VERSION ""

NS_ :

BS_:

BU_: Tester TirePressureController
VAL_TABLE_ FMI 0 "Above normal (most severe)" 1 "Below normal (most severe)" 2 "Data erratic" 3 "Voltage above normal" 4 "Voltage below normal" 5 "Current below normal" 6 "Current above normal" 7 "Mechanical system not responding" 8 "Abnormal frequency" 9 "Abnormal update rate" 10 "Abnormal rate of change" 11 "Root cause not known" 12 "Bad intelligent device" 13 "Out of calibration" 14 "Special intstructions" 15 "Above normal (least severe)" 16 "Above normal (moderately severe)" 17 "Below normal (least severe)" 18 "Below normal (moderately severe)" 19 "Received network data in error" 20 "Data drifted high" 21 "Data drifted low" 31 "Condition exists" ;

BO_ 2565799678 AC: 8 TirePressureController
 SG_ VehicleSystem5 m5 : 49|7@1+ (1,0) [0|127] "" Vector__XXX
 SG_ VehicleSystem4 m4 : 49|7@1+ (1,0) [0|127] "" Vector__XXX
 SG_ VehicleSystem3 m3 : 49|7@1+ (1,0) [0|127] "" Vector__XXX
 SG_ VehicleSystem2 m2 : 49|7@1+ (1,0) [0|127] "" Vector__XXX
 SG_ VehicleSystem1 m1 : 49|7@1+ (1,0) [0|127] "" Vector__XXX
 SG_ VehicleSystem m0 : 49|7@1+ (1,0) [0|127] "" Vector__XXX
 SG_ ReservedBit : 48|1@1+ (1,0) [0|0] "" Vector__XXX
 SG_ ArbitraryAddressCapable : 63|1@1+ (1,0) [0|1] "" Vector__XXX
 SG_ IndustryGroup M : 60|3@1+ (1,0) [0|7] "" Vector__XXX
 SG_ VehicleSystemInstance : 56|4@1+ (1,0) [0|15] "" Vector__XXX
 SG_ Function : 40|8@1+ (1,0) [0|255] "" Vector__XXX
 SG_ FunctionInstance : 35|5@1+ (1,0) [0|31] "" Vector__XXX
 SG_ ECUInstance : 32|3@1+ (1,0) [0|7] "" Vector__XXX
 SG_ ManufacturerCode : 21|11@1+ (1,0) [0|2047] "" Vector__XXX
 SG_ IdentityNumber : 0|21@1+ (1,0) [0|2097152] "" Vector__XXX

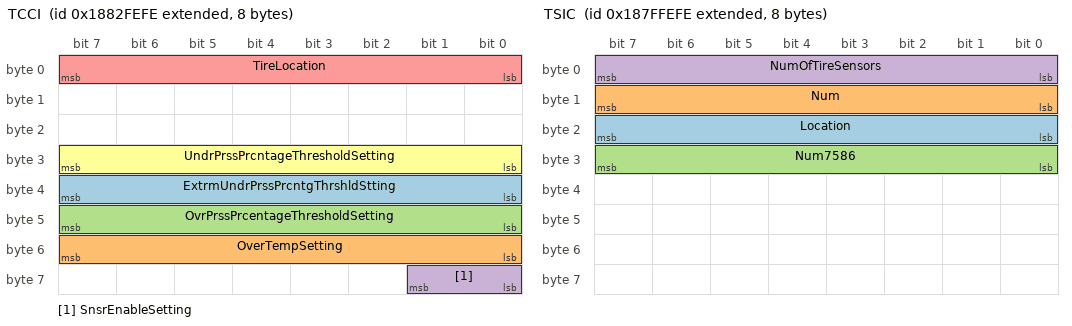
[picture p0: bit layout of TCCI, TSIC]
BO_ 2558721790 TCCI: 8 TirePressureController
 SG_ ExtrmUndrPrssPrcntgThrshldStting : 32|8@1+ (0.5,0) [0|125] "%" Vector__XXX
 SG_ OverTempSetting : 48|8@1+ (1,-40) [-40|210] "°C" Vector__XXX
 SG_ OvrPrssPrcentageThresholdSetting : 40|8@1+ (0.5,0) [0|125] "%" Vector__XXX
 SG_ SnsrEnableSetting : 56|2@1+ (1,0) [0|3] "" Vector__XXX
 SG_ TireLocation : 0|8@1+ (1,0) [0|255] "" Vector__XXX
 SG_ UndrPrssPrcntageThresholdSetting : 24|8@1+ (0.5,0) [0|125] "%" Vector__XXX

BO_ 2558525182 TSIC: 8 TirePressureController
 SG_ Location : 16|8@1+ (1,0) [0|255] "" Vector__XXX
 SG_ Num : 8|8@1+ (1,0) [0|250] "" Vector__XXX
 SG_ Num7586 : 24|8@1+ (1,0) [0|255] "" Vector__XXX
 SG_ NumOfTireSensors : 0|8@1+ (1,0) [0|250] "" Vector__XXX

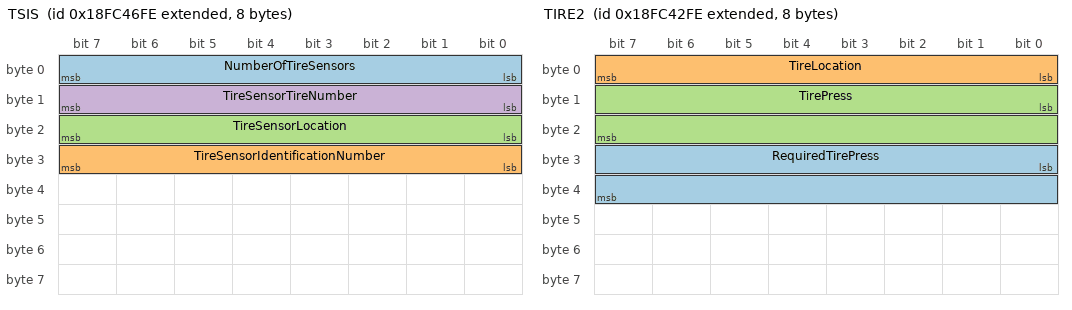
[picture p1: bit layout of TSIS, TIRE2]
BO_ 2566670078 TSIS: 8 TirePressureController
 SG_ NumberOfTireSensors : 0|8@1+ (1,0) [0|250] "" Vector__XXX
 SG_ TireSensorIdentificationNumber : 24|8@1+ (1,0) [0|255] "" Vector__XXX
 SG_ TireSensorLocation : 16|8@1+ (1,0) [0|255] "" Vector__XXX
 SG_ TireSensorTireNumber : 8|8@1+ (1,0) [0|250] "" Vector__XXX

BO_ 2566669054 TIRE2: 8 TirePressureController
 SG_ RequiredTirePress : 24|16@1+ (1,0) [0|64255] "kPa" Vector__XXX
 SG_ TireLocation : 0|8@1+ (1,0) [0|255] "" Vector__XXX
 SG_ TirePress : 8|16@1+ (1,0) [0|64255] "kPa" Vector__XXX

BO_ 2566836734 DM09: 8 TirePressureController

BO_ 2566702846 DM57: 8 TirePressureController
 SG_ EngOBDWarmUpSequence : 0|2@1+ (1,0) [0|3] "" Vector__XXX

BO_ 2566703102 DM56: 208 TirePressureController
 SG_ CertificationEngineFamilyName : 64|64@1+ (1,0) [0|255] "" Vector__XXX
 SG_ ModelYear : 0|64@1+ (1,0) [0|255] "" Vector__XXX

BO_ 2566705918 DM54: 22 TirePressureController
 SG_ AmberWarningLampStatus : 2|2@1+ (1,0) [0|3] "" Vector__XXX
 SG_ DTC1 : 16|32@1+ (1,0) [0|4294967295] "" Vector__XXX
 SG_ DTC2 : 48|32@1+ (1,0) [0|4294967295] "" Vector__XXX
 SG_ DTC3 : 80|32@1+ (1,0) [0|4294967295] "" Vector__XXX
 SG_ DTC4 : 112|32@1+ (1,0) [0|4294967295] "" Vector__XXX
 SG_ DTC5 : 144|32@1+ (1,0) [0|4294967295] "" Vector__XXX
 SG_ FlashAmberWarningLamp : 10|2@1+ (1,0) [0|3] "" Vector__XXX
 SG_ FlashMalfuncIndicatorLamp : 14|2@1+ (1,0) [0|3] "" Vector__XXX
 SG_ FlashProtectLamp : 8|2@1+ (1,0) [0|3] "" Vector__XXX
 SG_ FlashRedStopLamp : 12|2@1+ (1,0) [0|3] "" Vector__XXX
 SG_ MalfunctionIndicatorLampStatus : 6|2@1+ (1,0) [0|3] "" Vector__XXX
 SG_ ProtectLampStatus : 0|2@1+ (1,0) [0|3] "" Vector__XXX
 SG_ RedStopLampState : 4|2@1+ (1,0) [0|3] "" Vector__XXX

BO_ 2566705662 DM53: 22 TirePressureController
 SG_ AmberWarningLampStatus : 2|2@1+ (1,0) [0|3] "" Vector__XXX
 SG_ DTC1 : 16|32@1+ (1,0) [0|4294967295] "" Vector__XXX
 SG_ DTC2 : 48|32@1+ (1,0) [0|4294967295] "" Vector__XXX
 SG_ DTC3 : 80|32@1+ (1,0) [0|4294967295] "" Vector__XXX
 SG_ DTC4 : 112|32@1+ (1,0) [0|4294967295] "" Vector__XXX
 SG_ DTC5 : 144|32@1+ (1,0) [0|4294967295] "" Vector__XXX
 SG_ FlashAmberWarningLamp : 10|2@1+ (1,0) [0|3] "" Vector__XXX
 SG_ FlashMalfuncIndicatorLamp : 14|2@1+ (1,0) [0|3] "" Vector__XXX
 SG_ FlashProtectLamp : 8|2@1+ (1,0) [0|3] "" Vector__XXX
 SG_ FlashRedStopLamp : 12|2@1+ (1,0) [0|3] "" Vector__XXX
 SG_ MalfunctionIndicatorLampStatus : 6|2@1+ (1,0) [0|3] "" Vector__XXX
 SG_ ProtectLampStatus : 0|2@1+ (1,0) [0|3] "" Vector__XXX
 SG_ RedStopLampState : 4|2@1+ (1,0) [0|3] "" Vector__XXX

BO_ 2566706174 DM55: 0 TirePressureController

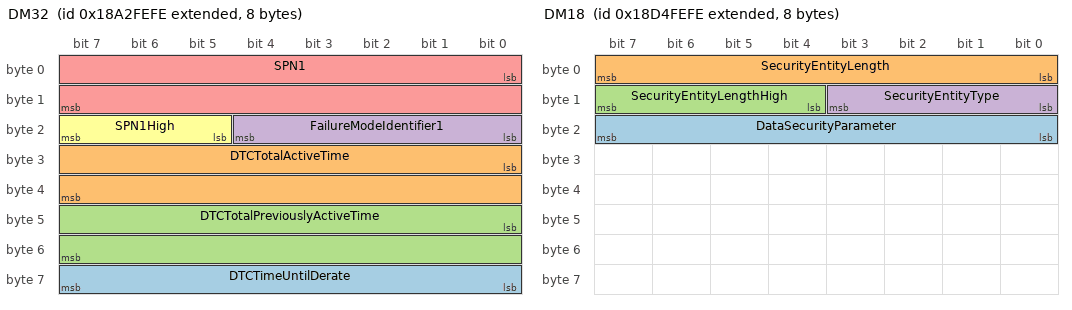
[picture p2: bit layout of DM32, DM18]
BO_ 2560818942 DM32: 8 TirePressureController
 SG_ DTCTimeUntilDerate : 56|8@1+ (0.25,0) [0|62.5] "hr" Vector__XXX
 SG_ DTCTotalActiveTime : 24|16@1+ (0.2,0) [0|12851] "hr" Vector__XXX
 SG_ DTCTotalPreviouslyActiveTime : 40|16@1+ (0.2,0) [0|12851] "hr" Vector__XXX
 SG_ FailureModeIdentifier1 : 16|5@1+ (1,0) [0|0] "" Vector__XXX
 SG_ SPN1 : 0|16@1+ (1,0) [0|65536] "" Vector__XXX
 SG_ SPN1High : 21|3@1+ (1,0) [0|7] "" Vector__XXX

BO_ 2566764798 DM26: 8 TirePressureController
 SG_ ACSystemRefrigerantMonComplete : 52|1@1+ (1,0) [0|1] "" Vector__XXX
 SG_ ACSystemRefrigerantMonEnabled : 36|1@1+ (1,0) [0|1] "" Vector__XXX
 SG_ CatalystMonComplete : 48|1@1+ (1,0) [0|1] "" Vector__XXX
 SG_ CatalystMonEnabled : 32|1@1+ (1,0) [0|1] "" Vector__XXX
 SG_ ColdStartAidSystemMonComplete : 56|1@1+ (1,0) [0|1] "" Vector__XXX
 SG_ ColdStartAidSystemMonEnabled : 40|1@1+ (1,0) [0|1] "" Vector__XXX
 SG_ ComprehensiveCompMonEnabled : 26|1@1+ (1,0) [0|1] "" Vector__XXX
 SG_ ComprehensiveComptMonComplete : 30|1@1+ (1,0) [0|1] "" Vector__XXX
 SG_ DieselParticulateFilterCompleted : 58|1@1+ (1,0) [0|1] "" Vector__XXX
 SG_ DieselParticulateFilterEnabled : 42|1@1+ (1,0) [0|1] "" Vector__XXX
 SG_ EGRSystemMonitoringComplete : 55|1@1+ (1,0) [0|1] "" Vector__XXX
 SG_ EGRSystemMonitoringEnabled : 39|1@1+ (1,0) [0|1] "" Vector__XXX
 SG_ EvaporativeSystemMonComplete : 50|1@1+ (1,0) [0|1] "" Vector__XXX
 SG_ EvaporativeSystemMonEnabled : 34|1@1+ (1,0) [0|1] "" Vector__XXX
 SG_ FuelSystemMonitoringComplete : 29|1@1+ (1,0) [0|1] "" Vector__XXX
 SG_ FuelSystemMonitoringEnabled : 25|1@1+ (1,0) [0|1] "" Vector__XXX
 SG_ HeatedCatalystMonComplete : 49|1@1+ (1,0) [0|1] "" Vector__XXX
 SG_ HeatedCatalystMonEnabled : 33|1@1+ (1,0) [0|1] "" Vector__XXX
 SG_ MisfireMonitoringComplete : 28|1@1+ (1,0) [0|1] "" Vector__XXX
 SG_ MisfireMonitoringEnabled : 24|1@1+ (1,0) [0|0] "" Vector__XXX
 SG_ NMHCConvertingCatalystCompleted : 60|1@1+ (1,0) [0|1] "" Vector__XXX
 SG_ NMHCConvertingCatalystEnabled : 44|1@1+ (1,0) [0|1] "" Vector__XXX
 SG_ NOxConvertingCatalstAdsrbrCmpltd : 59|1@1+ (1,0) [0|1] "" Vector__XXX
 SG_ NumOfWarmUpsSinceDTCsCleared : 16|8@1+ (1,0) [0|250] "" Vector__XXX
 SG_ OxygenSensorHeaterMonComplete : 54|1@1+ (1,0) [0|1] "" Vector__XXX
 SG_ OxygenSensorHeaterMonEnabled : 38|1@1+ (1,0) [0|1] "" Vector__XXX
 SG_ OxygenSensorMonComplete : 53|1@1+ (1,0) [0|1] "" Vector__XXX
 SG_ OxygenSensorMonEnabled : 37|1@1+ (1,0) [0|1] "" Vector__XXX
 SG_ SecondAirSystemMonComplete : 51|1@1+ (1,0) [0|1] "" Vector__XXX
 SG_ SecondAirSystemMonEnabled : 35|1@1+ (1,0) [0|1] "" Vector__XXX
 SG_ TimeSinceEngineStart : 0|16@1+ (1,0) [0|64255] "s" Vector__XXX

BO_ 2564095742 DM18: 8 TirePressureController
 SG_ DataSecurityParameter : 16|8@1+ (1,0) [0|0] "" Vector__XXX
 SG_ SecurityEntityLength : 0|8@1+ (1,0) [0|4095] "" Vector__XXX
 SG_ SecurityEntityLengthHigh : 12|4@1+ (1,0) [0|255] "Byte" Vector__XXX
 SG_ SecurityEntityType : 8|4@1+ (1,0) [0|15] "" Vector__XXX

BO_ 2561605374 TPRS: 8 TirePressureController
 SG_ ReferenceTirePressSetting_00 m0 : 8|8@1+ (8,0) [0|2000] "kPa" Vector__XXX
 SG_ ReferenceTirePressSetting_01 m1 : 8|8@1+ (8,0) [0|2000] "kPa" Vector__XXX
 SG_ ReferenceTirePressSetting_10 m16 : 8|8@1+ (8,0) [0|2000] "kPa" Vector__XXX
 SG_ ReferenceTirePressSetting_11 m17 : 8|8@1+ (8,0) [0|2000] "kPa" Vector__XXX
 SG_ ReferenceTirePressSetting_12 m18 : 8|8@1+ (8,0) [0|2000] "kPa" Vector__XXX
 SG_ ReferenceTirePressSetting_13 m19 : 8|8@1+ (8,0) [0|2000] "kPa" Vector__XXX
 SG_ ReferenceTirePressSetting_20 m32 : 8|8@1+ (8,0) [0|2000] "kPa" Vector__XXX
 SG_ ReferenceTirePressSetting_21 m33 : 8|8@1+ (8,0) [0|2000] "kPa" Vector__XXX
 SG_ ReferenceTirePressSetting_22 m34 : 8|8@1+ (8,0) [0|2000] "kPa" Vector__XXX
 SG_ ReferenceTirePressSetting_23 m35 : 8|8@1+ (8,0) [0|2000] "kPa" Vector__XXX
 SG_ ReferenceTirePressSetting_30 m48 : 8|8@1+ (8,0) [0|2000] "kPa" Vector__XXX
 SG_ ReferenceTirePressSetting_31 m49 : 8|8@1+ (8,0) [0|2000] "kPa" Vector__XXX
 SG_ ReferenceTirePressSetting_32 m50 : 8|8@1+ (8,0) [0|2000] "kPa" Vector__XXX
 SG_ ReferenceTirePressSetting_33 m51 : 8|8@1+ (8,0) [0|2000] "kPa" Vector__XXX
 SG_ TireLocation M : 0|8@1+ (1,0) [0|255] "" Vector__XXX

BO_ 2566765054 TPRI: 8 TirePressureController
 SG_ ReferenceTirePress_00 m0 : 8|8@1+ (8,0) [0|2000] "kPa" Vector__XXX
 SG_ ReferenceTirePress_01 m1 : 8|8@1+ (8,0) [0|2000] "kPa" Vector__XXX
 SG_ ReferenceTirePress_10 m16 : 8|8@1+ (8,0) [0|2000] "kPa" Vector__XXX
 SG_ ReferenceTirePress_11 m17 : 8|8@1+ (8,0) [0|2000] "kPa" Vector__XXX
 SG_ ReferenceTirePress_12 m18 : 8|8@1+ (8,0) [0|2000] "kPa" Vector__XXX
 SG_ ReferenceTirePress_13 m19 : 8|8@1+ (8,0) [0|2000] "kPa" Vector__XXX
 SG_ ReferenceTirePress_20 m32 : 8|8@1+ (8,0) [0|2000] "kPa" Vector__XXX
 SG_ ReferenceTirePress_21 m33 : 8|8@1+ (8,0) [0|2000] "kPa" Vector__XXX
 SG_ ReferenceTirePress_22 m34 : 8|8@1+ (8,0) [0|2000] "kPa" Vector__XXX
 SG_ ReferenceTirePress_23 m35 : 8|8@1+ (8,0) [0|2000] "kPa" Vector__XXX
 SG_ ReferenceTirePress_30 m48 : 8|8@1+ (8,0) [0|2000] "kPa" Vector__XXX
 SG_ ReferenceTirePress_31 m49 : 8|8@1+ (8,0) [0|2000] "kPa" Vector__XXX
 SG_ ReferenceTirePress_32 m50 : 8|8@1+ (8,0) [0|2000] "kPa" Vector__XXX
 SG_ ReferenceTirePress_33 m51 : 8|8@1+ (8,0) [0|2000] "kPa" Vector__XXX
 SG_ TireLocation M : 0|8@1+ (1,0) [0|255] "" Vector__XXX

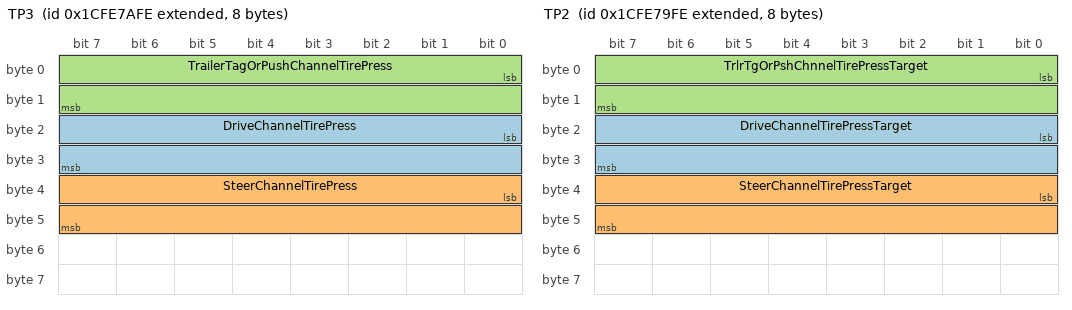
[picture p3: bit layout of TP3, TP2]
BO_ 2633923326 TP3: 8 TirePressureController
 SG_ DriveChannelTirePress : 16|16@1+ (0.5,0) [0|32127.5] "kPa" Vector__XXX
 SG_ SteerChannelTirePress : 32|16@1+ (0.5,0) [0|32127.5] "kPa" Vector__XXX
 SG_ TrailerTagOrPushChannelTirePress : 0|16@1+ (0.5,0) [0|32127.5] "kPa" Vector__XXX

BO_ 2633923070 TP2: 8 TirePressureController
 SG_ DriveChannelTirePressTarget : 16|16@1+ (0.5,0) [0|32127.5] "kPa" Vector__XXX
 SG_ SteerChannelTirePressTarget : 32|16@1+ (0.5,0) [0|32127.5] "kPa" Vector__XXX
 SG_ TrlrTgOrPshChnnelTirePressTarget : 0|16@1+ (0.5,0) [0|32127.5] "kPa" Vector__XXX

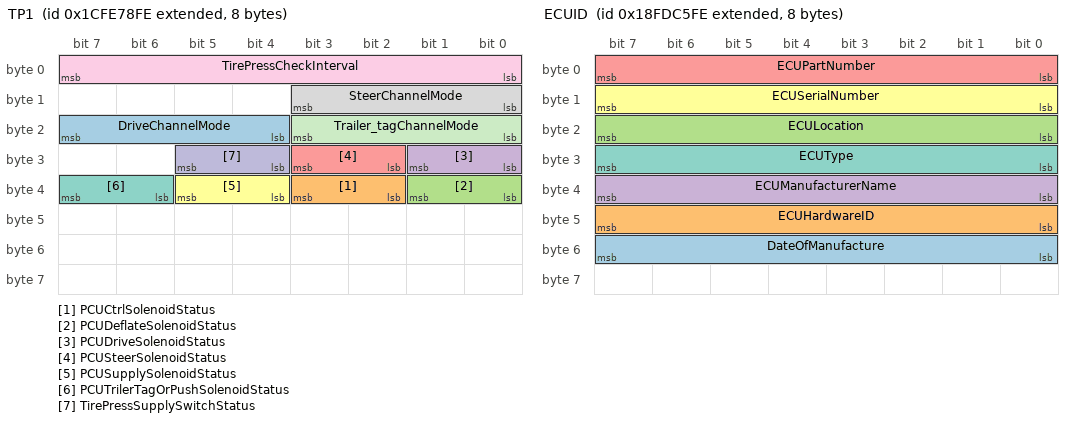
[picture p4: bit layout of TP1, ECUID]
BO_ 2633922814 TP1: 8 TirePressureController
 SG_ DriveChannelMode : 20|4@1+ (1,0) [0|15] "" Vector__XXX
 SG_ PCUCtrlSolenoidStatus : 34|2@1+ (1,0) [0|3] "" Vector__XXX
 SG_ PCUDeflateSolenoidStatus : 32|2@1+ (1,0) [0|3] "" Vector__XXX
 SG_ PCUDriveSolenoidStatus : 24|2@1+ (1,0) [0|3] "" Vector__XXX
 SG_ PCUSteerSolenoidStatus : 26|2@1+ (1,0) [0|3] "" Vector__XXX
 SG_ PCUSupplySolenoidStatus : 36|2@1+ (1,0) [0|3] "" Vector__XXX
 SG_ PCUTrilerTagOrPushSolenoidStatus : 38|2@1+ (1,0) [0|3] "" Vector__XXX
 SG_ SteerChannelMode : 8|4@1+ (1,0) [0|15] "" Vector__XXX
 SG_ TirePressCheckInterval : 0|8@1+ (1,0) [0|250] "min" Vector__XXX
 SG_ TirePressSupplySwitchStatus : 28|2@1+ (1,0) [0|3] "" Vector__XXX
 SG_ Trailer_tagChannelMode : 16|4@1+ (1,0) [0|15] "" Vector__XXX

BO_ 2566845694 TIRE1: 8 TirePressureController
 SG_ CTITireStatus_00 m0 : 34|2@1+ (1,0) [0|3] "" Vector__XXX
 SG_ CTITireStatus_01 m1 : 34|2@1+ (1,0) [0|3] "" Vector__XXX
 SG_ CTITireStatus_10 m16 : 34|2@1+ (1,0) [0|3] "" Vector__XXX
 SG_ CTITireStatus_11 m17 : 34|2@1+ (1,0) [0|3] "" Vector__XXX
 SG_ CTITireStatus_12 m18 : 34|2@1+ (1,0) [0|3] "" Vector__XXX
 SG_ CTITireStatus_13 m19 : 34|2@1+ (1,0) [0|3] "" Vector__XXX
 SG_ CTITireStatus_20 m32 : 34|2@1+ (1,0) [0|3] "" Vector__XXX
 SG_ CTITireStatus_21 m33 : 34|2@1+ (1,0) [0|3] "" Vector__XXX
 SG_ CTITireStatus_22 m34 : 34|2@1+ (1,0) [0|3] "" Vector__XXX
 SG_ CTITireStatus_23 m35 : 34|2@1+ (1,0) [0|3] "" Vector__XXX
 SG_ CTITireStatus_30 m48 : 34|2@1+ (1,0) [0|3] "" Vector__XXX
 SG_ CTITireStatus_31 m49 : 34|2@1+ (1,0) [0|3] "" Vector__XXX
 SG_ CTITireStatus_32 m50 : 34|2@1+ (1,0) [0|3] "" Vector__XXX
 SG_ CTITireStatus_33 m51 : 34|2@1+ (1,0) [0|3] "" Vector__XXX
 SG_ CTIWheelEndElectricalFault_00 m0 : 36|2@1+ (1,0) [0|3] "" Vector__XXX
 SG_ CTIWheelEndElectricalFault_01 m1 : 36|2@1+ (1,0) [0|3] "" Vector__XXX
 SG_ CTIWheelEndElectricalFault_10 m16 : 36|2@1+ (1,0) [0|3] "" Vector__XXX
 SG_ CTIWheelEndElectricalFault_11 m17 : 36|2@1+ (1,0) [0|3] "" Vector__XXX
 SG_ CTIWheelEndElectricalFault_12 m18 : 36|2@1+ (1,0) [0|3] "" Vector__XXX
 SG_ CTIWheelEndElectricalFault_13 m19 : 36|2@1+ (1,0) [0|3] "" Vector__XXX
 SG_ CTIWheelEndElectricalFault_20 m32 : 36|2@1+ (1,0) [0|3] "" Vector__XXX
 SG_ CTIWheelEndElectricalFault_21 m33 : 36|2@1+ (1,0) [0|3] "" Vector__XXX
 SG_ CTIWheelEndElectricalFault_22 m34 : 36|2@1+ (1,0) [0|3] "" Vector__XXX
 SG_ CTIWheelEndElectricalFault_23 m35 : 36|2@1+ (1,0) [0|3] "" Vector__XXX
 SG_ CTIWheelEndElectricalFault_30 m48 : 36|2@1+ (1,0) [0|3] "" Vector__XXX
 SG_ CTIWheelEndElectricalFault_31 m49 : 36|2@1+ (1,0) [0|3] "" Vector__XXX
 SG_ CTIWheelEndElectricalFault_32 m50 : 36|2@1+ (1,0) [0|3] "" Vector__XXX
 SG_ CTIWheelEndElectricalFault_33 m51 : 36|2@1+ (1,0) [0|3] "" Vector__XXX
 SG_ CTIWheelSensorStatus_00 m0 : 32|2@1+ (1,0) [0|3] "" Vector__XXX
 SG_ CTIWheelSensorStatus_01 m1 : 32|2@1+ (1,0) [0|3] "" Vector__XXX
 SG_ CTIWheelSensorStatus_10 m16 : 32|2@1+ (1,0) [0|3] "" Vector__XXX
 SG_ CTIWheelSensorStatus_11 m17 : 32|2@1+ (1,0) [0|3] "" Vector__XXX
 SG_ CTIWheelSensorStatus_12 m18 : 32|2@1+ (1,0) [0|3] "" Vector__XXX
 SG_ CTIWheelSensorStatus_13 m19 : 32|2@1+ (1,0) [0|3] "" Vector__XXX
 SG_ CTIWheelSensorStatus_20 m32 : 32|2@1+ (1,0) [0|3] "" Vector__XXX
 SG_ CTIWheelSensorStatus_21 m33 : 32|2@1+ (1,0) [0|3] "" Vector__XXX
 SG_ CTIWheelSensorStatus_22 m34 : 32|2@1+ (1,0) [0|3] "" Vector__XXX
 SG_ CTIWheelSensorStatus_23 m35 : 32|2@1+ (1,0) [0|3] "" Vector__XXX
 SG_ CTIWheelSensorStatus_30 m48 : 32|2@1+ (1,0) [0|3] "" Vector__XXX
 SG_ CTIWheelSensorStatus_31 m49 : 32|2@1+ (1,0) [0|3] "" Vector__XXX
 SG_ CTIWheelSensorStatus_32 m50 : 32|2@1+ (1,0) [0|3] "" Vector__XXX
 SG_ CTIWheelSensorStatus_33 m51 : 32|2@1+ (1,0) [0|3] "" Vector__XXX
 SG_ ExTirePressSupport : 38|2@1+ (1,0) [0|3] "" Vector__XXX
 SG_ TireAirLeakageRate_00 m0 : 40|16@1+ (0.1,0) [0|6425.5] "Pa/s" Vector__XXX
 SG_ TireAirLeakageRate_01 m1 : 40|16@1+ (0.1,0) [0|6425.5] "Pa/s" Vector__XXX
 SG_ TireAirLeakageRate_10 m16 : 40|16@1+ (0.1,0) [0|6425.5] "Pa/s" Vector__XXX
 SG_ TireAirLeakageRate_11 m17 : 40|16@1+ (0.1,0) [0|6425.5] "Pa/s" Vector__XXX
 SG_ TireAirLeakageRate_12 m18 : 40|16@1+ (0.1,0) [0|6425.5] "Pa/s" Vector__XXX
 SG_ TireAirLeakageRate_13 m19 : 40|16@1+ (0.1,0) [0|6425.5] "Pa/s" Vector__XXX
 SG_ TireAirLeakageRate_20 m32 : 40|16@1+ (0.1,0) [0|6425.5] "Pa/s" Vector__XXX
 SG_ TireAirLeakageRate_21 m33 : 40|16@1+ (0.1,0) [0|6425.5] "Pa/s" Vector__XXX
 SG_ TireAirLeakageRate_22 m34 : 40|16@1+ (0.1,0) [0|6425.5] "Pa/s" Vector__XXX
 SG_ TireAirLeakageRate_23 m35 : 40|16@1+ (0.1,0) [0|6425.5] "Pa/s" Vector__XXX
 SG_ TireAirLeakageRate_30 m48 : 40|16@1+ (0.1,0) [0|6425.5] "Pa/s" Vector__XXX
 SG_ TireAirLeakageRate_31 m49 : 40|16@1+ (0.1,0) [0|6425.5] "Pa/s" Vector__XXX
 SG_ TireAirLeakageRate_32 m50 : 40|16@1+ (0.1,0) [0|6425.5] "Pa/s" Vector__XXX
 SG_ TireAirLeakageRate_33 m51 : 40|16@1+ (0.1,0) [0|6425.5] "Pa/s" Vector__XXX
 SG_ TireLocation M : 0|8@1+ (1,0) [0|255] "" Vector__XXX
 SG_ TirePress_00 m0 : 8|8@1+ (4,0) [0|1000] "kPa" Vector__XXX
 SG_ TirePress_01 m1 : 8|8@1+ (4,0) [0|1000] "kPa" Vector__XXX
 SG_ TirePress_10 m16 : 8|8@1+ (4,0) [0|1000] "kPa" Vector__XXX
 SG_ TirePress_11 m17 : 8|8@1+ (4,0) [0|1000] "kPa" Vector__XXX
 SG_ TirePress_12 m18 : 8|8@1+ (4,0) [0|1000] "kPa" Vector__XXX
 SG_ TirePress_13 m19 : 8|8@1+ (4,0) [0|1000] "kPa" Vector__XXX
 SG_ TirePress_20 m32 : 8|8@1+ (4,0) [0|1000] "kPa" Vector__XXX
 SG_ TirePress_21 m33 : 8|8@1+ (4,0) [0|1000] "kPa" Vector__XXX
 SG_ TirePress_22 m34 : 8|8@1+ (4,0) [0|1000] "kPa" Vector__XXX
 SG_ TirePress_23 m35 : 8|8@1+ (4,0) [0|1000] "kPa" Vector__XXX
 SG_ TirePress_30 m48 : 8|8@1+ (4,0) [0|1000] "kPa" Vector__XXX
 SG_ TirePress_31 m49 : 8|8@1+ (4,0) [0|1000] "kPa" Vector__XXX
 SG_ TirePress_32 m50 : 8|8@1+ (4,0) [0|1000] "kPa" Vector__XXX
 SG_ TirePress_33 m51 : 8|8@1+ (4,0) [0|1000] "kPa" Vector__XXX
 SG_ TirePressThresholdDetection_00 m0 : 61|3@1+ (1,0) [0|7] "" Vector__XXX
 SG_ TirePressThresholdDetection_01 m1 : 61|3@1+ (1,0) [0|7] "" Vector__XXX
 SG_ TirePressThresholdDetection_10 m16 : 61|3@1+ (1,0) [0|7] "" Vector__XXX
 SG_ TirePressThresholdDetection_11 m17 : 61|3@1+ (1,0) [0|7] "" Vector__XXX
 SG_ TirePressThresholdDetection_12 m18 : 61|3@1+ (1,0) [0|7] "" Vector__XXX
 SG_ TirePressThresholdDetection_13 m19 : 61|3@1+ (1,0) [0|7] "" Vector__XXX
 SG_ TirePressThresholdDetection_20 m32 : 61|3@1+ (1,0) [0|7] "" Vector__XXX
 SG_ TirePressThresholdDetection_21 m33 : 61|3@1+ (1,0) [0|7] "" Vector__XXX
 SG_ TirePressThresholdDetection_22 m34 : 61|3@1+ (1,0) [0|7] "" Vector__XXX
 SG_ TirePressThresholdDetection_23 m35 : 61|3@1+ (1,0) [0|7] "" Vector__XXX
 SG_ TirePressThresholdDetection_30 m48 : 61|3@1+ (1,0) [0|7] "" Vector__XXX
 SG_ TirePressThresholdDetection_31 m49 : 61|3@1+ (1,0) [0|7] "" Vector__XXX
 SG_ TirePressThresholdDetection_32 m50 : 61|3@1+ (1,0) [0|7] "" Vector__XXX
 SG_ TirePressThresholdDetection_33 m51 : 61|3@1+ (1,0) [0|7] "" Vector__XXX
 SG_ TireTemp_00 m0 : 16|16@1+ (0.03125,-273) [-273|1735] "°C" Vector__XXX
 SG_ TireTemp_01 m1 : 16|16@1+ (0.03125,-273) [-273|1735] "°C" Vector__XXX
 SG_ TireTemp_10 m16 : 16|16@1+ (0.03125,-273) [-273|1735] "°C" Vector__XXX
 SG_ TireTemp_11 m17 : 16|16@1+ (0.03125,-273) [-273|1735] "°C" Vector__XXX
 SG_ TireTemp_12 m18 : 16|16@1+ (0.03125,-273) [-273|1735] "°C" Vector__XXX
 SG_ TireTemp_13 m19 : 16|16@1+ (0.03125,-273) [-273|1735] "°C" Vector__XXX
 SG_ TireTemp_20 m32 : 16|16@1+ (0.03125,-273) [-273|1735] "°C" Vector__XXX
 SG_ TireTemp_21 m33 : 16|16@1+ (0.03125,-273) [-273|1735] "°C" Vector__XXX
 SG_ TireTemp_22 m34 : 16|16@1+ (0.03125,-273) [-273|1735] "°C" Vector__XXX
 SG_ TireTemp_23 m35 : 16|16@1+ (0.03125,-273) [-273|1735] "°C" Vector__XXX
 SG_ TireTemp_30 m48 : 16|16@1+ (0.03125,-273) [-273|1735] "°C" Vector__XXX
 SG_ TireTemp_31 m49 : 16|16@1+ (0.03125,-273) [-273|1735] "°C" Vector__XXX
 SG_ TireTemp_32 m50 : 16|16@1+ (0.03125,-273) [-273|1735] "°C" Vector__XXX
 SG_ TireTemp_33 m51 : 16|16@1+ (0.03125,-273) [-273|1735] "°C" Vector__XXX

BO_ 2566839038 SOFT: 8 TirePressureController
 SG_ NmbrOfSftwreIdentificationFields : 0|8@1+ (1,0) [0|125] "step" Vector__XXX
 SG_ SoftwareIdentification : 8|8@1+ (1,0) [0|255] "" Vector__XXX

BO_ 2566768126 ECUID: 8 TirePressureController
 SG_ DateOfManufacture : 48|8@1+ (1,0) [0|255] "" Vector__XXX
 SG_ ECUHardwareID : 40|8@1+ (1,0) [0|255] "" Vector__XXX
 SG_ ECULocation : 16|8@1+ (1,0) [0|255] "" Vector__XXX
 SG_ ECUManufacturerName : 32|8@1+ (1,0) [0|255] "" Vector__XXX
 SG_ ECUPartNumber : 0|8@1+ (1,0) [0|255] "" Vector__XXX
 SG_ ECUSerialNumber : 8|8@1+ (1,0) [0|255] "" Vector__XXX
 SG_ ECUType : 24|8@1+ (1,0) [0|255] "" Vector__XXX

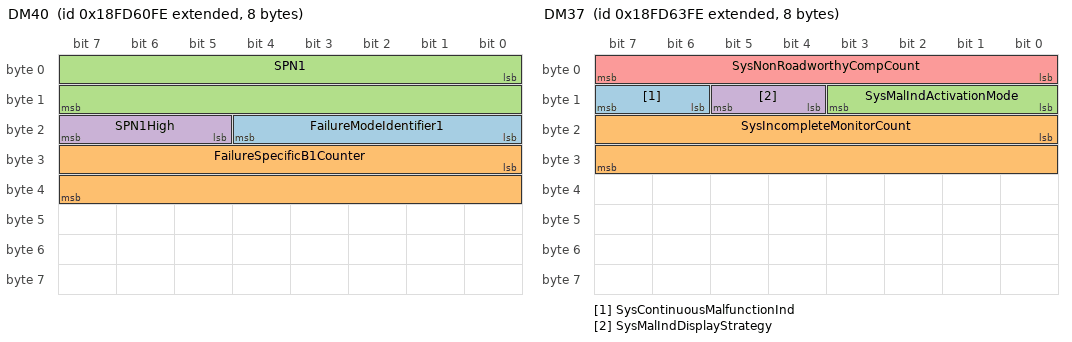
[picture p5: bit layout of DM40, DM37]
BO_ 2566742270 DM40: 8 TirePressureController
 SG_ FailureModeIdentifier1 : 16|5@1+ (1,0) [0|0] "" Vector__XXX
 SG_ FailureSpecificB1Counter : 24|16@1+ (0.1,0) [0|6425.5] "hr" Vector__XXX
 SG_ SPN1 : 0|16@1+ (1,0) [0|65536] "" Vector__XXX
 SG_ SPN1High : 21|3@1+ (1,0) [0|7] "" Vector__XXX

BO_ 2566742526 DM39: 8 TirePressureController
 SG_ SysCumulativeContinuousMITime : 0|32@1+ (0.05,0) [0|210554060.75] "hr" Vector__XXX
 SG_ SysGreatestB1Counter : 32|16@1+ (0.1,0) [0|6425.5] "hr" Vector__XXX

BO_ 2566742782 DM38: 8 TirePressureController
 SG_ RegulationDescription : 0|8@1+ (1,0) [0|255] "" Vector__XXX

BO_ 2566743038 DM37: 8 TirePressureController
 SG_ SysContinuousMalfunctionInd : 14|2@1+ (1,0) [0|3] "" Vector__XXX
 SG_ SysIncompleteMonitorCount : 16|16@1+ (1,0) [0|64512] "" Vector__XXX
 SG_ SysMalIndActivationMode : 8|4@1+ (1,0) [0|15] "" Vector__XXX
 SG_ SysMalIndDisplayStrategy : 12|2@1+ (1,0) [0|3] "" Vector__XXX
 SG_ SysNonRoadworthyCompCount : 0|8@1+ (1,0) [0|250] "" Vector__XXX

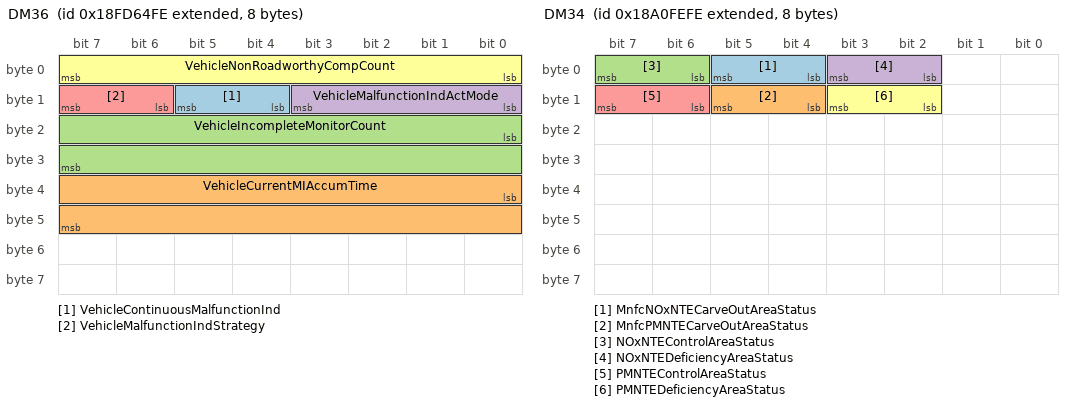
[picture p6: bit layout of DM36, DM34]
BO_ 2566743294 DM36: 8 TirePressureController
 SG_ VehicleContinuousMalfunctionInd : 12|2@1+ (1,0) [0|3] "" Vector__XXX
 SG_ VehicleCurrentMIAccumTime : 32|16@1+ (1,0) [0|64255] "min" Vector__XXX
 SG_ VehicleIncompleteMonitorCount : 16|16@1+ (1,0) [0|64255] "" Vector__XXX
 SG_ VehicleMalfunctionIndActMode : 8|4@1+ (1,0) [0|15] "" Vector__XXX
 SG_ VehicleMalfunctionIndStrategy : 14|2@1+ (1,0) [0|3] "" Vector__XXX
 SG_ VehicleNonRoadworthyCompCount : 0|8@1+ (1,0) [0|250] "" Vector__XXX

BO_ 2560687870 DM34: 8 TirePressureController
 SG_ MnfcNOxNTECarveOutAreaStatus : 4|2@1+ (1,0) [0|3] "" Vector__XXX
 SG_ MnfcPMNTECarveOutAreaStatus : 12|2@1+ (1,0) [0|3] "" Vector__XXX
 SG_ NOxNTEControlAreaStatus : 6|2@1+ (1,0) [0|3] "" Vector__XXX
 SG_ NOxNTEDeficiencyAreaStatus : 2|2@1+ (1,0) [0|3] "" Vector__XXX
 SG_ PMNTEControlAreaStatus : 14|2@1+ (1,0) [0|3] "" Vector__XXX
 SG_ PMNTEDeficiencyAreaStatus : 10|2@1+ (1,0) [0|3] "" Vector__XXX

BO_ 2292317950 DM33: 9 TirePressureController
 SG_ AECDEngineHours1Timer1 : 8|32@1+ (1,0) [0|4294967295] "min" Vector__XXX
 SG_ AECDEngineHours1Timer2 : 40|32@1+ (1,0) [0|4294967295] "min" Vector__XXX
 SG_ AECDNumber1 : 0|8@1+ (1,0) [0|250] "" Vector__XXX

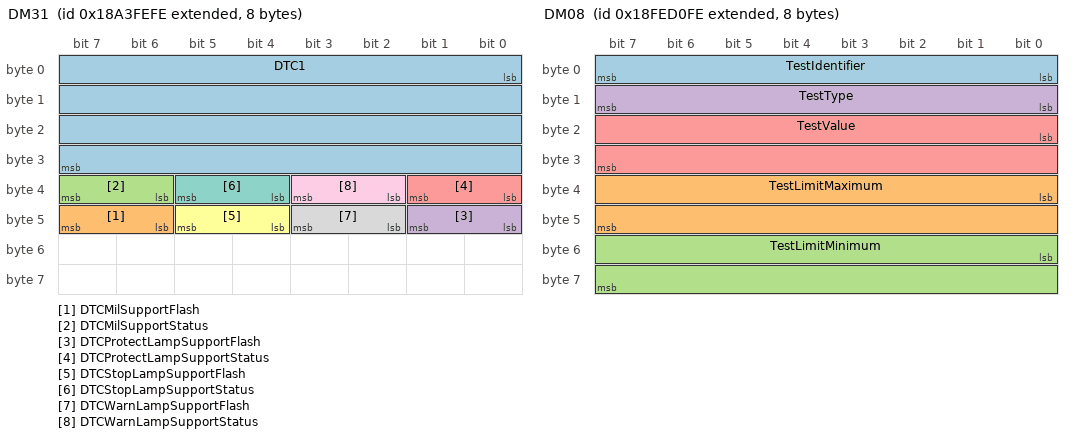
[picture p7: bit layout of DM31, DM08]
BO_ 2560884478 DM31: 8 TirePressureController
 SG_ DTC1 : 0|32@1+ (1,0) [0|4294967295] "" Vector__XXX
 SG_ DTCMilSupportFlash : 46|2@1+ (1,0) [0|3] "" Vector__XXX
 SG_ DTCMilSupportStatus : 38|2@1+ (1,0) [0|3] "" Vector__XXX
 SG_ DTCProtectLampSupportFlash : 40|2@1+ (1,0) [0|3] "" Vector__XXX
 SG_ DTCProtectLampSupportStatus : 32|2@1+ (1,0) [0|3] "" Vector__XXX
 SG_ DTCStopLampSupportFlash : 44|2@1+ (1,0) [0|3] "" Vector__XXX
 SG_ DTCStopLampSupportStatus : 36|2@1+ (1,0) [0|3] "" Vector__XXX
 SG_ DTCWarnLampSupportFlash : 42|2@1+ (1,0) [0|3] "" Vector__XXX
 SG_ DTCWarnLampSupportStatus : 34|2@1+ (1,0) [0|3] "" Vector__XXX

BO_ 2560950014 DM30: 12 TirePressureController
 SG_ FailureModeIdentifier1 : 24|5@1+ (1,0) [0|0] "" Vector__XXX
 SG_ SlotId : 32|16@1+ (1,0) [0|64255] "" Vector__XXX
 SG_ SPN1 : 8|16@1+ (1,0) [0|65536] "" Vector__XXX
 SG_ SPN1High : 29|3@1+ (1,0) [0|7] "" Vector__XXX
 SG_ TestIdentifier : 0|8@1+ (1,0) [0|255] "" Vector__XXX
 SG_ TestLimitMaximum : 64|16@1+ (1,0) [0|64255] "" Vector__XXX
 SG_ TestLimitMinimum : 80|16@1+ (1,0) [0|64255] "" Vector__XXX
 SG_ TestValue : 48|16@1+ (1,0) [0|64255] "" Vector__XXX

BO_ 2566836478 DM08: 8 TirePressureController
 SG_ TestIdentifier : 0|8@1+ (1,0) [0|255] "" Vector__XXX
 SG_ TestLimitMaximum : 32|16@1+ (1,0) [0|0] "" Vector__XXX
 SG_ TestLimitMinimum : 48|16@1+ (1,0) [0|0] "" Vector__XXX
 SG_ TestType : 8|8@1+ (1,0) [0|250] "" Vector__XXX
 SG_ TestValue : 16|16@1+ (1,0) [0|0] "" Vector__XXX

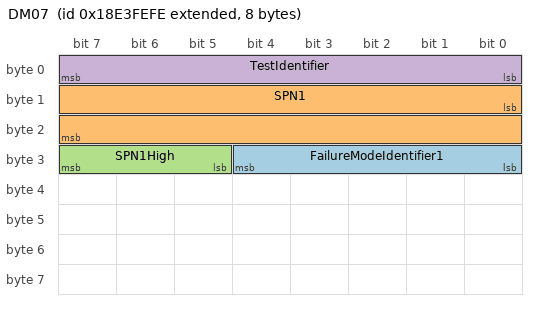
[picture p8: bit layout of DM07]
BO_ 2565078782 DM07: 8 TirePressureController
 SG_ FailureModeIdentifier1 : 24|5@1+ (1,0) [0|31] "" Vector__XXX
 SG_ SPN1 : 8|16@1+ (1,0) [0|524287] "" Vector__XXX
 SG_ SPN1High : 29|3@1+ (1,0) [0|7] "" Vector__XXX
 SG_ TestIdentifier : 0|8@1+ (1,0) [0|255] "" Vector__XXX

BO_ 2566836222 DM06: 22 TirePressureController
 SG_ AmberWarningLampStatus : 2|2@1+ (1,0) [0|3] "" Vector__XXX
 SG_ DTC1 : 16|32@1+ (1,0) [0|4294967295] "" Vector__XXX
 SG_ DTC2 : 48|32@1+ (1,0) [0|4294967295] "" Vector__XXX
 SG_ DTC3 : 80|32@1+ (1,0) [0|4294967295] "" Vector__XXX
 SG_ DTC4 : 112|32@1+ (1,0) [0|4294967295] "" Vector__XXX
 SG_ DTC5 : 144|32@1+ (1,0) [0|4294967295] "" Vector__XXX
 SG_ FlashAmberWarningLamp : 10|2@1+ (1,0) [0|3] "" Vector__XXX
 SG_ FlashMalfuncIndicatorLamp : 14|2@1+ (1,0) [0|3] "" Vector__XXX
 SG_ FlashProtectLamp : 8|2@1+ (1,0) [0|3] "" Vector__XXX
 SG_ FlashRedStopLamp : 12|2@1+ (1,0) [0|3] "" Vector__XXX
 SG_ MalfunctionIndicatorLampStatus : 6|2@1+ (1,0) [0|3] "" Vector__XXX
 SG_ ProtectLampStatus : 0|2@1+ (1,0) [0|3] "" Vector__XXX
 SG_ RedStopLampState : 4|2@1+ (1,0) [0|3] "" Vector__XXX

BO_ 2566835966 DM05: 8 TirePressureController
 SG_ ACSystemRefrigerantMonStatus : 52|1@1+ (1,0) [0|1] "" Vector__XXX
 SG_ ACSystemRefrigerantMonSupp : 36|1@1+ (1,0) [0|1] "" Vector__XXX
 SG_ ActiveTroubleCodes : 0|8@1+ (1,0) [0|250] "" Vector__XXX
 SG_ BoostPressureControlSystemStatus : 57|1@1- (1,0) [0|0] "" Vector__XXX
 SG_ CatalystMonStatus : 48|1@1+ (1,0) [0|1] "" Vector__XXX
 SG_ CatalystMonSupp : 32|1@1+ (1,0) [0|1] "" Vector__XXX
 SG_ ColdStartAidSystemMonStatus : 56|1@1+ (1,0) [0|1] "" Vector__XXX
 SG_ ColdStartAidSystemMonSupp : 40|1@1+ (1,0) [0|1] "" Vector__XXX
 SG_ ComprehensiveCompMonStatus : 30|1@1+ (1,0) [0|1] "" Vector__XXX
 SG_ ComprehensiveComponentMonSupp : 26|1@1+ (1,0) [0|0] "" Vector__XXX
 SG_ DieselParticulateFilterStatus : 58|1@1- (1,0) [0|0] "" Vector__XXX
 SG_ DieselParticulateFilterSupport : 42|1@1- (1,0) [0|0] "" Vector__XXX
 SG_ EGRSystemMonitoringStatus : 55|1@1+ (1,0) [0|1] "" Vector__XXX
 SG_ EGRSystemMonitoringSupp : 39|1@1+ (1,0) [0|1] "" Vector__XXX
 SG_ EvaporativeSystemMonStatus : 50|1@1+ (1,0) [0|1] "" Vector__XXX
 SG_ EvaporativeSystemMonSupp : 34|1@1+ (1,0) [0|1] "" Vector__XXX
 SG_ FuelSystemMonitoringStatus : 29|1@1+ (1,0) [0|1] "" Vector__XXX
 SG_ FuelSystemMonitoringSupport : 25|1@1+ (1,0) [0|1] "" Vector__XXX
 SG_ HeatedCatalystMonStatus : 49|1@1+ (1,0) [0|0] "" Vector__XXX
 SG_ HeatedCatalystMonSupp : 33|1@1+ (1,0) [0|0] "" Vector__XXX
 SG_ MisfireMonitoringStatus : 28|1@1+ (1,0) [0|0] "" Vector__XXX
 SG_ MisfireMonitoringSupport : 24|1@1+ (1,0) [0|0] "" Vector__XXX
 SG_ NMHCConvertingCatalystStatus : 60|1@1- (1,0) [0|0] "" Vector__XXX
 SG_ NMHCConvertingCatalystSupport : 44|1@1- (1,0) [0|0] "" Vector__XXX
 SG_ OBDCompliance : 16|8@1+ (1,0) [0|250] "" Vector__XXX
 SG_ OxygenSensorHeaterMonStatus : 54|1@1+ (1,0) [0|1] "" Vector__XXX
 SG_ OxygenSensorHeaterMonSupp : 38|1@1+ (1,0) [0|1] "" Vector__XXX
 SG_ OxygenSensorMonStatus : 53|1@1+ (1,0) [0|1] "" Vector__XXX
 SG_ OxygenSensorMonSupp : 37|1@1+ (1,0) [0|1] "" Vector__XXX
 SG_ PreviouslyActiveTroubleCodes : 8|8@1+ (1,0) [0|250] "" Vector__XXX
 SG_ SecondAirSystemMonStatus : 51|1@1+ (1,0) [0|1] "" Vector__XXX
 SG_ SecondAirSystemMonSupp : 35|1@1+ (1,0) [0|1] "" Vector__XXX

BO_ 2566835710 DM04: 13 TirePressureController
 SG_ DTC1 : 8|32@1+ (1,0) [0|4294967295] "" Vector__XXX
 SG_ EngCoolantTemp : 80|8@1+ (1,-40) [-40|210] "°C" Vector__XXX
 SG_ EngIntakeManifold1Press : 48|8@1+ (2,0) [0|500] "kPa" Vector__XXX
 SG_ EngPercentLoadAtCurrentSpeed : 72|8@1+ (1,0) [0|125] "%" Vector__XXX
 SG_ EngSpeed : 56|16@1+ (0.125,0) [0|8031.875] "rpm" Vector__XXX
 SG_ EngTorqueMode : 40|4@1+ (1,0) [0|15] "" Vector__XXX
 SG_ FreezeFrameLength : 0|8@1+ (1,0) [0|255] "" Vector__XXX
 SG_ WheelBasedVehicleSpeed : 88|16@1+ (0.00390625,0) [0|250.99609375] "km/h" Vector__XXX

BO_ 2566835454 DM03: 0 TirePressureController

BO_ 2566764542 DM25: 13 TirePressureController
 SG_ DTC1 : 8|32@1+ (1,0) [0|4294967295] "" Vector__XXX
 SG_ ExpandedFreezeFrameLength : 0|8@1+ (1,0) [0|250] "bytes" Vector__XXX

BO_ 2566764286 DM24: 12 TirePressureController
 SG_ SPNDataLength1 : 24|8@1+ (1,0) [0|250] "" Vector__XXX
 SG_ SPNDataLength2 : 56|8@1+ (1,0) [0|240] "" Vector__XXX
 SG_ SPNDataLength3 : 88|8@1+ (1,0) [0|240] "" Vector__XXX
 SG_ SPNSupported1 : 0|16@1+ (1,0) [0|524287] "" Vector__XXX
 SG_ SPNSupported1High : 21|3@1+ (1,0) [0|7] "" Vector__XXX
 SG_ SPNSupported2 : 32|16@1+ (1,0) [0|65535] "" Vector__XXX
 SG_ SPNSupported2High : 53|3@1+ (1,0) [0|7] "" Vector__XXX
 SG_ SPNSupported3 : 64|16@1+ (1,0) [0|65535] "" Vector__XXX
 SG_ SPNSupported3High : 85|3@1+ (1,0) [0|7] "" Vector__XXX
 SG_ SPNSupportTypeDS1 : 17|1@1+ (1,0) [0|1] "" Vector__XXX
 SG_ SPNSupportTypeDS2 : 49|1@1+ (1,0) [0|1] "" Vector__XXX
 SG_ SPNSupportTypeDS3 : 81|1@1+ (1,0) [0|1] "" Vector__XXX
 SG_ SPNSupportTypeEFF1 : 16|1@1+ (1,0) [0|1] "" Vector__XXX
 SG_ SPNSupportTypeEFF2 : 48|1@1+ (1,0) [0|1] "" Vector__XXX
 SG_ SPNSupportTypeEFF3 : 80|1@1+ (1,0) [0|1] "" Vector__XXX
 SG_ SPNSupportTypeSTR1 : 18|1@1+ (1,0) [0|1] "" Vector__XXX
 SG_ SPNSupportTypeSTR2 : 50|1@1+ (1,0) [0|1] "" Vector__XXX
 SG_ SPNSupportTypeSTR3 : 82|1@1+ (1,0) [0|1] "" Vector__XXX

BO_ 2566764030 DM23: 22 TirePressureController
 SG_ AmberWarningLampStatus : 2|2@1+ (1,0) [0|3] "" Vector__XXX
 SG_ DTC1 : 16|32@1+ (1,0) [0|4294967295] "" Vector__XXX
 SG_ DTC2 : 48|32@1+ (1,0) [0|4294967295] "" Vector__XXX
 SG_ DTC3 : 80|32@1+ (1,0) [0|4294967295] "" Vector__XXX
 SG_ DTC4 : 112|32@1+ (1,0) [0|4294967295] "" Vector__XXX
 SG_ DTC5 : 144|32@1+ (1,0) [0|4294967295] "" Vector__XXX
 SG_ FlashAmberWarningLamp : 10|2@1+ (1,0) [0|3] "" Vector__XXX
 SG_ FlashMalfuncIndicatorLamp : 14|2@1+ (1,0) [0|3] "" Vector__XXX
 SG_ FlashProtectLamp : 8|2@1+ (1,0) [0|3] "" Vector__XXX
 SG_ FlashRedStopLamp : 12|2@1+ (1,0) [0|3] "" Vector__XXX
 SG_ MalfunctionIndicatorLampStatus : 6|2@1+ (1,0) [0|3] "" Vector__XXX
 SG_ ProtectLampStatus : 0|2@1+ (1,0) [0|3] "" Vector__XXX
 SG_ RedStopLampState : 4|2@1+ (1,0) [0|3] "" Vector__XXX

CM_ BO_ 2565799678 "Address Claimed - See also J1939-81";
CM_ SG_ 2565799678 IndustryGroup "0 = Global; 
   1  = On-Highway; 
   2  = Agricultural and Forestry; 
   3  = Construction; 
   4  = Marine;
   5  = Industrial - Process
          Control - Stationary (Gen-Sets)
   6  = Reserve for SAE
   7  = Reserve for SAE";
CM_ SG_ 2565799678 ManufacturerCode "Assigned by NMEA 2000 Committee";
CM_ BO_ 2558721790 "Tire Configuration Command Information
Details the attributes for the tire monitoring settings for the tires.";
CM_ SG_ 2558721790 ExtrmUndrPrssPrcntgThrshldStting "Configurable percent deviation from the set cold inflation pressure, for the extreme under tire pressure alert.";
CM_ SG_ 2558721790 OverTempSetting "Configurable constant temperature above which an over temperature alert will trigger.";
CM_ SG_ 2558721790 OvrPrssPrcentageThresholdSetting "Configurable percentage deviation from the set cold inflation pressure, for the over tire pressure alert.";
CM_ SG_ 2558721790 SnsrEnableSetting "Command signal used to enable/disable the tire sensor. On receipt of this command, the tire sensor may either be enabled or disabled.
00b = Off / Isolate / Disable
01b = On / Enable
10b = Reserved / Not Defined
11b = Don't Care / Take No Action
 ...";
CM_ SG_ 2558721790 TireLocation "The location of monitored tire on the vehicle.
The high order 4 bits indicate the vehicle axle position of the tire, counting front to back on the vehicle, with the value 0 representing the front axle on the vehicle. If the upper 4 bits have a ...";
CM_ SG_ 2558721790 UndrPrssPrcntageThresholdSetting "Configurable percent deviation from the set cold inflation pressure, for the under tire pressure alert.";
CM_ BO_ 2558525182 "Tire Sensor Identification Command
The tire sensor identification number command for each monitored tire.
The command will be used to program sensor identification numbers for individual tire. Since there are multiple tire sensors to report, the ...";
CM_ SG_ 2558525182 Location "The location of monitored tire that corresponds with the tire sensor identification number SPN 7586. In order to specify the monitored tire by tire number, use the tire number SPN 7584.
The high order 4 bits indicate the vehicle axle position of ...";
CM_ SG_ 2558525182 Num "The number of the monitored tire that corresponds with the tire sensor identification number SPN 7586. In order to specify the monitored tire by location, use the tire location SPN 7585.

The value FFh indicates this SP is not used.";
CM_ SG_ 2558525182 Num7586 "The identification number of tire sensor for the tire specified in the tire sensor tire number (SPN 7584) or tire sensor location (SPN 7585).";
CM_ SG_ 2558525182 NumOfTireSensors "Total count of monitored tire sensor identification numbers represented in this instance of the parameter group.";
CM_ BO_ 2566670078 "Tire Sensor Identification Status
The tire sensor identification number for each monitored tire.
Since there are multiple tire sensors to report, the message format will be a,b,c,d,b,c,d,b,c,d,b,c,d,...etc. where
a = Number of Tire Sensors
b = ...";
CM_ SG_ 2566670078 NumberOfTireSensors "Total count of monitored tire sensor identification numbers represented in this instance of the parameter group.";
CM_ SG_ 2566670078 TireSensorIdentificationNumber "The identification number of the tire specified in the tire number (SPN 6964) or tire location (SPN 6965).";
CM_ SG_ 2566670078 TireSensorLocation "The location of monitored tire that corresponds with the Tire Sensor Identification Number (SPN 6966). In order to specify the monitored tire by tire number, use the Tire Number SPN 6964.
The high order 4 bits indicate the vehicle axle position of ...";
CM_ SG_ 2566670078 TireSensorTireNumber "The number of the monitored tire that corresponds with the Tire Sensor Identification Number (SPN 6966).  In order to specify the monitored tire by location, use the Tire Location SPN 6965.

The value FFh indicates this SP is not used.";
CM_ BO_ 2566669054 "Tire Condition Message 2
Tire Condition Message 2
NOTE – Multiple instances of this message will be required to transmit data for all tire locations.  When reporting data for multiple tire locations, each successive message, which provides data ...";
CM_ SG_ 2566669054 RequiredTirePress "The required tire pressure at which air is contained in cavity formed by tire and rim.

This pressure of the tire is compensated to meet the specific physical environmental conditions (temperature) of the vehicle.";
CM_ SG_ 2566669054 TireLocation "Identifies which tire is associated with the parametric data in PGN 64578. Refer to SPN 929 for further details and examples. The low order 4 bits represent a position number, counting left to right when facing in the direction of normal vehicle ...";
CM_ SG_ 2566669054 TirePress "Pressure at which air is contained in cavity formed by tire and rim. See SPN 241 for alternate tire pressure with a lower range and coarser resolution.";
CM_ BO_ 2566836734 "Oxygen Sensor Test Results
SAE J1939 will not specify an implementation for this DM.  Oxygen sensor test and results should be communicated using DM7 and DM8";
CM_ BO_ 2566702846 "OBD Information";
CM_ SG_ 2566702846 EngOBDWarmUpSequence "Engine warm-up as defined by the applicable region's regulatory agency.  In the US, \"Engine OBD Warm-up\" or “Warm-up cycle” means sufficient vehicle operation such that coolant temperature rises by at least 22.2 °C (40 °F) from engine starting and ...";
CM_ BO_ 2566703102 "Engine Emissions Certification Information";
CM_ SG_ 2566703102 CertificationEngineFamilyName "The regulated family name per the applicable region's certification agency.  For engines certified in the US, this shall be the 12-character engine family name or test group as defined by EPA.  Up to 200 characters may be used.  The characters are ...";
CM_ SG_ 2566703102 ModelYear "The compliance model year of the OBD system of the engine and or vehicle.  For example in the US, this is associated with either a vehicle model year or an engine model year, depending on how the emissions and OBD are certified.  This message shall ...";
CM_ BO_ 2566705918 "Previously Active Service Only DTCs";
CM_ SG_ 2566705918 AmberWarningLampStatus "This lamp is used to relay trouble code information that is reporting a problem with the vehicle system but the vehicle need not be immediately stopped. 

00     Lamp Off
01     Lamp On
10     Reserved
11     Not available";
CM_ SG_ 2566705918 DTC1 "Diagnostic Trouble Code";
CM_ SG_ 2566705918 DTC2 "Diagnostic Trouble Code";
CM_ SG_ 2566705918 DTC3 "Diagnostic Trouble Code";
CM_ SG_ 2566705918 DTC4 "Diagnostic Trouble Code";
CM_ SG_ 2566705918 DTC5 "Diagnostic Trouble Code";
CM_ SG_ 2566705918 FlashAmberWarningLamp "This parameter provides the capability to flash the AWL

00 - Slow Flash (1 Hz, 50 % duty cycle)
01 - Fast Flash (2 Hz or faster, 50% duty cycle)
10 - Reserved
11 - Unavailable / Do Not Flash";
CM_ SG_ 2566705918 FlashMalfuncIndicatorLamp "This parameter provides the capability to flash the MIL
00 - Slow Flash (1 Hz, 50 % duty cycle)
01 - Fast Flash (2 Hz or faster, 50% duty cycle)
10 - Class C DTC
11 - Unavailable / Do Not Flash
Note:  State 10 is for WWH OBD discriminatory ...";
CM_ SG_ 2566705918 FlashProtectLamp "This parameter provides the capability to flash the engine protect lamp


00 - Slow Flash (1 Hz, 50 % duty cycle)
01 - Fast Flash (2 Hz or faster, 50% duty cycle)
10 - Reserved
11 - Unavailable / Do Not Flash";
CM_ SG_ 2566705918 FlashRedStopLamp "This parameter provides the capability to flash the RSL


00 - Slow Flash (1 Hz, 50 % duty cycle)
01 - Fast Flash (2 Hz or faster, 50% duty cycle)
10 - Reserved
11 - Unavailable / Do Not Flash";
CM_ SG_ 2566705918 MalfunctionIndicatorLampStatus "A lamp used to relay only emissions-related trouble code information. This lamp is only illuminated when there is an emission-related trouble code active.
00     Lamp Off
01     Lamp On
10     Short MIL for WWH OBD
11     Not available
Note ...";
CM_ SG_ 2566705918 ProtectLampStatus "This lamp is used to relay trouble code information that is reporting a problem with a vehicle system that is most probably not electronic subsystem related. For instance, engine coolant temperature is exceeding its prescribed temperature range.
00 ...";
CM_ SG_ 2566705918 RedStopLampState "This lamp is used to relay trouble code information that is of a severe enough condition that it warrants stopping the vehicle.

00     Lamp Off
01     Lamp On
10     Reserved
11     Not available";
CM_ BO_ 2566705662 "Active Service Only DTCs";
CM_ SG_ 2566705662 AmberWarningLampStatus "This lamp is used to relay trouble code information that is reporting a problem with the vehicle system but the vehicle need not be immediately stopped. 

00     Lamp Off
01     Lamp On
10     Reserved
11     Not available";
CM_ SG_ 2566705662 DTC1 "Diagnostic Trouble Code";
CM_ SG_ 2566705662 DTC2 "Diagnostic Trouble Code";
CM_ SG_ 2566705662 DTC3 "Diagnostic Trouble Code";
CM_ SG_ 2566705662 DTC4 "Diagnostic Trouble Code";
CM_ SG_ 2566705662 DTC5 "Diagnostic Trouble Code";
CM_ SG_ 2566705662 FlashAmberWarningLamp "This parameter provides the capability to flash the AWL

00 - Slow Flash (1 Hz, 50 % duty cycle)
01 - Fast Flash (2 Hz or faster, 50% duty cycle)
10 - Reserved
11 - Unavailable / Do Not Flash";
CM_ SG_ 2566705662 FlashMalfuncIndicatorLamp "This parameter provides the capability to flash the MIL
00 - Slow Flash (1 Hz, 50 % duty cycle)
01 - Fast Flash (2 Hz or faster, 50% duty cycle)
10 - Class C DTC
11 - Unavailable / Do Not Flash
Note:  State 10 is for WWH OBD discriminatory ...";
CM_ SG_ 2566705662 FlashProtectLamp "This parameter provides the capability to flash the engine protect lamp


00 - Slow Flash (1 Hz, 50 % duty cycle)
01 - Fast Flash (2 Hz or faster, 50% duty cycle)
10 - Reserved
11 - Unavailable / Do Not Flash";
CM_ SG_ 2566705662 FlashRedStopLamp "This parameter provides the capability to flash the RSL


00 - Slow Flash (1 Hz, 50 % duty cycle)
01 - Fast Flash (2 Hz or faster, 50% duty cycle)
10 - Reserved
11 - Unavailable / Do Not Flash";
CM_ SG_ 2566705662 MalfunctionIndicatorLampStatus "A lamp used to relay only emissions-related trouble code information. This lamp is only illuminated when there is an emission-related trouble code active.
00     Lamp Off
01     Lamp On
10     Short MIL for WWH OBD
11     Not available
Note ...";
CM_ SG_ 2566705662 ProtectLampStatus "This lamp is used to relay trouble code information that is reporting a problem with a vehicle system that is most probably not electronic subsystem related. For instance, engine coolant temperature is exceeding its prescribed temperature range.
00 ...";
CM_ SG_ 2566705662 RedStopLampState "This lamp is used to relay trouble code information that is of a severe enough condition that it warrants stopping the vehicle.

00     Lamp Off
01     Lamp On
10     Reserved
11     Not available";
CM_ BO_ 2566706174 "Diagnostic Data Clear/Reset for All Service Only DTCs
All of the diagnostic information pertaining to the active service only diagnostic trouble codes and previously active diagnostic trouble codes should be erased as well as the DTCs.";
CM_ BO_ 2560818942 "Regulated Exhaust Emission Level Exceedance
Provides the DTCs and associated timers related to a regulated exhaust emission level exceedance due to an emission control system malfunction.";
CM_ SG_ 2560818942 DTCTimeUntilDerate "This timer provides the number of hours the malfunction has until the OBD required derate will occur";
CM_ SG_ 2560818942 DTCTotalActiveTime "This timer provides the total number of hours the DTC has been confirmed and active";
CM_ SG_ 2560818942 DTCTotalPreviouslyActiveTime "This timer provides the number of hours the NOx malfunction has been confirmed and previously active";
CM_ SG_ 2560818942 FailureModeIdentifier1 "The FMI defines the type of failure detected in the subsystem identified by an SPN.";
CM_ SG_ 2560818942 SPN1 "This 19-bit number is used to identify the item for which diagnostics are being reported.";
CM_ SG_ 2560818942 SPN1High "SPN #1 (Conversion Version 4)";
CM_ BO_ 2566764798 "Diagnostic Readiness 3
This message conveys information useful in determining whether the OBD System has a defect or not.";
CM_ SG_ 2566764798 NumOfWarmUpsSinceDTCsCleared "Number of warm-up cycles since all DTCs were cleared (via an external test equipment or possibly, a battery disconnect).  A warm-up is defined in the OBD regulations to be sufficient vehicle operation such that coolant temperature rises by at least ...";
CM_ SG_ 2566764798 TimeSinceEngineStart "RUNTM shall increment while the engine is running.  It shall freeze if the engine stalls.  RUNTM shall be reset to zero during every control module power-up and when entering the key-on, engine off position.  RUNTM is limited to 65,535 seconds and ...";
CM_ BO_ 2564095742 "Data Security
The data security parameter group is used to send security entities of a given type and length. These entities are data produced by or used for applications of cryptography and supporting procedures to ensure data security.";
CM_ SG_ 2564095742 DataSecurityParameter "This Parameter is used to send the data for the Data Security message. There are presently four different items defined. The Data Security Parameter shall be sent least significant byte first.";
CM_ SG_ 2564095742 SecurityEntityLength "This 12-bit parameter contains the length, in bytes, of the Data Security Parameter.";
CM_ SG_ 2564095742 SecurityEntityType "This 4-bit parameter that indicates whether the data in the following Security Entity parameter is to be used as a Long Seed, Long Key, Session Key, or Certificate.";
CM_ BO_ 2561605374 "Tire Pressure Reference Setting
For setting the tire pressure reference values.

This message is the setpoint for the PGN 64953 Tire Pressure reference information message.";
CM_ SG_ 2561605374 TireLocation "Identifies which tire is associated with the parametric data in this PGN.
The low order 4 bits represent a position number, counting left to right when facing in the direction of normal vehicle travel (forward).
The high order 4 bits represent a ...";
CM_ BO_ 2566765054 "Tire Pressure Reference Information
Information on actual tire pressure reference value for monitoring.
NOTE–Message has to repeated as necessary to transmit all available information.  This method of location identification requires individual ...";
CM_ SG_ 2566765054 TireLocation "Identifies which tire is associated with the parametric data in this PGN.
The low order 4 bits represent a position number, counting left to right when facing in the direction of normal vehicle travel (forward).
The high order 4 bits represent a ...";
CM_ BO_ 2633923326 "Tire Pressure Control Unit Current Pressures";
CM_ SG_ 2633923326 DriveChannelTirePress "The latest gage pressure reading of the drive group of tires, as opposed to the pressure in each tire.";
CM_ SG_ 2633923326 SteerChannelTirePress "The latest gage pressure reading of the steer group of tires, as opposed to the pressure in each tire.";
CM_ SG_ 2633923326 TrailerTagOrPushChannelTirePress "The latest gage pressure reading of the trailer, tag, or push group of tires, as opposed to the pressure in each tire.";
CM_ BO_ 2633923070 "Tire Pressure Control Unit Target Pressures";
CM_ SG_ 2633923070 DriveChannelTirePressTarget "The tire pressure control system’s target gage pressure for the drive group of tires.";
CM_ SG_ 2633923070 SteerChannelTirePressTarget "The tire pressure control system’s target gage pressure for the steer group of tires.";
CM_ SG_ 2633923070 TrlrTgOrPshChnnelTirePressTarget "The tire pressure control system’s target gage pressure for the trailer, tag, or push group of tires.";
CM_ BO_ 2633922814 "Tire Pressure Control Unit Mode and Status";
CM_ SG_ 2633922814 DriveChannelMode "Indicates the functional mode of trailer/tag channel of the tire pressure control system.
0000b = Maintain
0001b = Inflate
0010b = Deflate
0011b = Confirm
0100b = Inflate Wait - System will inflate when conditions allow
0101b = Deflate Wait - ...";
CM_ SG_ 2633922814 PCUCtrlSolenoidStatus "Current state of the control solenoid used to implement a tire pressure control system in its pneumatic control unit (PCU).

00b = Off
01b = On
10b = Error
11b = Not available";
CM_ SG_ 2633922814 PCUDeflateSolenoidStatus "Current state of the deflate solenoid used to implement a tire pressure control system in its pneumatic control unit (PCU).

00b = Off
01b = On
10b = Error
11b = Not available";
CM_ SG_ 2633922814 PCUDriveSolenoidStatus "Current state of the drive solenoid used to implement a tire pressure control system in its pneumatic control unit (PCU).

00b = Off
01b = On
10b = Error
11b = Not available";
CM_ SG_ 2633922814 PCUSteerSolenoidStatus "Current state of the steer solenoid used to implement a tire pressure control system in its pneumatic control unit (PCU).

00b = Off
01b = On
10b = Error
11b = Not available";
CM_ SG_ 2633922814 PCUSupplySolenoidStatus "Current state of the supply solenoid used to implement a tire pressure control system in its pneumatic control unit (PCU).

00b = Off
01b = On
10b = Error
11b = Not available";
CM_ SG_ 2633922814 PCUTrilerTagOrPushSolenoidStatus "Current state of the trailer, tag, or push solenoid used to implement a tire pressure control system in its pneumatic control unit (PCU).

00b = Off
01b = On
10b = Error
11b = Not available";
CM_ SG_ 2633922814 SteerChannelMode "Indicates the functional mode of steer channel of the tire pressure control system.
0000b = Maintain
0001b = Inflate
0010b = Deflate
0011b = Confirm
0100b = Inflate Wait - System will inflate when conditions allow
0101b = Deflate Wait - System ...";
CM_ SG_ 2633922814 TirePressCheckInterval "The interval at which the system will check the tire pressures (e.g., 5, 10, 15 min.).

NOTE - A value of 0 indicates continuous (real time) pressure readings.";
CM_ SG_ 2633922814 TirePressSupplySwitchStatus "Current state of an open/closed type switch used to determine if adequate pressure exists for system implementation.

00b = Off
01b = On
10b = Error
11b = Not available";
CM_ SG_ 2633922814 Trailer_tagChannelMode "Indicates the functional mode of trailer/tag channel of the tire pressure control system.
0000b = Maintain
0001b = Inflate
0010b = Deflate
0011b = Confirm
0100b = Inflate Wait - System will inflate when conditions allow
0101b = Deflate Wait - ...";
CM_ BO_ 2566845694 "Tire Condition Message 1
Tire Condition Message
NOTE – Multiple instances of this message will be required to transmit data for all tire locations.  When reporting data for multiple tire locations, each successive message, which provides data for ...";
CM_ SG_ 2566845694 CTITireStatus_00 "Indicates the status of the tire.";
CM_ SG_ 2566845694 CTITireStatus_01 "Indicates the status of the tire.";
CM_ SG_ 2566845694 CTITireStatus_10 "Indicates the status of the tire.";
CM_ SG_ 2566845694 CTITireStatus_11 "Indicates the status of the tire.";
CM_ SG_ 2566845694 CTITireStatus_12 "Indicates the status of the tire.";
CM_ SG_ 2566845694 CTITireStatus_13 "Indicates the status of the tire.";
CM_ SG_ 2566845694 CTITireStatus_20 "Indicates the status of the tire.";
CM_ SG_ 2566845694 CTITireStatus_21 "Indicates the status of the tire.";
CM_ SG_ 2566845694 CTITireStatus_22 "Indicates the status of the tire.";
CM_ SG_ 2566845694 CTITireStatus_23 "Indicates the status of the tire.";
CM_ SG_ 2566845694 CTITireStatus_30 "Indicates the status of the tire.";
CM_ SG_ 2566845694 CTITireStatus_31 "Indicates the status of the tire.";
CM_ SG_ 2566845694 CTITireStatus_32 "Indicates the status of the tire.";
CM_ SG_ 2566845694 CTITireStatus_33 "Indicates the status of the tire.";
CM_ SG_ 2566845694 CTIWheelEndElectricalFault_00 "Indicates the status of electrical fault on CTI wheel interface.";
CM_ SG_ 2566845694 CTIWheelEndElectricalFault_01 "Indicates the status of electrical fault on CTI wheel interface.";
CM_ SG_ 2566845694 CTIWheelEndElectricalFault_10 "Indicates the status of electrical fault on CTI wheel interface.";
CM_ SG_ 2566845694 CTIWheelEndElectricalFault_11 "Indicates the status of electrical fault on CTI wheel interface.";
CM_ SG_ 2566845694 CTIWheelEndElectricalFault_12 "Indicates the status of electrical fault on CTI wheel interface.";
CM_ SG_ 2566845694 CTIWheelEndElectricalFault_13 "Indicates the status of electrical fault on CTI wheel interface.";
CM_ SG_ 2566845694 CTIWheelEndElectricalFault_20 "Indicates the status of electrical fault on CTI wheel interface.";
CM_ SG_ 2566845694 CTIWheelEndElectricalFault_21 "Indicates the status of electrical fault on CTI wheel interface.";
CM_ SG_ 2566845694 CTIWheelEndElectricalFault_22 "Indicates the status of electrical fault on CTI wheel interface.";
CM_ SG_ 2566845694 CTIWheelEndElectricalFault_23 "Indicates the status of electrical fault on CTI wheel interface.";
CM_ SG_ 2566845694 CTIWheelEndElectricalFault_30 "Indicates the status of electrical fault on CTI wheel interface.";
CM_ SG_ 2566845694 CTIWheelEndElectricalFault_31 "Indicates the status of electrical fault on CTI wheel interface.";
CM_ SG_ 2566845694 CTIWheelEndElectricalFault_32 "Indicates the status of electrical fault on CTI wheel interface.";
CM_ SG_ 2566845694 CTIWheelEndElectricalFault_33 "Indicates the status of electrical fault on CTI wheel interface.";
CM_ SG_ 2566845694 CTIWheelSensorStatus_00 "Indicates whether the wheel is being monitored by the CTI controller.";
CM_ SG_ 2566845694 CTIWheelSensorStatus_01 "Indicates whether the wheel is being monitored by the CTI controller.";
CM_ SG_ 2566845694 CTIWheelSensorStatus_10 "Indicates whether the wheel is being monitored by the CTI controller.";
CM_ SG_ 2566845694 CTIWheelSensorStatus_11 "Indicates whether the wheel is being monitored by the CTI controller.";
CM_ SG_ 2566845694 CTIWheelSensorStatus_12 "Indicates whether the wheel is being monitored by the CTI controller.";
CM_ SG_ 2566845694 CTIWheelSensorStatus_13 "Indicates whether the wheel is being monitored by the CTI controller.";
CM_ SG_ 2566845694 CTIWheelSensorStatus_20 "Indicates whether the wheel is being monitored by the CTI controller.";
CM_ SG_ 2566845694 CTIWheelSensorStatus_21 "Indicates whether the wheel is being monitored by the CTI controller.";
CM_ SG_ 2566845694 CTIWheelSensorStatus_22 "Indicates whether the wheel is being monitored by the CTI controller.";
CM_ SG_ 2566845694 CTIWheelSensorStatus_23 "Indicates whether the wheel is being monitored by the CTI controller.";
CM_ SG_ 2566845694 CTIWheelSensorStatus_30 "Indicates whether the wheel is being monitored by the CTI controller.";
CM_ SG_ 2566845694 CTIWheelSensorStatus_31 "Indicates whether the wheel is being monitored by the CTI controller.";
CM_ SG_ 2566845694 CTIWheelSensorStatus_32 "Indicates whether the wheel is being monitored by the CTI controller.";
CM_ SG_ 2566845694 CTIWheelSensorStatus_33 "Indicates whether the wheel is being monitored by the CTI controller.";
CM_ SG_ 2566845694 ExTirePressSupport "Defines the choice of using the tire pressure (PGN 65268) or Extended Tire Pressure (PGN 64578). The state value '01b' indicates the extended tire pressure SP is used for the pressure data. Any other value indicates the extended tire pressure SP is ...";
CM_ SG_ 2566845694 TireAirLeakageRate_00 "The pressure loss rate of a tire.";
CM_ SG_ 2566845694 TireAirLeakageRate_01 "The pressure loss rate of a tire.";
CM_ SG_ 2566845694 TireAirLeakageRate_10 "The pressure loss rate of a tire.";
CM_ SG_ 2566845694 TireAirLeakageRate_11 "The pressure loss rate of a tire.";
CM_ SG_ 2566845694 TireAirLeakageRate_12 "The pressure loss rate of a tire.";
CM_ SG_ 2566845694 TireAirLeakageRate_13 "The pressure loss rate of a tire.";
CM_ SG_ 2566845694 TireAirLeakageRate_20 "The pressure loss rate of a tire.";
CM_ SG_ 2566845694 TireAirLeakageRate_21 "The pressure loss rate of a tire.";
CM_ SG_ 2566845694 TireAirLeakageRate_22 "The pressure loss rate of a tire.";
CM_ SG_ 2566845694 TireAirLeakageRate_23 "The pressure loss rate of a tire.";
CM_ SG_ 2566845694 TireAirLeakageRate_30 "The pressure loss rate of a tire.";
CM_ SG_ 2566845694 TireAirLeakageRate_31 "The pressure loss rate of a tire.";
CM_ SG_ 2566845694 TireAirLeakageRate_32 "The pressure loss rate of a tire.";
CM_ SG_ 2566845694 TireAirLeakageRate_33 "The pressure loss rate of a tire.";
CM_ SG_ 2566845694 TireLocation "Identifies which tire is associated with the parametric data in this PG.
The low order 4 bits represent a position number, counting left to right when facing in the direction of normal vehicle travel (forward).
The high order 4 bits represent a ...";
CM_ SG_ 2566845694 TirePress_00 "Pressure at which air is contained in cavity formed by tire and rim.";
CM_ SG_ 2566845694 TirePress_01 "Pressure at which air is contained in cavity formed by tire and rim.";
CM_ SG_ 2566845694 TirePress_10 "Pressure at which air is contained in cavity formed by tire and rim.";
CM_ SG_ 2566845694 TirePress_11 "Pressure at which air is contained in cavity formed by tire and rim.";
CM_ SG_ 2566845694 TirePress_12 "Pressure at which air is contained in cavity formed by tire and rim.";
CM_ SG_ 2566845694 TirePress_13 "Pressure at which air is contained in cavity formed by tire and rim.";
CM_ SG_ 2566845694 TirePress_20 "Pressure at which air is contained in cavity formed by tire and rim.";
CM_ SG_ 2566845694 TirePress_21 "Pressure at which air is contained in cavity formed by tire and rim.";
CM_ SG_ 2566845694 TirePress_22 "Pressure at which air is contained in cavity formed by tire and rim.";
CM_ SG_ 2566845694 TirePress_23 "Pressure at which air is contained in cavity formed by tire and rim.";
CM_ SG_ 2566845694 TirePress_30 "Pressure at which air is contained in cavity formed by tire and rim.";
CM_ SG_ 2566845694 TirePress_31 "Pressure at which air is contained in cavity formed by tire and rim.";
CM_ SG_ 2566845694 TirePress_32 "Pressure at which air is contained in cavity formed by tire and rim.";
CM_ SG_ 2566845694 TirePress_33 "Pressure at which air is contained in cavity formed by tire and rim.";
CM_ SG_ 2566845694 TirePressThresholdDetection_00 "Signal indicating the pressure level of the tire.";
CM_ SG_ 2566845694 TirePressThresholdDetection_01 "Signal indicating the pressure level of the tire.";
CM_ SG_ 2566845694 TirePressThresholdDetection_10 "Signal indicating the pressure level of the tire.";
CM_ SG_ 2566845694 TirePressThresholdDetection_11 "Signal indicating the pressure level of the tire.";
CM_ SG_ 2566845694 TirePressThresholdDetection_12 "Signal indicating the pressure level of the tire.";
CM_ SG_ 2566845694 TirePressThresholdDetection_13 "Signal indicating the pressure level of the tire.";
CM_ SG_ 2566845694 TirePressThresholdDetection_20 "Signal indicating the pressure level of the tire.";
CM_ SG_ 2566845694 TirePressThresholdDetection_21 "Signal indicating the pressure level of the tire.";
CM_ SG_ 2566845694 TirePressThresholdDetection_22 "Signal indicating the pressure level of the tire.";
CM_ SG_ 2566845694 TirePressThresholdDetection_23 "Signal indicating the pressure level of the tire.";
CM_ SG_ 2566845694 TirePressThresholdDetection_30 "Signal indicating the pressure level of the tire.";
CM_ SG_ 2566845694 TirePressThresholdDetection_31 "Signal indicating the pressure level of the tire.";
CM_ SG_ 2566845694 TirePressThresholdDetection_32 "Signal indicating the pressure level of the tire.";
CM_ SG_ 2566845694 TirePressThresholdDetection_33 "Signal indicating the pressure level of the tire.";
CM_ SG_ 2566845694 TireTemp_00 "Temperature at the surface of the tire sidewall.";
CM_ SG_ 2566845694 TireTemp_01 "Temperature at the surface of the tire sidewall.";
CM_ SG_ 2566845694 TireTemp_10 "Temperature at the surface of the tire sidewall.";
CM_ SG_ 2566845694 TireTemp_11 "Temperature at the surface of the tire sidewall.";
CM_ SG_ 2566845694 TireTemp_12 "Temperature at the surface of the tire sidewall.";
CM_ SG_ 2566845694 TireTemp_13 "Temperature at the surface of the tire sidewall.";
CM_ SG_ 2566845694 TireTemp_20 "Temperature at the surface of the tire sidewall.";
CM_ SG_ 2566845694 TireTemp_21 "Temperature at the surface of the tire sidewall.";
CM_ SG_ 2566845694 TireTemp_22 "Temperature at the surface of the tire sidewall.";
CM_ SG_ 2566845694 TireTemp_23 "Temperature at the surface of the tire sidewall.";
CM_ SG_ 2566845694 TireTemp_30 "Temperature at the surface of the tire sidewall.";
CM_ SG_ 2566845694 TireTemp_31 "Temperature at the surface of the tire sidewall.";
CM_ SG_ 2566845694 TireTemp_32 "Temperature at the surface of the tire sidewall.";
CM_ SG_ 2566845694 TireTemp_33 "Temperature at the surface of the tire sidewall.";
CM_ BO_ 2566839038 "Software Identification
Byte: 1 Number of software identification fields
2-n Software identification(s)
Delimiter (ASCII “*”)
NOTE- The software identification field is variable in length and may contain up to 125 software identification ...";
CM_ SG_ 2566839038 NmbrOfSftwreIdentificationFields "Number of software identification designators represented in the software identification parameter group.";
CM_ SG_ 2566839038 SoftwareIdentification "Software identification of an electronic module.  As an example, this parameter may be represented with ASCII characters MMDDYYaa where MM is the month, DD is the day, YY is the year, and aa is the revision number.
NOTE The ASCII character “*” is ...";
CM_ BO_ 2566768126 "ECU Identification Information
Message for reporting identification and information about the physical ECU and its hardware, such as the ECU's part number, serial number, build date, etc.  Information about the software within the ECU should be ...";
CM_ SG_ 2566768126 DateOfManufacture "The date of manufacture for the physical ECU. Devices supporting this field are recommended to observe the date formats as described in ISO 8601.";
CM_ SG_ 2566768126 ECUHardwareID "The ECU Hardware ID provides information to identify a specific ECU hardware version.
As an example, on a CAN network, this parameter can be used to uniquely identify the hardware version that is relevant for the interface of the ECU to the CAN ...";
CM_ SG_ 2566768126 ECULocation "The location of the ECU within a network.";
CM_ SG_ 2566768126 ECUManufacturerName "The name of the manufacturer of the physical ECU.

This name may be different than the manufacturer identified by the Manufacturer Code (SPN 2838) and listed in table B10 of J1939.";
CM_ SG_ 2566768126 ECUPartNumber "The part number of the physical ECU.";
CM_ SG_ 2566768126 ECUSerialNumber "The serial number of the physical ECU.";
CM_ SG_ 2566768126 ECUType "The type of ECU.  One example of a use of the ECU type could be for classifying ECU capabilities, such as I/O.";
CM_ BO_ 2566742270 "Harmonized B1 Failure Counts (HB1C)
HB1C provides the system specific individual B1 failure counters, when supported by the system.";
CM_ SG_ 2566742270 FailureModeIdentifier1 "The FMI defines the type of failure detected in the subsystem identified by an SPN.";
CM_ SG_ 2566742270 FailureSpecificB1Counter "The Failure Specific B1 Counter provides an individual B1 counter";
CM_ SG_ 2566742270 SPN1 "This 19-bit number is used to identify the item for which diagnostics are being reported.";
CM_ SG_ 2566742270 SPN1High "SPN #1 (Conversion Version 4)";
CM_ BO_ 2566742526 "Cumulative Continuous MI – System (HCMI) 
HCMI provides the system specific cumulative.";
CM_ SG_ 2566742526 SysCumulativeContinuousMITime "System Cumulative Continuous MI Time";
CM_ SG_ 2566742526 SysGreatestB1Counter "System Greatest B1 Counter";
CM_ BO_ 2566742782 "Harmonized Global Regulation Description (HGRD)
HGRD provides a description of the UN/ECE WWH OBD Global Technical Regulation (GTR) to which the sub-system or
component complies.";
CM_ SG_ 2566742782 RegulationDescription "Global Technical Regulation Description";
CM_ BO_ 2566743038 "Harmonized Roadworthiness – System (HRWS)
HRWS reports subsystem (or component) roadworthiness to the VOBD function to aggregate in the HRWV message.";
CM_ SG_ 2566743038 SysContinuousMalfunctionInd "System Continuous Malfunction Indicator";
CM_ SG_ 2566743038 SysIncompleteMonitorCount "System Incomplete Monitor Count";
CM_ SG_ 2566743038 SysMalIndActivationMode "System Malfunction Indicator Status";
CM_ SG_ 2566743038 SysMalIndDisplayStrategy "System Malfunction Indicator Display";
CM_ SG_ 2566743038 SysNonRoadworthyCompCount "System Non-Roadworthy Component Count";
CM_ BO_ 2566743294 "Harmonized Roadworthiness - Vehicle (HRWV)
HRWV provides the aggregated roadworthiness from the VOBD (Vehicle On-Board Diagnostics) to a scan tool or similar inquiry device.";
CM_ SG_ 2566743294 VehicleContinuousMalfunctionInd "Vehicle Continuous Malfunction Indicator";
CM_ SG_ 2566743294 VehicleCurrentMIAccumTime "Vehicle current malfunction indicator accumulated time reports the accumulated count (in minutes) that the malfunction indicator lamp (MIL) is activated (on) for the current malfunction indicator (MI) activation (or the last MI activation).
For US, ...";
CM_ SG_ 2566743294 VehicleIncompleteMonitorCount "Vehicle Incomplete Monitor Count";
CM_ SG_ 2566743294 VehicleMalfunctionIndActMode "Vehicle Malfunction Indicator Status ";
CM_ SG_ 2566743294 VehicleMalfunctionIndStrategy "Vehicle Malfunction Indicator Display Strategy ";
CM_ SG_ 2566743294 VehicleNonRoadworthyCompCount "Vehicle Non-Roadworthy Component Count";
CM_ BO_ 2560687870 "NTE Status
The status of engine operating in the NTE control areas for given pollutants, such as NOx and PM.";
CM_ SG_ 2560687870 MnfcNOxNTECarveOutAreaStatus "Status of engine operation within the manufacturer specific NOx NTE limited testing region.  The manufacturer specific NOx NTE limited testing region is defined as bounded regions within the NTE control area for NOx where the manufacturer has ...";
CM_ SG_ 2560687870 MnfcPMNTECarveOutAreaStatus "Status of engine operation within the manufacturer specific PM NTE limited testing region.  The manufacturer specific PM NTE  limited testing region is defined as bounded regions within the NTE control area for PM where the manufacturer has limited ...";
CM_ SG_ 2560687870 NOxNTEControlAreaStatus "Status of engine operation within the bounded region of the engine’s torque and speed map where emissions must not exceed a specific emission cap for NOx under the NTE requirement.";
CM_ SG_ 2560687870 NOxNTEDeficiencyAreaStatus "Status of engine operation within the NOx NTE Deficiency Area.  The NOx NTE Deficiency Area is defined as bounded regions or conditions within the NTE control area for NOx where the manufacturer has received a deficiency.  If the application does ...";
CM_ SG_ 2560687870 PMNTEControlAreaStatus "Status of engine operation within the bounded region of the engine’s torque and speed map where emissions must not exceed a specific emission cap for PM under the NTE requirement.";
CM_ SG_ 2560687870 PMNTEDeficiencyAreaStatus "Status of engine operation within the PM NTE Deficiency Area.  The PM NTE Deficiency Area is defined as bounded regions or conditions within the NTE control area for PM where the manufacturer has received a deficiency.  If the application does not ...";
CM_ BO_ 2292317950 "Emission Increasing Auxiliary Emission Control Device Active Time
The total engine run time while each of the Emission Increasing Auxiliary Emission Control Devices (EI-AECDs) is active.";
CM_ SG_ 2292317950 AECDEngineHours1Timer1 "The total engine running hours recorded in the first timer for the EI-AECD";
CM_ SG_ 2292317950 AECDEngineHours1Timer2 "The total engine running hours recorded in the second timer for the EI-AECD";
CM_ SG_ 2292317950 AECDNumber1 "The manufacturer assigned number for the specific EI-AECD";
CM_ BO_ 2560884478 "DTC To Lamp Association
This message shall provide the applicable lamp(s) for each individual DTC";
CM_ SG_ 2560884478 DTC1 "Diagnostic Trouble Code";
CM_ SG_ 2560884478 DTCMilSupportFlash "Lamp support status";
CM_ SG_ 2560884478 DTCMilSupportStatus "Lamp support status";
CM_ SG_ 2560884478 DTCProtectLampSupportFlash "Lamp support status";
CM_ SG_ 2560884478 DTCProtectLampSupportStatus "Lamp support status";
CM_ SG_ 2560884478 DTCStopLampSupportFlash "Lamp support status";
CM_ SG_ 2560884478 DTCStopLampSupportStatus "Lamp support status";
CM_ SG_ 2560884478 DTCWarnLampSupportFlash "Lamp support status";
CM_ SG_ 2560884478 DTCWarnLampSupportStatus "Lamp support status";
CM_ BO_ 2560950014 "Scaled Test Results
This message conveys the scaled test results for the applicable test requested in DM7. The SPN and FMI convey the specific DTC for which the results are being reported.";
CM_ SG_ 2560950014 FailureModeIdentifier1 "The FMI defines the type of failure detected in the subsystem identified by an SPN.";
CM_ SG_ 2560950014 SlotId "The SLOT Identifer is used to determine the multiplier and offset to be used to scale the test value.";
CM_ SG_ 2560950014 SPN1 "This 19-bit number is used to identify the item for which diagnostics are being reported.";
CM_ SG_ 2560950014 SPN1High "SPN #1 (Conversion Version 4)";
CM_ SG_ 2560950014 TestIdentifier "Test Identifier";
CM_ SG_ 2560950014 TestLimitMaximum "The test value must be less than or equal to Test Limit Maximum in order for the test to pass.";
CM_ SG_ 2560950014 TestLimitMinimum "The test value must be greater than or equal to Test Limit Minimum in order for the test to pass";
CM_ SG_ 2560950014 TestValue "The test value collected during the test.";
CM_ BO_ 2566836478 "Test Results for Non-continuously Monitored Systems
The purpose of this response PG is to report the test results for one of the non-continuously monitored tests invoked using DM7";
CM_ SG_ 2566836478 TestIdentifier "The TID has 2 methods to designate the test to be run. The first method uses the TID alone and these test identifiers are manufacturer-defined test identifiers. For this first use there are 64 valid test identifiers, 1 to 64. The second method uses ...";
CM_ SG_ 2566836478 TestLimitMaximum "The test value must be less than or equal to Test Limit Maximum in order for the test to pass.";
CM_ SG_ 2566836478 TestLimitMinimum "The test value must be greater than or equal to Test Limit Minimum in order for the test to pass.";
CM_ SG_ 2566836478 TestType "This parameter identifies the non-continuously monitored component identifier that was tested. These component identifiers are defined by the manufacturer. They are necessary when multiple components or systems are present on the vehicle and have ...";
CM_ SG_ 2566836478 TestValue "The test value collected during the test. If the test performed does not have both a test limit minimum and maximum, then the appropriate limit value (Maximum or Minimum) should be set to all ones. SAE J1939-71 defines this to mean not available.";
CM_ BO_ 2565078782 "Command Non-continuously Monitored Test
The purpose of this command in the diagnostic process is to provide the ability to command On-Board Diagnostic monitoring tests of specific components/ systems that are not continuously monitored";
CM_ SG_ 2565078782 FailureModeIdentifier1 "This parameter identifies the failure mode identifier which represents the test(s) that shall be run on the component / system that will be tested.";
CM_ SG_ 2565078782 SPN1 "This parameter identifies the component / system that will be tested.";
CM_ SG_ 2565078782 SPN1High "SPN #1 (Conversion Version 4)";
CM_ SG_ 2565078782 TestIdentifier "The TID has 2 methods to designate the test to be run. The first method uses the TID alone and these test identifiers are manufacturer-defined test identifiers. For this first use there are 64 valid test identifiers, 1 to 64. The second method uses ...";
CM_ BO_ 2566836222 "Pending DTCs
The purpose of this DM is to enable the external test equipment to obtain “pending” diagnostic trouble codes detected during current or last completed driving cycle for emission-related components/systems.";
CM_ SG_ 2566836222 AmberWarningLampStatus "This lamp is used to relay trouble code information that is reporting a problem with the vehicle system but the vehicle need not be immediately stopped. 

00     Lamp Off
01     Lamp On
10     Reserved
11     Not available";
CM_ SG_ 2566836222 DTC1 "Diagnostic Trouble Code";
CM_ SG_ 2566836222 DTC2 "Diagnostic Trouble Code";
CM_ SG_ 2566836222 DTC3 "Diagnostic Trouble Code";
CM_ SG_ 2566836222 DTC4 "Diagnostic Trouble Code";
CM_ SG_ 2566836222 DTC5 "Diagnostic Trouble Code";
CM_ SG_ 2566836222 FlashAmberWarningLamp "This parameter provides the capability to flash the AWL

00 - Slow Flash (1 Hz, 50 % duty cycle)
01 - Fast Flash (2 Hz or faster, 50% duty cycle)
10 - Reserved
11 - Unavailable / Do Not Flash";
CM_ SG_ 2566836222 FlashMalfuncIndicatorLamp "This parameter provides the capability to flash the MIL
00 - Slow Flash (1 Hz, 50 % duty cycle)
01 - Fast Flash (2 Hz or faster, 50% duty cycle)
10 - Class C DTC
11 - Unavailable / Do Not Flash
Note:  State 10 is for WWH OBD discriminatory ...";
CM_ SG_ 2566836222 FlashProtectLamp "This parameter provides the capability to flash the engine protect lamp


00 - Slow Flash (1 Hz, 50 % duty cycle)
01 - Fast Flash (2 Hz or faster, 50% duty cycle)
10 - Reserved
11 - Unavailable / Do Not Flash";
CM_ SG_ 2566836222 FlashRedStopLamp "This parameter provides the capability to flash the RSL


00 - Slow Flash (1 Hz, 50 % duty cycle)
01 - Fast Flash (2 Hz or faster, 50% duty cycle)
10 - Reserved
11 - Unavailable / Do Not Flash";
CM_ SG_ 2566836222 MalfunctionIndicatorLampStatus "A lamp used to relay only emissions-related trouble code information. This lamp is only illuminated when there is an emission-related trouble code active.
00     Lamp Off
01     Lamp On
10     Short MIL for WWH OBD
11     Not available
Note ...";
CM_ SG_ 2566836222 ProtectLampStatus "This lamp is used to relay trouble code information that is reporting a problem with a vehicle system that is most probably not electronic subsystem related. For instance, engine coolant temperature is exceeding its prescribed temperature range.
00 ...";
CM_ SG_ 2566836222 RedStopLampState "This lamp is used to relay trouble code information that is of a severe enough condition that it warrants stopping the vehicle.

00     Lamp Off
01     Lamp On
10     Reserved
11     Not available";
CM_ BO_ 2566835966 "Diagnostic Readiness 1
Reports the diagnostics information that relates to diagnostic readiness.";
CM_ SG_ 2566835966 ActiveTroubleCodes "Identifies the number of active trouble codes that are present in a specific controller. If no DTCs are active, this field should be set to zero.";
CM_ SG_ 2566835966 OBDCompliance "Identifies the OBD compliance capability of the responding controller. Identifies the requirements level to which the controller was built.";
CM_ SG_ 2566835966 PreviouslyActiveTroubleCodes "Identifies the number of previously active trouble codes that are present in a specific controller. If no DTCs have been previously active, this field should be set to zero.";
CM_ BO_ 2566835710 "Freeze Frame Parameters
A freeze frame is defined as the list of recorded parameters at the time a diagnostic trouble code was captured";
CM_ SG_ 2566835710 DTC1 "Diagnostic Trouble Code";
CM_ SG_ 2566835710 EngCoolantTemp "Temperature of liquid found in engine cooling system.";
CM_ SG_ 2566835710 EngIntakeManifold1Press "The gage pressure measurement of the air intake manifold. If there are multiple air pressure sensors in the intake stream, this is the last one in flow direction before entering the combustion chamber.  This should be the pressure used to drive ...";
CM_ SG_ 2566835710 EngPercentLoadAtCurrentSpeed "The ratio of actual engine percent torque (indicated) to maximum indicated torque available at the current engine speed, clipped to zero torque during engine braking.";
CM_ SG_ 2566835710 EngSpeed "Actual engine speed which is calculated over a minimum crankshaft angle of 720 degrees divided by the number of cylinders.";
CM_ SG_ 2566835710 EngTorqueMode "State signal which indicates which engine torque mode is currently generating, limiting, or controlling the torque.  Note that the modes are not in prioritized order. Not all modes may be relevant for a given device.  Some devices may not implement ...";
CM_ SG_ 2566835710 FreezeFrameLength "The Freeze Frame Length shall be equal to the number of bytes in the required parameters plus the number of bytes in the manufacturer specific parameters.";
CM_ SG_ 2566835710 WheelBasedVehicleSpeed "Speed of the vehicle as calculated from wheel or tailshaft speed.";
CM_ BO_ 2566835454 "Diagnostics Data Clear/Reset for Previously Active DTCs";
CM_ BO_ 2566764542 "Expanded Freeze Frame
This message defines the expanded freeze frame length";
CM_ SG_ 2566764542 DTC1 "Diagnostic Trouble Code";
CM_ SG_ 2566764542 ExpandedFreezeFrameLength "The Freeze Frame Length is the length plus the number of bytes to convey the data of all parameters (SPNs) in Freeze Frame.";
CM_ BO_ 2566764286 "SPN Support
This message is used to identify those SPNs supported by the product for freeze frames and data stream messages.";
CM_ SG_ 2566764286 SPNDataLength1 "The number of data bytes associated with the SPN in the Freeze Frame.
The SPN data length is required to ensure old and new OBD tool compatibility with vehicle OBD Systems.  For instance, if the vehicle supports a new SPN then the tool will know ...";
CM_ SG_ 2566764286 SPNDataLength2 "The number of data bytes associated with the SPN in the Freeze Frame.";
CM_ SG_ 2566764286 SPNDataLength3 "The number of data bytes associated with the SPN in the Freeze Frame.";
CM_ SG_ 2566764286 SPNSupported1 "This parameter defines the SPN(s) that is/are supported for the freeze frame and/or data stream information.";
CM_ SG_ 2566764286 SPNSupported1High "This parameter defines the SPN(s) that is/are supported for the freeze frame and/or data stream information.";
CM_ SG_ 2566764286 SPNSupported2 "This parameter defines the SPN(s) that is/are supported for the freeze frame and/or data stream information.";
CM_ SG_ 2566764286 SPNSupported2High "This parameter defines the SPN(s) that is/are supported for the freeze frame and/or data stream information.";
CM_ SG_ 2566764286 SPNSupported3 "This parameter defines the SPN(s) that is/are supported for the freeze frame and/or data stream information.";
CM_ SG_ 2566764286 SPNSupported3High "This parameter defines the SPN(s) that is/are supported for the freeze frame and/or data stream information.";
CM_ SG_ 2566764286 SPNSupportTypeDS1 "This parameter defines whether the applicable parameter (that is the SPN) is supported in the Data Stream messages.";
CM_ SG_ 2566764286 SPNSupportTypeDS2 "This parameter defines whether the applicable parameter (that is the SPN) is supported in the freeze frame, the data stream or both the freeze frame and data stream.";
CM_ SG_ 2566764286 SPNSupportTypeDS3 "This parameter defines whether the applicable parameter (that is the SPN) is supported in the freeze frame, the data stream or both the freeze frame and data stream.";
CM_ SG_ 2566764286 SPNSupportTypeEFF1 "This parameter defines whether the applicable parameter (that is the SPN) is supported in the expanded freeze frame message, DM25.";
CM_ SG_ 2566764286 SPNSupportTypeEFF2 "This parameter defines whether the applicable parameter (that is the SPN) is supported in the freeze frame, the data stream or both the freeze frame and data stream.";
CM_ SG_ 2566764286 SPNSupportTypeEFF3 "This parameter defines whether the applicable parameter (that is the SPN) is supported in the freeze frame, the data stream or both the freeze frame and data stream.";
CM_ SG_ 2566764286 SPNSupportTypeSTR1 "This parameter defines whether the applicable parameter (that is the SPN) is supported in the Scaled Test Results message, DM30.";
CM_ SG_ 2566764286 SPNSupportTypeSTR2 "This parameter defines whether the applicable parameter (that is the SPN) is supported in the freeze frame, the data stream or both the freeze frame and data stream.";
CM_ SG_ 2566764286 SPNSupportTypeSTR3 "This parameter defines whether the applicable parameter (that is the SPN) is supported in the freeze frame, the data stream or both the freeze frame and data stream.";
CM_ BO_ 2566764030 "Previously Active Emission Related Faults
This message contains DTCs that are confirmed but for which the MIL is off.";
CM_ SG_ 2566764030 AmberWarningLampStatus "This lamp is used to relay trouble code information that is reporting a problem with the vehicle system but the vehicle need not be immediately stopped. 

00     Lamp Off
01     Lamp On
10     Reserved
11     Not available";
CM_ SG_ 2566764030 DTC1 "Diagnostic Trouble Code";
CM_ SG_ 2566764030 DTC2 "Diagnostic Trouble Code";
CM_ SG_ 2566764030 DTC3 "Diagnostic Trouble Code";
CM_ SG_ 2566764030 DTC4 "Diagnostic Trouble Code";
CM_ SG_ 2566764030 DTC5 "Diagnostic Trouble Code";
CM_ SG_ 2566764030 FlashAmberWarningLamp "This parameter provides the capability to flash the AWL

00 - Slow Flash (1 Hz, 50 % duty cycle)
01 - Fast Flash (2 Hz or faster, 50% duty cycle)
10 - Reserved
11 - Unavailable / Do Not Flash";
CM_ SG_ 2566764030 FlashMalfuncIndicatorLamp "This parameter provides the capability to flash the MIL
00 - Slow Flash (1 Hz, 50 % duty cycle)
01 - Fast Flash (2 Hz or faster, 50% duty cycle)
10 - Class C DTC
11 - Unavailable / Do Not Flash
Note:  State 10 is for WWH OBD discriminatory ...";
CM_ SG_ 2566764030 FlashProtectLamp "This parameter provides the capability to flash the engine protect lamp


00 - Slow Flash (1 Hz, 50 % duty cycle)
01 - Fast Flash (2 Hz or faster, 50% duty cycle)
10 - Reserved
11 - Unavailable / Do Not Flash";
CM_ SG_ 2566764030 FlashRedStopLamp "This parameter provides the capability to flash the RSL


00 - Slow Flash (1 Hz, 50 % duty cycle)
01 - Fast Flash (2 Hz or faster, 50% duty cycle)
10 - Reserved
11 - Unavailable / Do Not Flash";
CM_ SG_ 2566764030 MalfunctionIndicatorLampStatus "A lamp used to relay only emissions-related trouble code information. This lamp is only illuminated when there is an emission-related trouble code active.
00     Lamp Off
01     Lamp On
10     Short MIL for WWH OBD
11     Not available
Note ...";
CM_ SG_ 2566764030 ProtectLampStatus "This lamp is used to relay trouble code information that is reporting a problem with a vehicle system that is most probably not electronic subsystem related. For instance, engine coolant temperature is exceeding its prescribed temperature range.
00 ...";
CM_ SG_ 2566764030 RedStopLampState "This lamp is used to relay trouble code information that is of a severe enough condition that it warrants stopping the vehicle.

00     Lamp Off
01     Lamp On
10     Reserved
11     Not available";
BA_DEF_ SG_  "SigType" ENUM  "Default","Range","RangeSigned","ASCII","Discrete","Control","ReferencePGN","DTC","StringDelimiter","StringLength","StringLengthControl","MessageCounter","MessageChecksum";
BA_DEF_ SG_  "GenSigSendType" ENUM  "Cyclic","OnWrite","OnWriteWithRepetition","OnChange","OnChangeWithRepetition","IfActive","IfActiveWithRepetition","NoSigSendType";
BA_DEF_ SG_  "GenSigILSupport" ENUM  "No","Yes";
BA_DEF_ SG_  "GenSigEVName" STRING ;
BA_DEF_ SG_  "SPN" INT 0 524287;
BA_DEF_ BO_  "TpJ1939VarDlc" ENUM  "No","Yes";
BA_DEF_ BO_  "GenMsgILSupport" ENUM  "No","Yes";
BA_DEF_ BO_  "GenMsgRequestable" INT 0 1;
BA_DEF_ BO_  "GenMsgSendType" ENUM  "cyclic","NotUsed","NotUsed","NotUsed","NotUsed","NotUsed","NotUsed","IfActive","noMsgSendType";
BA_DEF_ BO_  "VFrameFormat" ENUM  "StandardCAN","ExtendedCAN","reserved","J1939PG";
BA_DEF_ BO_  "GenMsgCycleTime" INT 0 3600000;
BA_DEF_ BU_  "NodeLayerModules" STRING ;
BA_DEF_ BU_  "NmStationAddress" INT 0 255;
BA_DEF_ BU_  "NmJ1939Function" INT 0 255;
BA_DEF_ BU_  "NmJ1939ManufacturerCode" INT 0 2047;
BA_DEF_ BU_  "NmJ1939IdentityNumber" INT 0 2097151;
BA_DEF_  "SAE_J1939_DA_SpecVersion" STRING ;
BA_DEF_  "SAE_J1939_81_SpecVersion" STRING ;
BA_DEF_  "DatabaseVersion" STRING ;
BA_DEF_  "BusType" STRING ;
BA_DEF_  "ProtocolType" STRING ;
BA_DEF_  "SAE_J1939_75_SpecVersion" STRING ;
BA_DEF_  "SAE_J1939_21_SpecVersion" STRING ;
BA_DEF_  "SAE_J1939_73_SpecVersion" STRING ;
BA_DEF_  "SAE_J1939_71_SpecVersion" STRING ;
BA_DEF_DEF_  "SigType" "Default";
BA_DEF_DEF_  "GenSigSendType" "NoSigSendType";
BA_DEF_DEF_  "GenSigILSupport" "Yes";
BA_DEF_DEF_  "GenSigEVName" "Env@Nodename_@Signame";
BA_DEF_DEF_  "SPN" 0;
BA_DEF_DEF_  "TpJ1939VarDlc" "No";
BA_DEF_DEF_  "GenMsgILSupport" "Yes";
BA_DEF_DEF_  "GenMsgRequestable" 1;
BA_DEF_DEF_  "GenMsgSendType" "noMsgSendType";
BA_DEF_DEF_  "VFrameFormat" "J1939PG";
BA_DEF_DEF_  "GenMsgCycleTime" 0;
BA_DEF_DEF_  "NodeLayerModules" "";
BA_DEF_DEF_  "NmStationAddress" 254;
BA_DEF_DEF_  "NmJ1939Function" 0;
BA_DEF_DEF_  "NmJ1939ManufacturerCode" 0;
BA_DEF_DEF_  "NmJ1939IdentityNumber" 0;
BA_DEF_DEF_  "SAE_J1939_DA_SpecVersion" "";
BA_DEF_DEF_  "SAE_J1939_81_SpecVersion" "";
BA_DEF_DEF_  "DatabaseVersion" "";
BA_DEF_DEF_  "BusType" "";
BA_DEF_DEF_  "ProtocolType" "";
BA_DEF_DEF_  "SAE_J1939_75_SpecVersion" "";
BA_DEF_DEF_  "SAE_J1939_21_SpecVersion" "";
BA_DEF_DEF_  "SAE_J1939_73_SpecVersion" "";
BA_DEF_DEF_  "SAE_J1939_71_SpecVersion" "";
BA_ "SAE_J1939_DA_SpecVersion" "2020-01";
BA_ "SAE_J1939_81_SpecVersion" "2017-03";
BA_ "DatabaseVersion" "13.0";
BA_ "BusType" "CAN";
BA_ "ProtocolType" "J1939";
BA_ "SAE_J1939_75_SpecVersion" "2015-11";
BA_ "SAE_J1939_21_SpecVersion" "2018-10";
BA_ "SAE_J1939_73_SpecVersion" "2019-01";
BA_ "SAE_J1939_71_SpecVersion" "2020-02";
BA_ "NmStationAddress" BU_ Tester 253;
BA_ "NmStationAddress" BU_ TirePressureController 51;
BA_ "NmJ1939Function" BU_ TirePressureController 38;
BA_ "NodeLayerModules" BU_ TirePressureController "J1939_IL.vmodule";
BA_ "NmJ1939ManufacturerCode" BU_ TirePressureController 1861;
BA_ "NmJ1939IdentityNumber" BU_ TirePressureController 603215;
BA_ "TpJ1939VarDlc" BO_ 2558525182 1;
BA_ "TpJ1939VarDlc" BO_ 2566670078 1;
BA_ "GenMsgSendType" BO_ 2566669054 0;
BA_ "GenMsgCycleTime" BO_ 2566669054 10000;
BA_ "TpJ1939VarDlc" BO_ 2566702846 1;
BA_ "TpJ1939VarDlc" BO_ 2566703102 1;
BA_ "TpJ1939VarDlc" BO_ 2566705918 1;
BA_ "TpJ1939VarDlc" BO_ 2566705662 1;
BA_ "TpJ1939VarDlc" BO_ 2560818942 1;
BA_ "TpJ1939VarDlc" BO_ 2564095742 1;
BA_ "GenMsgSendType" BO_ 2566845694 0;
BA_ "GenMsgCycleTime" BO_ 2566845694 10000;
BA_ "TpJ1939VarDlc" BO_ 2566839038 1;
BA_ "TpJ1939VarDlc" BO_ 2566768126 1;
BA_ "TpJ1939VarDlc" BO_ 2566742270 1;
BA_ "TpJ1939VarDlc" BO_ 2566742782 1;
BA_ "TpJ1939VarDlc" BO_ 2560687870 1;
BA_ "TpJ1939VarDlc" BO_ 2292317950 1;
BA_ "TpJ1939VarDlc" BO_ 2560884478 1;
BA_ "TpJ1939VarDlc" BO_ 2560950014 1;
BA_ "TpJ1939VarDlc" BO_ 2566836478 1;
BA_ "TpJ1939VarDlc" BO_ 2566836222 1;
BA_ "TpJ1939VarDlc" BO_ 2566835710 1;
BA_ "TpJ1939VarDlc" BO_ 2566764542 1;
BA_ "TpJ1939VarDlc" BO_ 2566764286 1;
BA_ "TpJ1939VarDlc" BO_ 2566764030 1;
BA_ "SPN" SG_ 2565799678 ArbitraryAddressCapable 2844;
BA_ "SPN" SG_ 2565799678 IndustryGroup 2846;
BA_ "SPN" SG_ 2565799678 VehicleSystemInstance 2843;
BA_ "SPN" SG_ 2565799678 Function 2841;
BA_ "SPN" SG_ 2565799678 FunctionInstance 2839;
BA_ "SPN" SG_ 2565799678 ECUInstance 2840;
BA_ "SigType" SG_ 2565799678 ManufacturerCode 1;
BA_ "SPN" SG_ 2565799678 ManufacturerCode 2838;
BA_ "SPN" SG_ 2565799678 IdentityNumber 2837;
BA_ "SigType" SG_ 2558721790 ExtrmUndrPrssPrcntgThrshldStting 1;
BA_ "SPN" SG_ 2558721790 ExtrmUndrPrssPrcntgThrshldStting 6976;
BA_ "SigType" SG_ 2558721790 OverTempSetting 1;
BA_ "SPN" SG_ 2558721790 OverTempSetting 6978;
BA_ "SigType" SG_ 2558721790 OvrPrssPrcentageThresholdSetting 1;
BA_ "SPN" SG_ 2558721790 OvrPrssPrcentageThresholdSetting 6977;
BA_ "SigType" SG_ 2558721790 SnsrEnableSetting 5;
BA_ "SPN" SG_ 2558721790 SnsrEnableSetting 7587;
BA_ "SPN" SG_ 2558721790 TireLocation 6973;
BA_ "SigType" SG_ 2558721790 UndrPrssPrcntageThresholdSetting 1;
BA_ "SPN" SG_ 2558721790 UndrPrssPrcntageThresholdSetting 6975;
BA_ "SPN" SG_ 2558525182 Location 7585;
BA_ "SigType" SG_ 2558525182 Num 1;
BA_ "SPN" SG_ 2558525182 Num 7584;
BA_ "SigType" SG_ 2558525182 Num7586 8;
BA_ "SPN" SG_ 2558525182 Num7586 7586;
BA_ "SigType" SG_ 2558525182 NumOfTireSensors 1;
BA_ "SPN" SG_ 2558525182 NumOfTireSensors 7583;
BA_ "SigType" SG_ 2566670078 NumberOfTireSensors 1;
BA_ "SPN" SG_ 2566670078 NumberOfTireSensors 6963;
BA_ "SigType" SG_ 2566670078 TireSensorIdentificationNumber 8;
BA_ "SPN" SG_ 2566670078 TireSensorIdentificationNumber 6966;
BA_ "SPN" SG_ 2566670078 TireSensorLocation 6965;
BA_ "SigType" SG_ 2566670078 TireSensorTireNumber 1;
BA_ "SPN" SG_ 2566670078 TireSensorTireNumber 6964;
BA_ "SigType" SG_ 2566669054 RequiredTirePress 1;
BA_ "SPN" SG_ 2566669054 RequiredTirePress 6989;
BA_ "SPN" SG_ 2566669054 TireLocation 6987;
BA_ "SigType" SG_ 2566669054 TirePress 1;
BA_ "SPN" SG_ 2566669054 TirePress 6988;
BA_ "SigType" SG_ 2566702846 EngOBDWarmUpSequence 5;
BA_ "SPN" SG_ 2566702846 EngOBDWarmUpSequence 5843;
BA_ "SPN" SG_ 2566703102 CertificationEngineFamilyName 5845;
BA_ "SigType" SG_ 2566703102 ModelYear 3;
BA_ "SPN" SG_ 2566703102 ModelYear 5844;
BA_ "SigType" SG_ 2566705918 AmberWarningLampStatus 5;
BA_ "SPN" SG_ 2566705918 AmberWarningLampStatus 624;
BA_ "SigType" SG_ 2566705918 DTC1 7;
BA_ "SigType" SG_ 2566705918 DTC2 7;
BA_ "SigType" SG_ 2566705918 DTC3 7;
BA_ "SigType" SG_ 2566705918 DTC4 7;
BA_ "SigType" SG_ 2566705918 DTC5 7;
BA_ "SigType" SG_ 2566705918 FlashAmberWarningLamp 5;
BA_ "SPN" SG_ 2566705918 FlashAmberWarningLamp 3040;
BA_ "SigType" SG_ 2566705918 FlashMalfuncIndicatorLamp 5;
BA_ "SPN" SG_ 2566705918 FlashMalfuncIndicatorLamp 3038;
BA_ "SigType" SG_ 2566705918 FlashProtectLamp 5;
BA_ "SPN" SG_ 2566705918 FlashProtectLamp 3041;
BA_ "SigType" SG_ 2566705918 FlashRedStopLamp 5;
BA_ "SPN" SG_ 2566705918 FlashRedStopLamp 3039;
BA_ "SigType" SG_ 2566705918 MalfunctionIndicatorLampStatus 5;
BA_ "SPN" SG_ 2566705918 MalfunctionIndicatorLampStatus 1213;
BA_ "SigType" SG_ 2566705918 ProtectLampStatus 5;
BA_ "SPN" SG_ 2566705918 ProtectLampStatus 987;
BA_ "SigType" SG_ 2566705918 RedStopLampState 4;
BA_ "SPN" SG_ 2566705918 RedStopLampState 623;
BA_ "SigType" SG_ 2566705662 AmberWarningLampStatus 5;
BA_ "SPN" SG_ 2566705662 AmberWarningLampStatus 624;
BA_ "SigType" SG_ 2566705662 DTC1 7;
BA_ "SigType" SG_ 2566705662 DTC2 7;
BA_ "SigType" SG_ 2566705662 DTC3 7;
BA_ "SigType" SG_ 2566705662 DTC4 7;
BA_ "SigType" SG_ 2566705662 DTC5 7;
BA_ "SigType" SG_ 2566705662 FlashAmberWarningLamp 5;
BA_ "SPN" SG_ 2566705662 FlashAmberWarningLamp 3040;
BA_ "SigType" SG_ 2566705662 FlashMalfuncIndicatorLamp 5;
BA_ "SPN" SG_ 2566705662 FlashMalfuncIndicatorLamp 3038;
BA_ "SigType" SG_ 2566705662 FlashProtectLamp 5;
BA_ "SPN" SG_ 2566705662 FlashProtectLamp 3041;
BA_ "SigType" SG_ 2566705662 FlashRedStopLamp 5;
BA_ "SPN" SG_ 2566705662 FlashRedStopLamp 3039;
BA_ "SigType" SG_ 2566705662 MalfunctionIndicatorLampStatus 5;
BA_ "SPN" SG_ 2566705662 MalfunctionIndicatorLampStatus 1213;
BA_ "SigType" SG_ 2566705662 ProtectLampStatus 5;
BA_ "SPN" SG_ 2566705662 ProtectLampStatus 987;
BA_ "SigType" SG_ 2566705662 RedStopLampState 4;
BA_ "SPN" SG_ 2566705662 RedStopLampState 623;
BA_ "SigType" SG_ 2560818942 DTCTimeUntilDerate 1;
BA_ "SPN" SG_ 2560818942 DTCTimeUntilDerate 4123;
BA_ "SigType" SG_ 2560818942 DTCTotalActiveTime 1;
BA_ "SPN" SG_ 2560818942 DTCTotalActiveTime 4121;
BA_ "SigType" SG_ 2560818942 DTCTotalPreviouslyActiveTime 1;
BA_ "SPN" SG_ 2560818942 DTCTotalPreviouslyActiveTime 4122;
BA_ "SPN" SG_ 2560818942 FailureModeIdentifier1 1215;
BA_ "SPN" SG_ 2560818942 SPN1 1214;
BA_ "SigType" SG_ 2566764798 NumOfWarmUpsSinceDTCsCleared 1;
BA_ "SPN" SG_ 2566764798 NumOfWarmUpsSinceDTCsCleared 3302;
BA_ "SigType" SG_ 2566764798 TimeSinceEngineStart 1;
BA_ "SPN" SG_ 2566764798 TimeSinceEngineStart 3301;
BA_ "SPN" SG_ 2564095742 DataSecurityParameter 1597;
BA_ "SPN" SG_ 2564095742 SecurityEntityLength 1596;
BA_ "SPN" SG_ 2564095742 SecurityEntityType 1479;
BA_ "SigType" SG_ 2561605374 ReferenceTirePressSetting_00 1;
BA_ "SPN" SG_ 2561605374 ReferenceTirePressSetting_00 521800;
BA_ "SigType" SG_ 2561605374 ReferenceTirePressSetting_01 1;
BA_ "SPN" SG_ 2561605374 ReferenceTirePressSetting_01 521801;
BA_ "SigType" SG_ 2561605374 ReferenceTirePressSetting_10 1;
BA_ "SPN" SG_ 2561605374 ReferenceTirePressSetting_10 521810;
BA_ "SigType" SG_ 2561605374 ReferenceTirePressSetting_11 1;
BA_ "SPN" SG_ 2561605374 ReferenceTirePressSetting_11 521811;
BA_ "SigType" SG_ 2561605374 ReferenceTirePressSetting_12 1;
BA_ "SPN" SG_ 2561605374 ReferenceTirePressSetting_12 521812;
BA_ "SigType" SG_ 2561605374 ReferenceTirePressSetting_13 1;
BA_ "SPN" SG_ 2561605374 ReferenceTirePressSetting_13 521813;
BA_ "SigType" SG_ 2561605374 ReferenceTirePressSetting_20 1;
BA_ "SPN" SG_ 2561605374 ReferenceTirePressSetting_20 521820;
BA_ "SigType" SG_ 2561605374 ReferenceTirePressSetting_21 1;
BA_ "SPN" SG_ 2561605374 ReferenceTirePressSetting_21 521821;
BA_ "SigType" SG_ 2561605374 ReferenceTirePressSetting_22 1;
BA_ "SPN" SG_ 2561605374 ReferenceTirePressSetting_22 521822;
BA_ "SigType" SG_ 2561605374 ReferenceTirePressSetting_23 1;
BA_ "SPN" SG_ 2561605374 ReferenceTirePressSetting_23 521823;
BA_ "SigType" SG_ 2561605374 ReferenceTirePressSetting_30 1;
BA_ "SPN" SG_ 2561605374 ReferenceTirePressSetting_30 521830;
BA_ "SigType" SG_ 2561605374 ReferenceTirePressSetting_31 1;
BA_ "SPN" SG_ 2561605374 ReferenceTirePressSetting_31 521831;
BA_ "SigType" SG_ 2561605374 ReferenceTirePressSetting_32 1;
BA_ "SPN" SG_ 2561605374 ReferenceTirePressSetting_32 521832;
BA_ "SigType" SG_ 2561605374 ReferenceTirePressSetting_33 1;
BA_ "SPN" SG_ 2561605374 ReferenceTirePressSetting_33 521833;
BA_ "SPN" SG_ 2561605374 TireLocation 3192;
BA_ "SigType" SG_ 2566765054 ReferenceTirePress_00 1;
BA_ "SPN" SG_ 2566765054 ReferenceTirePress_00 521900;
BA_ "SigType" SG_ 2566765054 ReferenceTirePress_01 1;
BA_ "SPN" SG_ 2566765054 ReferenceTirePress_01 521901;
BA_ "SigType" SG_ 2566765054 ReferenceTirePress_10 1;
BA_ "SPN" SG_ 2566765054 ReferenceTirePress_10 521910;
BA_ "SigType" SG_ 2566765054 ReferenceTirePress_11 1;
BA_ "SPN" SG_ 2566765054 ReferenceTirePress_11 521911;
BA_ "SigType" SG_ 2566765054 ReferenceTirePress_12 1;
BA_ "SPN" SG_ 2566765054 ReferenceTirePress_12 521912;
BA_ "SigType" SG_ 2566765054 ReferenceTirePress_13 1;
BA_ "SPN" SG_ 2566765054 ReferenceTirePress_13 521913;
BA_ "SigType" SG_ 2566765054 ReferenceTirePress_20 1;
BA_ "SPN" SG_ 2566765054 ReferenceTirePress_20 521920;
BA_ "SigType" SG_ 2566765054 ReferenceTirePress_21 1;
BA_ "SPN" SG_ 2566765054 ReferenceTirePress_21 521921;
BA_ "SigType" SG_ 2566765054 ReferenceTirePress_22 1;
BA_ "SPN" SG_ 2566765054 ReferenceTirePress_22 521922;
BA_ "SigType" SG_ 2566765054 ReferenceTirePress_23 1;
BA_ "SPN" SG_ 2566765054 ReferenceTirePress_23 521923;
BA_ "SigType" SG_ 2566765054 ReferenceTirePress_30 1;
BA_ "SPN" SG_ 2566765054 ReferenceTirePress_30 521930;
BA_ "SigType" SG_ 2566765054 ReferenceTirePress_31 1;
BA_ "SPN" SG_ 2566765054 ReferenceTirePress_31 521931;
BA_ "SigType" SG_ 2566765054 ReferenceTirePress_32 1;
BA_ "SPN" SG_ 2566765054 ReferenceTirePress_32 521932;
BA_ "SigType" SG_ 2566765054 ReferenceTirePress_33 1;
BA_ "SPN" SG_ 2566765054 ReferenceTirePress_33 521933;
BA_ "SPN" SG_ 2566765054 TireLocation 3190;
BA_ "SigType" SG_ 2633923326 DriveChannelTirePress 1;
BA_ "SPN" SG_ 2633923326 DriveChannelTirePress 145;
BA_ "SigType" SG_ 2633923326 SteerChannelTirePress 1;
BA_ "SPN" SG_ 2633923326 SteerChannelTirePress 146;
BA_ "SigType" SG_ 2633923326 TrailerTagOrPushChannelTirePress 1;
BA_ "SPN" SG_ 2633923326 TrailerTagOrPushChannelTirePress 144;
BA_ "SigType" SG_ 2633923070 DriveChannelTirePressTarget 1;
BA_ "SPN" SG_ 2633923070 DriveChannelTirePressTarget 142;
BA_ "SigType" SG_ 2633923070 SteerChannelTirePressTarget 1;
BA_ "SPN" SG_ 2633923070 SteerChannelTirePressTarget 143;
BA_ "SigType" SG_ 2633923070 TrlrTgOrPshChnnelTirePressTarget 1;
BA_ "SPN" SG_ 2633923070 TrlrTgOrPshChnnelTirePressTarget 141;
BA_ "SPN" SG_ 2633922814 DriveChannelMode 1468;
BA_ "SigType" SG_ 2633922814 PCUCtrlSolenoidStatus 5;
BA_ "SPN" SG_ 2633922814 PCUCtrlSolenoidStatus 1473;
BA_ "SigType" SG_ 2633922814 PCUDeflateSolenoidStatus 5;
BA_ "SPN" SG_ 2633922814 PCUDeflateSolenoidStatus 1472;
BA_ "SigType" SG_ 2633922814 PCUDriveSolenoidStatus 5;
BA_ "SPN" SG_ 2633922814 PCUDriveSolenoidStatus 1469;
BA_ "SigType" SG_ 2633922814 PCUSteerSolenoidStatus 5;
BA_ "SPN" SG_ 2633922814 PCUSteerSolenoidStatus 1470;
BA_ "SigType" SG_ 2633922814 PCUSupplySolenoidStatus 5;
BA_ "SPN" SG_ 2633922814 PCUSupplySolenoidStatus 1474;
BA_ "SigType" SG_ 2633922814 PCUTrilerTagOrPushSolenoidStatus 5;
BA_ "SPN" SG_ 2633922814 PCUTrilerTagOrPushSolenoidStatus 1475;
BA_ "SPN" SG_ 2633922814 SteerChannelMode 1466;
BA_ "SigType" SG_ 2633922814 TirePressCheckInterval 1;
BA_ "SPN" SG_ 2633922814 TirePressCheckInterval 39;
BA_ "SigType" SG_ 2633922814 TirePressSupplySwitchStatus 5;
BA_ "SPN" SG_ 2633922814 TirePressSupplySwitchStatus 1471;
BA_ "SPN" SG_ 2633922814 Trailer_tagChannelMode 1467;
BA_ "SigType" SG_ 2566845694 CTITireStatus_00 4;
BA_ "SPN" SG_ 2566845694 CTITireStatus_00 521300;
BA_ "SigType" SG_ 2566845694 CTITireStatus_01 4;
BA_ "SPN" SG_ 2566845694 CTITireStatus_01 521301;
BA_ "SigType" SG_ 2566845694 CTITireStatus_10 4;
BA_ "SPN" SG_ 2566845694 CTITireStatus_10 521310;
BA_ "SigType" SG_ 2566845694 CTITireStatus_11 4;
BA_ "SPN" SG_ 2566845694 CTITireStatus_11 521311;
BA_ "SigType" SG_ 2566845694 CTITireStatus_12 4;
BA_ "SPN" SG_ 2566845694 CTITireStatus_12 521312;
BA_ "SigType" SG_ 2566845694 CTITireStatus_13 4;
BA_ "SPN" SG_ 2566845694 CTITireStatus_13 521313;
BA_ "SigType" SG_ 2566845694 CTITireStatus_20 4;
BA_ "SPN" SG_ 2566845694 CTITireStatus_20 521320;
BA_ "SigType" SG_ 2566845694 CTITireStatus_21 4;
BA_ "SPN" SG_ 2566845694 CTITireStatus_21 521321;
BA_ "SigType" SG_ 2566845694 CTITireStatus_22 4;
BA_ "SPN" SG_ 2566845694 CTITireStatus_22 521322;
BA_ "SigType" SG_ 2566845694 CTITireStatus_23 4;
BA_ "SPN" SG_ 2566845694 CTITireStatus_23 521323;
BA_ "SigType" SG_ 2566845694 CTITireStatus_30 4;
BA_ "SPN" SG_ 2566845694 CTITireStatus_30 521330;
BA_ "SigType" SG_ 2566845694 CTITireStatus_31 4;
BA_ "SPN" SG_ 2566845694 CTITireStatus_31 521331;
BA_ "SigType" SG_ 2566845694 CTITireStatus_32 4;
BA_ "SPN" SG_ 2566845694 CTITireStatus_32 521332;
BA_ "SigType" SG_ 2566845694 CTITireStatus_33 4;
BA_ "SPN" SG_ 2566845694 CTITireStatus_33 521333;
BA_ "SigType" SG_ 2566845694 CTIWheelEndElectricalFault_00 4;
BA_ "SPN" SG_ 2566845694 CTIWheelEndElectricalFault_00 521200;
BA_ "SigType" SG_ 2566845694 CTIWheelEndElectricalFault_01 4;
BA_ "SPN" SG_ 2566845694 CTIWheelEndElectricalFault_01 521201;
BA_ "SigType" SG_ 2566845694 CTIWheelEndElectricalFault_10 4;
BA_ "SPN" SG_ 2566845694 CTIWheelEndElectricalFault_10 521210;
BA_ "SigType" SG_ 2566845694 CTIWheelEndElectricalFault_11 4;
BA_ "SPN" SG_ 2566845694 CTIWheelEndElectricalFault_11 521211;
BA_ "SigType" SG_ 2566845694 CTIWheelEndElectricalFault_12 4;
BA_ "SPN" SG_ 2566845694 CTIWheelEndElectricalFault_12 521212;
BA_ "SigType" SG_ 2566845694 CTIWheelEndElectricalFault_13 4;
BA_ "SPN" SG_ 2566845694 CTIWheelEndElectricalFault_13 521213;
BA_ "SigType" SG_ 2566845694 CTIWheelEndElectricalFault_20 4;
BA_ "SPN" SG_ 2566845694 CTIWheelEndElectricalFault_20 521220;
BA_ "SigType" SG_ 2566845694 CTIWheelEndElectricalFault_21 4;
BA_ "SPN" SG_ 2566845694 CTIWheelEndElectricalFault_21 521221;
BA_ "SigType" SG_ 2566845694 CTIWheelEndElectricalFault_22 4;
BA_ "SPN" SG_ 2566845694 CTIWheelEndElectricalFault_22 521222;
BA_ "SigType" SG_ 2566845694 CTIWheelEndElectricalFault_23 4;
BA_ "SPN" SG_ 2566845694 CTIWheelEndElectricalFault_23 521223;
BA_ "SigType" SG_ 2566845694 CTIWheelEndElectricalFault_30 4;
BA_ "SPN" SG_ 2566845694 CTIWheelEndElectricalFault_30 521230;
BA_ "SigType" SG_ 2566845694 CTIWheelEndElectricalFault_31 4;
BA_ "SPN" SG_ 2566845694 CTIWheelEndElectricalFault_31 521231;
BA_ "SigType" SG_ 2566845694 CTIWheelEndElectricalFault_32 4;
BA_ "SPN" SG_ 2566845694 CTIWheelEndElectricalFault_32 521232;
BA_ "SigType" SG_ 2566845694 CTIWheelEndElectricalFault_33 4;
BA_ "SPN" SG_ 2566845694 CTIWheelEndElectricalFault_33 521233;
BA_ "SigType" SG_ 2566845694 CTIWheelSensorStatus_00 4;
BA_ "SPN" SG_ 2566845694 CTIWheelSensorStatus_00 521400;
BA_ "SigType" SG_ 2566845694 CTIWheelSensorStatus_01 4;
BA_ "SPN" SG_ 2566845694 CTIWheelSensorStatus_01 521401;
BA_ "SigType" SG_ 2566845694 CTIWheelSensorStatus_10 4;
BA_ "SPN" SG_ 2566845694 CTIWheelSensorStatus_10 521410;
BA_ "SigType" SG_ 2566845694 CTIWheelSensorStatus_11 4;
BA_ "SPN" SG_ 2566845694 CTIWheelSensorStatus_11 521411;
BA_ "SigType" SG_ 2566845694 CTIWheelSensorStatus_12 4;
BA_ "SPN" SG_ 2566845694 CTIWheelSensorStatus_12 521412;
BA_ "SigType" SG_ 2566845694 CTIWheelSensorStatus_13 4;
BA_ "SPN" SG_ 2566845694 CTIWheelSensorStatus_13 521413;
BA_ "SigType" SG_ 2566845694 CTIWheelSensorStatus_20 4;
BA_ "SPN" SG_ 2566845694 CTIWheelSensorStatus_20 521420;
BA_ "SigType" SG_ 2566845694 CTIWheelSensorStatus_21 4;
BA_ "SPN" SG_ 2566845694 CTIWheelSensorStatus_21 521421;
BA_ "SigType" SG_ 2566845694 CTIWheelSensorStatus_22 4;
BA_ "SPN" SG_ 2566845694 CTIWheelSensorStatus_22 521422;
BA_ "SigType" SG_ 2566845694 CTIWheelSensorStatus_23 4;
BA_ "SPN" SG_ 2566845694 CTIWheelSensorStatus_23 521423;
BA_ "SigType" SG_ 2566845694 CTIWheelSensorStatus_30 4;
BA_ "SPN" SG_ 2566845694 CTIWheelSensorStatus_30 521430;
BA_ "SigType" SG_ 2566845694 CTIWheelSensorStatus_31 4;
BA_ "SPN" SG_ 2566845694 CTIWheelSensorStatus_31 521431;
BA_ "SigType" SG_ 2566845694 CTIWheelSensorStatus_32 4;
BA_ "SPN" SG_ 2566845694 CTIWheelSensorStatus_32 521432;
BA_ "SigType" SG_ 2566845694 CTIWheelSensorStatus_33 4;
BA_ "SPN" SG_ 2566845694 CTIWheelSensorStatus_33 521433;
BA_ "SigType" SG_ 2566845694 ExTirePressSupport 4;
BA_ "SPN" SG_ 2566845694 ExTirePressSupport 6990;
BA_ "SigType" SG_ 2566845694 TireAirLeakageRate_00 1;
BA_ "SPN" SG_ 2566845694 TireAirLeakageRate_00 521500;
BA_ "SigType" SG_ 2566845694 TireAirLeakageRate_01 1;
BA_ "SPN" SG_ 2566845694 TireAirLeakageRate_01 521501;
BA_ "SigType" SG_ 2566845694 TireAirLeakageRate_10 1;
BA_ "SPN" SG_ 2566845694 TireAirLeakageRate_10 521510;
BA_ "SigType" SG_ 2566845694 TireAirLeakageRate_11 1;
BA_ "SPN" SG_ 2566845694 TireAirLeakageRate_11 521511;
BA_ "SigType" SG_ 2566845694 TireAirLeakageRate_12 1;
BA_ "SPN" SG_ 2566845694 TireAirLeakageRate_12 521512;
BA_ "SigType" SG_ 2566845694 TireAirLeakageRate_13 1;
BA_ "SPN" SG_ 2566845694 TireAirLeakageRate_13 521513;
BA_ "SigType" SG_ 2566845694 TireAirLeakageRate_20 1;
BA_ "SPN" SG_ 2566845694 TireAirLeakageRate_20 521520;
BA_ "SigType" SG_ 2566845694 TireAirLeakageRate_21 1;
BA_ "SPN" SG_ 2566845694 TireAirLeakageRate_21 521521;
BA_ "SigType" SG_ 2566845694 TireAirLeakageRate_22 1;
BA_ "SPN" SG_ 2566845694 TireAirLeakageRate_22 521522;
BA_ "SigType" SG_ 2566845694 TireAirLeakageRate_23 1;
BA_ "SPN" SG_ 2566845694 TireAirLeakageRate_23 521523;
BA_ "SigType" SG_ 2566845694 TireAirLeakageRate_30 1;
BA_ "SPN" SG_ 2566845694 TireAirLeakageRate_30 521530;
BA_ "SigType" SG_ 2566845694 TireAirLeakageRate_31 1;
BA_ "SPN" SG_ 2566845694 TireAirLeakageRate_31 521531;
BA_ "SigType" SG_ 2566845694 TireAirLeakageRate_32 1;
BA_ "SPN" SG_ 2566845694 TireAirLeakageRate_32 521532;
BA_ "SigType" SG_ 2566845694 TireAirLeakageRate_33 1;
BA_ "SPN" SG_ 2566845694 TireAirLeakageRate_33 521533;
BA_ "SPN" SG_ 2566845694 TireLocation 929;
BA_ "SigType" SG_ 2566845694 TirePress_00 1;
BA_ "SPN" SG_ 2566845694 TirePress_00 521000;
BA_ "SigType" SG_ 2566845694 TirePress_01 1;
BA_ "SPN" SG_ 2566845694 TirePress_01 521001;
BA_ "SigType" SG_ 2566845694 TirePress_10 1;
BA_ "SPN" SG_ 2566845694 TirePress_10 521010;
BA_ "SigType" SG_ 2566845694 TirePress_11 1;
BA_ "SPN" SG_ 2566845694 TirePress_11 521011;
BA_ "SigType" SG_ 2566845694 TirePress_12 1;
BA_ "SPN" SG_ 2566845694 TirePress_12 521012;
BA_ "SigType" SG_ 2566845694 TirePress_13 1;
BA_ "SPN" SG_ 2566845694 TirePress_13 521013;
BA_ "SigType" SG_ 2566845694 TirePress_20 1;
BA_ "SPN" SG_ 2566845694 TirePress_20 521020;
BA_ "SigType" SG_ 2566845694 TirePress_21 1;
BA_ "SPN" SG_ 2566845694 TirePress_21 521021;
BA_ "SigType" SG_ 2566845694 TirePress_22 1;
BA_ "SPN" SG_ 2566845694 TirePress_22 521022;
BA_ "SigType" SG_ 2566845694 TirePress_23 1;
BA_ "SPN" SG_ 2566845694 TirePress_23 521023;
BA_ "SigType" SG_ 2566845694 TirePress_30 1;
BA_ "SPN" SG_ 2566845694 TirePress_30 521030;
BA_ "SigType" SG_ 2566845694 TirePress_31 1;
BA_ "SPN" SG_ 2566845694 TirePress_31 521031;
BA_ "SigType" SG_ 2566845694 TirePress_32 1;
BA_ "SPN" SG_ 2566845694 TirePress_32 521032;
BA_ "SigType" SG_ 2566845694 TirePress_33 1;
BA_ "SPN" SG_ 2566845694 TirePress_33 521033;
BA_ "SPN" SG_ 2566845694 TirePressThresholdDetection_00 521600;
BA_ "SPN" SG_ 2566845694 TirePressThresholdDetection_01 521601;
BA_ "SPN" SG_ 2566845694 TirePressThresholdDetection_10 521610;
BA_ "SPN" SG_ 2566845694 TirePressThresholdDetection_11 521611;
BA_ "SPN" SG_ 2566845694 TirePressThresholdDetection_12 521612;
BA_ "SPN" SG_ 2566845694 TirePressThresholdDetection_13 521613;
BA_ "SPN" SG_ 2566845694 TirePressThresholdDetection_20 521620;
BA_ "SPN" SG_ 2566845694 TirePressThresholdDetection_21 521621;
BA_ "SPN" SG_ 2566845694 TirePressThresholdDetection_22 521622;
BA_ "SPN" SG_ 2566845694 TirePressThresholdDetection_23 521623;
BA_ "SPN" SG_ 2566845694 TirePressThresholdDetection_30 521630;
BA_ "SPN" SG_ 2566845694 TirePressThresholdDetection_31 521631;
BA_ "SPN" SG_ 2566845694 TirePressThresholdDetection_32 521632;
BA_ "SPN" SG_ 2566845694 TirePressThresholdDetection_33 521633;
BA_ "SigType" SG_ 2566845694 TireTemp_00 1;
BA_ "SPN" SG_ 2566845694 TireTemp_00 521100;
BA_ "SigType" SG_ 2566845694 TireTemp_01 1;
BA_ "SPN" SG_ 2566845694 TireTemp_01 521101;
BA_ "SigType" SG_ 2566845694 TireTemp_10 1;
BA_ "SPN" SG_ 2566845694 TireTemp_10 521110;
BA_ "SigType" SG_ 2566845694 TireTemp_11 1;
BA_ "SPN" SG_ 2566845694 TireTemp_11 521111;
BA_ "SigType" SG_ 2566845694 TireTemp_12 1;
BA_ "SPN" SG_ 2566845694 TireTemp_12 521112;
BA_ "SigType" SG_ 2566845694 TireTemp_13 1;
BA_ "SPN" SG_ 2566845694 TireTemp_13 521113;
BA_ "SigType" SG_ 2566845694 TireTemp_20 1;
BA_ "SPN" SG_ 2566845694 TireTemp_20 521120;
BA_ "SigType" SG_ 2566845694 TireTemp_21 1;
BA_ "SPN" SG_ 2566845694 TireTemp_21 521121;
BA_ "SigType" SG_ 2566845694 TireTemp_22 1;
BA_ "SPN" SG_ 2566845694 TireTemp_22 521122;
BA_ "SigType" SG_ 2566845694 TireTemp_23 1;
BA_ "SPN" SG_ 2566845694 TireTemp_23 521123;
BA_ "SigType" SG_ 2566845694 TireTemp_30 1;
BA_ "SPN" SG_ 2566845694 TireTemp_30 521130;
BA_ "SigType" SG_ 2566845694 TireTemp_31 1;
BA_ "SPN" SG_ 2566845694 TireTemp_31 521131;
BA_ "SigType" SG_ 2566845694 TireTemp_32 1;
BA_ "SPN" SG_ 2566845694 TireTemp_32 521132;
BA_ "SigType" SG_ 2566845694 TireTemp_33 1;
BA_ "SPN" SG_ 2566845694 TireTemp_33 521133;
BA_ "SigType" SG_ 2566839038 NmbrOfSftwreIdentificationFields 1;
BA_ "SPN" SG_ 2566839038 NmbrOfSftwreIdentificationFields 965;
BA_ "SigType" SG_ 2566839038 SoftwareIdentification 8;
BA_ "SPN" SG_ 2566839038 SoftwareIdentification 234;
BA_ "SigType" SG_ 2566768126 DateOfManufacture 8;
BA_ "SPN" SG_ 2566768126 DateOfManufacture 11746;
BA_ "SigType" SG_ 2566768126 ECUHardwareID 8;
BA_ "SPN" SG_ 2566768126 ECUHardwareID 6714;
BA_ "SigType" SG_ 2566768126 ECULocation 8;
BA_ "SPN" SG_ 2566768126 ECULocation 2903;
BA_ "SigType" SG_ 2566768126 ECUManufacturerName 8;
BA_ "SPN" SG_ 2566768126 ECUManufacturerName 4304;
BA_ "SigType" SG_ 2566768126 ECUPartNumber 8;
BA_ "SPN" SG_ 2566768126 ECUPartNumber 2901;
BA_ "SigType" SG_ 2566768126 ECUSerialNumber 8;
BA_ "SPN" SG_ 2566768126 ECUSerialNumber 2902;
BA_ "SigType" SG_ 2566768126 ECUType 8;
BA_ "SPN" SG_ 2566768126 ECUType 2904;
BA_ "SPN" SG_ 2566742270 FailureModeIdentifier1 1215;
BA_ "SigType" SG_ 2566742270 FailureSpecificB1Counter 1;
BA_ "SPN" SG_ 2566742270 FailureSpecificB1Counter 4147;
BA_ "SPN" SG_ 2566742270 SPN1 1214;
BA_ "SigType" SG_ 2566742526 SysCumulativeContinuousMITime 1;
BA_ "SPN" SG_ 2566742526 SysCumulativeContinuousMITime 4145;
BA_ "SigType" SG_ 2566742526 SysGreatestB1Counter 1;
BA_ "SPN" SG_ 2566742526 SysGreatestB1Counter 4146;
BA_ "SigType" SG_ 2566742782 RegulationDescription 8;
BA_ "SPN" SG_ 2566742782 RegulationDescription 4144;
BA_ "SigType" SG_ 2566743038 SysContinuousMalfunctionInd 4;
BA_ "SPN" SG_ 2566743038 SysContinuousMalfunctionInd 4140;
BA_ "SigType" SG_ 2566743038 SysIncompleteMonitorCount 1;
BA_ "SPN" SG_ 2566743038 SysIncompleteMonitorCount 4143;
BA_ "SPN" SG_ 2566743038 SysMalIndActivationMode 4142;
BA_ "SigType" SG_ 2566743038 SysMalIndDisplayStrategy 4;
BA_ "SPN" SG_ 2566743038 SysMalIndDisplayStrategy 4141;
BA_ "SigType" SG_ 2566743038 SysNonRoadworthyCompCount 1;
BA_ "SPN" SG_ 2566743038 SysNonRoadworthyCompCount 4139;
BA_ "SigType" SG_ 2566743294 VehicleContinuousMalfunctionInd 4;
BA_ "SPN" SG_ 2566743294 VehicleContinuousMalfunctionInd 4134;
BA_ "SigType" SG_ 2566743294 VehicleCurrentMIAccumTime 1;
BA_ "SPN" SG_ 2566743294 VehicleCurrentMIAccumTime 4138;
BA_ "SigType" SG_ 2566743294 VehicleIncompleteMonitorCount 1;
BA_ "SPN" SG_ 2566743294 VehicleIncompleteMonitorCount 4137;
BA_ "SigType" SG_ 2566743294 VehicleMalfunctionIndActMode 4;
BA_ "SPN" SG_ 2566743294 VehicleMalfunctionIndActMode 4136;
BA_ "SigType" SG_ 2566743294 VehicleMalfunctionIndStrategy 4;
BA_ "SPN" SG_ 2566743294 VehicleMalfunctionIndStrategy 4135;
BA_ "SigType" SG_ 2566743294 VehicleNonRoadworthyCompCount 1;
BA_ "SPN" SG_ 2566743294 VehicleNonRoadworthyCompCount 4133;
BA_ "SigType" SG_ 2560687870 MnfcNOxNTECarveOutAreaStatus 4;
BA_ "SPN" SG_ 2560687870 MnfcNOxNTECarveOutAreaStatus 4128;
BA_ "SigType" SG_ 2560687870 MnfcPMNTECarveOutAreaStatus 4;
BA_ "SPN" SG_ 2560687870 MnfcPMNTECarveOutAreaStatus 4131;
BA_ "SPN" SG_ 2560687870 NOxNTEControlAreaStatus 4127;
BA_ "SigType" SG_ 2560687870 NOxNTEDeficiencyAreaStatus 4;
BA_ "SPN" SG_ 2560687870 NOxNTEDeficiencyAreaStatus 4129;
BA_ "SPN" SG_ 2560687870 PMNTEControlAreaStatus 4130;
BA_ "SigType" SG_ 2560687870 PMNTEDeficiencyAreaStatus 4;
BA_ "SPN" SG_ 2560687870 PMNTEDeficiencyAreaStatus 4132;
BA_ "SigType" SG_ 2292317950 AECDEngineHours1Timer1 1;
BA_ "SPN" SG_ 2292317950 AECDEngineHours1Timer1 4125;
BA_ "SigType" SG_ 2292317950 AECDEngineHours1Timer2 1;
BA_ "SPN" SG_ 2292317950 AECDEngineHours1Timer2 4126;
BA_ "SigType" SG_ 2292317950 AECDNumber1 1;
BA_ "SPN" SG_ 2292317950 AECDNumber1 4124;
BA_ "SigType" SG_ 2560884478 DTC1 7;
BA_ "SPN" SG_ 2560884478 DTCMilSupportFlash 4117;
BA_ "SPN" SG_ 2560884478 DTCMilSupportStatus 4113;
BA_ "SigType" SG_ 2560884478 DTCProtectLampSupportFlash 4;
BA_ "SPN" SG_ 2560884478 DTCProtectLampSupportFlash 4120;
BA_ "SigType" SG_ 2560884478 DTCProtectLampSupportStatus 4;
BA_ "SPN" SG_ 2560884478 DTCProtectLampSupportStatus 4116;
BA_ "SigType" SG_ 2560884478 DTCStopLampSupportFlash 4;
BA_ "SPN" SG_ 2560884478 DTCStopLampSupportFlash 4118;
BA_ "SigType" SG_ 2560884478 DTCStopLampSupportStatus 4;
BA_ "SPN" SG_ 2560884478 DTCStopLampSupportStatus 4114;
BA_ "SigType" SG_ 2560884478 DTCWarnLampSupportFlash 4;
BA_ "SPN" SG_ 2560884478 DTCWarnLampSupportFlash 4119;
BA_ "SigType" SG_ 2560884478 DTCWarnLampSupportStatus 4;
BA_ "SPN" SG_ 2560884478 DTCWarnLampSupportStatus 4115;
BA_ "SPN" SG_ 2560950014 FailureModeIdentifier1 1215;
BA_ "SigType" SG_ 2560950014 SlotId 1;
BA_ "SPN" SG_ 2560950014 SlotId 4109;
BA_ "SPN" SG_ 2560950014 SPN1 1214;
BA_ "SigType" SG_ 2560950014 TestLimitMaximum 1;
BA_ "SPN" SG_ 2560950014 TestLimitMaximum 4111;
BA_ "SigType" SG_ 2560950014 TestLimitMinimum 1;
BA_ "SPN" SG_ 2560950014 TestLimitMinimum 4112;
BA_ "SigType" SG_ 2560950014 TestValue 1;
BA_ "SPN" SG_ 2560950014 TestValue 4110;
BA_ "SPN" SG_ 2566836478 TestIdentifier 1224;
BA_ "SigType" SG_ 2566836478 TestLimitMaximum 1;
BA_ "SPN" SG_ 2566836478 TestLimitMaximum 1227;
BA_ "SigType" SG_ 2566836478 TestLimitMinimum 1;
BA_ "SPN" SG_ 2566836478 TestLimitMinimum 1228;
BA_ "SigType" SG_ 2566836478 TestType 1;
BA_ "SPN" SG_ 2566836478 TestType 1225;
BA_ "SigType" SG_ 2566836478 TestValue 1;
BA_ "SPN" SG_ 2566836478 TestValue 1226;
BA_ "SPN" SG_ 2565078782 FailureModeIdentifier1 4149;
BA_ "SPN" SG_ 2565078782 SPN1 4148;
BA_ "SPN" SG_ 2565078782 TestIdentifier 1224;
BA_ "SigType" SG_ 2566836222 AmberWarningLampStatus 5;
BA_ "SPN" SG_ 2566836222 AmberWarningLampStatus 624;
BA_ "SigType" SG_ 2566836222 DTC1 7;
BA_ "SigType" SG_ 2566836222 DTC2 7;
BA_ "SigType" SG_ 2566836222 DTC3 7;
BA_ "SigType" SG_ 2566836222 DTC4 7;
BA_ "SigType" SG_ 2566836222 DTC5 7;
BA_ "SigType" SG_ 2566836222 FlashAmberWarningLamp 5;
BA_ "SPN" SG_ 2566836222 FlashAmberWarningLamp 3040;
BA_ "SigType" SG_ 2566836222 FlashMalfuncIndicatorLamp 5;
BA_ "SPN" SG_ 2566836222 FlashMalfuncIndicatorLamp 3038;
BA_ "SigType" SG_ 2566836222 FlashProtectLamp 5;
BA_ "SPN" SG_ 2566836222 FlashProtectLamp 3041;
BA_ "SigType" SG_ 2566836222 FlashRedStopLamp 5;
BA_ "SPN" SG_ 2566836222 FlashRedStopLamp 3039;
BA_ "SigType" SG_ 2566836222 MalfunctionIndicatorLampStatus 5;
BA_ "SPN" SG_ 2566836222 MalfunctionIndicatorLampStatus 1213;
BA_ "SigType" SG_ 2566836222 ProtectLampStatus 5;
BA_ "SPN" SG_ 2566836222 ProtectLampStatus 987;
BA_ "SigType" SG_ 2566836222 RedStopLampState 4;
BA_ "SPN" SG_ 2566836222 RedStopLampState 623;
BA_ "SigType" SG_ 2566835966 ActiveTroubleCodes 1;
BA_ "SPN" SG_ 2566835966 ActiveTroubleCodes 1218;
BA_ "SigType" SG_ 2566835966 OBDCompliance 1;
BA_ "SPN" SG_ 2566835966 OBDCompliance 1220;
BA_ "SigType" SG_ 2566835966 PreviouslyActiveTroubleCodes 1;
BA_ "SPN" SG_ 2566835966 PreviouslyActiveTroubleCodes 1219;
BA_ "SigType" SG_ 2566835710 DTC1 7;
BA_ "SigType" SG_ 2566835710 EngCoolantTemp 1;
BA_ "SPN" SG_ 2566835710 EngCoolantTemp 110;
BA_ "SigType" SG_ 2566835710 EngIntakeManifold1Press 1;
BA_ "SPN" SG_ 2566835710 EngIntakeManifold1Press 102;
BA_ "SigType" SG_ 2566835710 EngPercentLoadAtCurrentSpeed 1;
BA_ "SPN" SG_ 2566835710 EngPercentLoadAtCurrentSpeed 92;
BA_ "SigType" SG_ 2566835710 EngSpeed 1;
BA_ "SPN" SG_ 2566835710 EngSpeed 190;
BA_ "SPN" SG_ 2566835710 EngTorqueMode 899;
BA_ "SPN" SG_ 2566835710 FreezeFrameLength 1217;
BA_ "SigType" SG_ 2566835710 WheelBasedVehicleSpeed 1;
BA_ "SPN" SG_ 2566835710 WheelBasedVehicleSpeed 84;
BA_ "SigType" SG_ 2566764542 DTC1 7;
BA_ "SigType" SG_ 2566764542 ExpandedFreezeFrameLength 1;
BA_ "SPN" SG_ 2566764542 ExpandedFreezeFrameLength 3300;
BA_ "SigType" SG_ 2566764286 SPNDataLength1 1;
BA_ "SPN" SG_ 2566764286 SPNDataLength1 4103;
BA_ "SigType" SG_ 2566764286 SPNDataLength2 1;
BA_ "SigType" SG_ 2566764286 SPNDataLength3 1;
BA_ "SPN" SG_ 2566764286 SPNSupported1 3297;
BA_ "SPN" SG_ 2566764286 SPNSupportTypeDS1 4101;
BA_ "SPN" SG_ 2566764286 SPNSupportTypeEFF1 4100;
BA_ "SPN" SG_ 2566764286 SPNSupportTypeSTR1 4102;
BA_ "SigType" SG_ 2566764030 AmberWarningLampStatus 5;
BA_ "SPN" SG_ 2566764030 AmberWarningLampStatus 624;
BA_ "SigType" SG_ 2566764030 DTC1 7;
BA_ "SigType" SG_ 2566764030 DTC2 7;
BA_ "SigType" SG_ 2566764030 DTC3 7;
BA_ "SigType" SG_ 2566764030 DTC4 7;
BA_ "SigType" SG_ 2566764030 DTC5 7;
BA_ "SigType" SG_ 2566764030 FlashAmberWarningLamp 5;
BA_ "SPN" SG_ 2566764030 FlashAmberWarningLamp 3040;
BA_ "SigType" SG_ 2566764030 FlashMalfuncIndicatorLamp 5;
BA_ "SPN" SG_ 2566764030 FlashMalfuncIndicatorLamp 3038;
BA_ "SigType" SG_ 2566764030 FlashProtectLamp 5;
BA_ "SPN" SG_ 2566764030 FlashProtectLamp 3041;
BA_ "SigType" SG_ 2566764030 FlashRedStopLamp 5;
BA_ "SPN" SG_ 2566764030 FlashRedStopLamp 3039;
BA_ "SigType" SG_ 2566764030 MalfunctionIndicatorLampStatus 5;
BA_ "SPN" SG_ 2566764030 MalfunctionIndicatorLampStatus 1213;
BA_ "SigType" SG_ 2566764030 ProtectLampStatus 5;
BA_ "SPN" SG_ 2566764030 ProtectLampStatus 987;
BA_ "SigType" SG_ 2566764030 RedStopLampState 4;
BA_ "SPN" SG_ 2566764030 RedStopLampState 623;
VAL_ 2565799678 VehicleSystem5 127 "Not Available" 0 "Ind. Process Control Stationary" ;
VAL_ 2565799678 VehicleSystem4 125 "Entertainment" 120 "Display" 85 "External Environment" 75 "Sensor Communication Interface" 35 "Electrical Generation" 100 "Deck, Cargo and Fishing Equipment" 90 "Internal Environment" 80 "Instrumentation/General Systems (deprecate)" 70 "Communications" 60 "Navigation" 50 "Propulsion" 40 "Steering and Control Surfaces" 30 "Electrical Distribution" 25 "Inter/Intranetwork Device" 20 "Safety Systems" 10 "System Tools" 127 "Not Available" 0 "Non-specific System" ;
VAL_ 2565799678 VehicleSystem3 8 "Grader" 7 "Four Wheel Drive Loader" 6 "Forklift" 5 "Excavator" 4 "Crawler" 3 "Backhoe" 2 "Articulated Dump Truck" 1 "Skid Steer Loader" 127 "Not Available" 0 "Non-specific System" ;
VAL_ 2565799678 VehicleSystem2 25 "Slurry Applicators" 24 "Utility Vehicles" 23 "Mulchers" 22 "Timber Processing Machines" 21 "Timber loaders" 20 "Forwarders" 19 "Timber Harvesters" 17 "Sensor Systems" 16 "Skidder" 15 "Earth Work" 14 "Special Crops" 13 "Powered Auxiliary Device" 12 "Farm Yard Operations" 11 "Transport/Trailer" 10 "Irrigation" 9 "Forage" 8 "Root Harvesters" 7 "Harvesters" 6 "Sprayers" 5 "Fertilizers" 4 "Planters/Seeders" 3 "Secondary Tillage" 2 "Tillage" 1 "Tractor" 127 "Not Available" 0 "Non-specific System" ;
VAL_ 2565799678 VehicleSystem1 2 "Trailer" 1 "Tractor" 127 "Not Available" 0 "Non-specific System" ;
VAL_ 2565799678 VehicleSystem 0 "Non-specific System" 127 "Not Available" ;
VAL_ 2565799678 IndustryGroup 6 "Reserved for SAE" 7 "Reserved for SAE" 5 "IndustrialProcessCtrlStationary" 4 "Marine" 3 "Construction" 2 "Agricultural and Forestry" 1 "On-Highway" 0 "Global" ;
VAL_ 2565799678 Function 127 "Reserved" 126 "Reserved" 125 "Reserved" 124 "Reserved" 123 "Reserved" 122 "Reserved" 121 "Reserved" 120 "Reserved" 119 "Reserved" 118 "Reserved" 117 "Reserved" 116 "Reserved" 115 "Reserved" 114 "Reserved" 113 "Reserved" 112 "Reserved" 111 "Reserved" 110 "Reserved" 109 "Reserved" 108 "Reserved" 107 "Reserved" 106 "Reserved" 105 "Reserved" 104 "Reserved" 103 "Reserved" 102 "Reserved" 101 "Reserved" 42 "Water Pump Control" 41 "Lighting - Operator Controls" 40 "Seat Control" 39 "Ignition Control Module" 38 "Tire Pressure Control" 37 "Cab Controller" 36 "Pneumatic - System Controller" 35 "Suspension - System Controller" 34 "Hydraulic Pump Controller" 33 "System Monitor" 32 "Headway Controller" 31 "Propulsion Battery Charger" 30 "Management Computer" 29 "Virtual Terminal (in cab)" 28 "Off Vehicle Gateway" 27 "Power TakeOff (Secondary or Front)" 26 "Body Controller" 25 "Network Interconnect ECU" 24 "Vehicle Security" 23 "Vehicle Navigation" 22 "Aerodynamic Control" 21 "Cab Climate Control" 20 "Trip Recorder" 19 "Instrument Cluster" 18 "Suspension - Drive Axle" 17 "Suspension - Steer Axle" 16 "Steering Controller" 15 "Fuel System" 14 "Cruise Control" 13 "Retarder - Driveline" 12 "Retarder - Engine" 11 "Brakes - Drive Axle" 10 "Brakes - Steer Axle" 9 "Brakes - System Controller" 8 "Axle - Drive" 7 "Axle - Steering" 6 "Power TakeOff - (Main or Rear)" 5 "Shift Control/Console" 4 "Battery Pack Monitor" 3 "Transmission" 2 "Electric Propulsion Control" 1 "Auxiliary Power Unit (APU)" 0 "Engine" 100 "Reserved" 99 "Reserved" 98 "Reserved" 97 "Reserved" 96 "Reserved" 95 "Reserved" 94 "Reserved" 93 "Reserved" 92 "Reserved" 91 "Reserved" 90 "Reserved" 89 "Reserved" 88 "Reserved" 87 "Reserved" 86 "Reserved" 85 "Reserved" 84 "Reserved" 83 "Reserved" 82 "Reserved" 81 "Reserved" 80 "Reserved" 79 "Reserved" 78 "Fire Suppression System" 77 "Fuel Properties Sensor" 76 "Temperature Sensor" 75 "Supplemental Fan" 74 "Lubrication System" 73 "Rollover Detection Control" 72 "Coolant Valve Controller" 71 "Transfer Case Control" 70 "Auxiliary Regeneration Device" 69 "Engine Emission Aftertreatement System" 68 "Aftertreatment system gas measurement" 67 "Electrical System Controller" 66 "I/O Controller" 65 "Gas Flow Measurement" 64 "Endurance Braking" 63 "Engine Valve Controller" 62 "On-Board Diagnostic Unit" 61 "File Server/Printer" 60 "Cab Display" 59 "Starter" 58 "Fan Drive Control" 57 "Steering Column Unit" 56 "Communications Unit, Radio" 55 "Communications Unit, Satellite" 54 "Communications Unit, Cellular" 53 "Alternator/Charging System" 52 "Chassis Controller" 51 "Forward-Looking Collision Warning System" 50 "Auxiliary Heater" 49 "Clutch/Converter Control" 48 "Ramp Control" 47 "Information System Controller" 46 "Oil Sensor Unit" 45 "Vehicle Dynamic Stability Control" 44 "Exhaust Emission Control" 43 "Transmission Display" ;
VAL_ 2565799678 ManufacturerCode 1863 "Thomas G. Faria Co." 1862 "Sanshin" 1861 "Vector North America (formerly Vector Cantech)" 1860 "MMP" 1859 "Kvasar AB" 1858 "Litton" 1857 "Simrad" 1856 "Trimble" 1855 "Furuno USA" 1854 "Northstar Technologies" 1853 "Japan Radio Co" 1852 "Navionics" 1851 "RayMarine" 1850 "Seastar Solutions (formerly Teleflex)" 1569 "621 Technologies Inc." 1164 "SEG Automotive" 1163 "DFX Technologies LLC" 1162 "PEL-tuote Oy" 1161 "Griessbach GmbH" 1160 "MG Energy Systems B.V." 1159 "Bel Power Solutions" 1158 "Technoton Electronics" 1157 "Carriergistics" 1156 "Nokian Tyres" 1155 "LACOS Computerservice GmbH" 1154 "TBS Electronics BV" 1153 "Kawasaki Heavy Industries, Ltd." 1152 "Vredo Dodewaard B.V." 1151 "Orca Technologies AS" 1150 "BSB Artificial Intelligence GmbH" 1149 "Wuxi Shengbang Electronics Co., Ltd" 1148 "Stercom Power Solutions GmbH" 1147 "Dana Inc." 1146 "Rometron" 1145 "Kiwi Yachting" 1144 "Troo Corporation" 1143 "Elektro-Szoft 2000" 1142 "Truma" 1141 "MRS Electronic GmbH & Co. KG" 1140 "Across Oceans Systems Ltd." 1139 "ASP Technology" 1138 "Micro-Sensor GmbH" 1137 "SIKO GmbH" 1136 "Primosensor GmbH" 1135 "Japan Aviation Electronics Industry, Limited" 1134 "Master Schools at Ostbahnhof" 1133 "MEGATRON Elektronik GmbH & Co. KG" 1132 "Tokachi Zaidan" 1131 "Guliwer electronics s.r.o." 1130 "Vitesco Technologies" 1129 "Spectrolytic GmbH" 1128 "Citoon Electronic Technology (Tianjin) Co., Ltd." 1127 "ElectroMaax" 1126 "Auralix" 1125 "Griffith-Elder & Co. Ltd." 1124 "Fortron Agriculture" 1123 "QP Hydraulics" 907 "strautmann" 906 "MOBA AG" 905 "ASA Electronics" 904 "Equipment Safety Systems Pty. Ltd. (EQSS)" 903 "InMotion" 902 "Bucher Hydraulics" 901 "Zivan Srl" 900 "OSB AG" 899 "Lippert Components, Inc" 898 "Josef Kotte Landtechnik GmbH & Co. KG" 897 "Dot Technology Corp." 896 "NextFour Solutions Ltd" 895 "Peloton Technology" 894 "Rhodan Marine Systems of Florida LLC" 893 "KlinkTechnics Ltd." 892 "Mectronx Corp" 891 "CarrierWeb" 890 "L3 Technologies, Inc." 889 "SANY America Inc" 888 "Carma Systems Inc" 887 "Hyperdrive Innovation Limited" 886 "Hitachi Zosen Corporation" 885 "SICK Stegmann GmbH" 884 "Sure Grip Controls Inc." 883 "Swift Navigation, Inc." 882 "BHTronik GmbH & Co. KG" 881 "Sovema" 880 "Revision Military" 879 "PG Trionic, Inc." 878 "FOTON" 877 "SICK ATech GmbH" 876 "SUCO Robert Scheuffele GmbH & Co. KG" 875 "Salvarani S.r.l." 874 "MTA S.p.A." 873 "Garnet Instruments Ltd." 872 "Kählig Antriebstechnik GmbH" 871 "Superior Tech Inc" 870 "Textron Fleet Management" 869 "Intercomp" 868 "Data Panel Corp" 867 "Skeleton Technologies" 866 "Netradyne, Inc." 865 "MyEasyFarm" 864 "Streamline Transportation Technologies Inc." 863 "SMAG" 862 "Prospec Electronics" 861 "Adel System S.r.l." 860 "Michelin" 859 "Valor" 858 "Littelfuse" 857 "Zoomlion Heavy Industry NA, Inc" 856 "FarmFacts GmbH" 855 "Toshiba Infrastructure Systems & Solutions Corporation" 1122 "GT Inc." 1121 "Platform Science" 1120 "Elettromedia s.r.l." 1119 "Balmar LLC" 1118 "L3Harris ASV" 1117 "LG Chem, Ltd" 1116 "HR Agrartechnik GmbH" 1115 "Gems Sensors & Controls" 1114 "Bob's Machine" 1113 "iVolve Pty Ltd" 1112 "Bollinger Motors" 1111 "SEPPI M." 1110 "Analytic Systems Ware (1993) Ltd." 1109 "Dockmate" 1108 "ORBCOMM" 1107 "Dräger Safety" 1106 "Great Dane LLC" 1105 "Redekop Manufacturing" 1104 "The Toro Company" 1103 "Diesel Laptops" 1102 "Carl Geringhoff GmbH & Co. KG" 1101 "DIS Sensors B.V." 1100 "Smart Yachts International Limited" 1099 "MadgeTech, Inc" 1098 "Preh GmbH" 1097 "M2M Craft Co., Ltd" 1096 "Texense Sensors" 1095 "WEG Drives and Controls - Automação Ltda" 1094 "Tokushu Denki" 1093 "innolectric" 1092 "Scheiber" 1091 "Wheel Monitor Inc." 1090 "E-T-A Circuit Breakers Ltd" 1089 "Carrosserie HESS AG" 1088 "E-T-A Circuit Breakers" 1087 "ITPhotonics S.r.l." 1086 "Life Racing Ltd" 1085 "Wet Sounds, LLC" 1084 "Shadow-Caster LED lighting LLC" 1083 "Nauticoncept" 1082 "TÜMOSAN Engine and Tractor Co." 1081 "Imcon Electronics, s.r.o." 1080 "Epsilor-Electric Fuel Ltd." 1079 "Carl Zeiss Spectroscopy GmbH" 1078 "GE Appliances" 1077 "Ymer Technology" 1076 "DOGA S.A." 1075 "Uniden America Corporation" 1074 "Kindhelm / Navigs Oy" 1073 "Manitou Equipment America LLC" 1072 "La Marche Manufacturing Company" 1071 "MACH SYSTEMS s.r.o." 1070 "Quick-teck Electronics Ltd" 1069 "Lithionics Battery LLC" 1068 "Zapi S.p.A." 1067 "Tecomec S.r.l." 1066 "Spot Zero Water" 1065 "CALYPSO Instruments" 1064 "Omnitech Robotics Inc." 1063 "SolSteer" 1062 "Marol Co Ltd" 1061 "Volvo Construction Equipment" 1060 "Scale-Tec" 1059 "Boatrax" 1058 "Bondioli & Pavesi SpA" 1057 "EquipmentShare" 1056 "Lithium Pros" 1055 "EXA Computing GmbH" 1054 "Schmotzer Hacktechnik GmbH & Co. KG" 1053 "Vetus Maxwell, Inc." 1052 "Pfreundt" 1051 "ProNav AS" 1050 "Spacenus GmbH" 1049 "S&S Cycle" 1048 "Agrivation UG" 1047 "Sonic Corporation" 1046 "Praxidyn" 1045 "CMR Group" 1044 "Xee" 1043 "Hyva" 1042 "engcon group" 1041 "EZ Lynk" 1040 "BPE Electronics Srl" 1039 "Liugong Dressta Machinery" 1038 "EMIT Technologies, Inc." 1037 "Dragonfly Energy Corp." 1036 "Bender GmbH & Co. KG" 1035 "Agres" 1034 "Siren Marine" 1033 "ECCO Safety Group" 1032 "SIMOL S.p.A." 1031 "Flintec UK Ltd." 1030 "Tume-Agri Oy" 1029 "The Marine Guardian LLC" 1028 "Autel Intelligent Technology Corp., Ltd" 1027 "Goldacres PTY LTD" 1026 "ZTR Control Systems, LLC" 1025 "eze System, Inc." 1024 "Inventus Power" 1023 "PEAK-System Technik GmbH" 1022 "ITC Inc" 1021 "Entratech Systems LLC" 1020 "Onyx Marine Automation s.r.l." 1019 "Codek Foundries" 1018 "Flex TTS" 1017 "Caldaro AB" 1016 "Röhren- und Pumpenwerk BAUER GmbH" 1015 "SECURITAG SAS" 1014 "Briri Maschinenbau GmbH" 1013 "Allochis E-Tec" 1012 "Rhodan Marine Systems of Florida LLC" 1011 "Soundmax Electronics Ltd" 1010 "Agricultural Industry Electronics Foundation e.V." 1009 "TouchTronics, Inc." 1008 "Lintest Systems LLC" 1007 "Maschinenfabrik Meyer-Lohne GmbH" 1006 "Proterra" 1005 "TSE Brakes, Inc." 1004 "Ultraflex SpA" 1003 "technotrans SE" 1002 "Kussmaul Electronics Co." 1001 "Cleral Inc." 1000 "Landmaschinen Wienhoff GmbH" 999 "TerraTroniq B.V." 998 "Transcell Technology Inc" 997 "Xenta Systems Srl" 996 "Eniquest Pty Ltd" 995 "Circuitlink Pty Ltd." 994 "Morris Industries Ltd." 993 "Alelion Energy Systems AB" 992 "MarineIOT LLC" 991 "Deutronic Elektronik GmbH" 990 "SAMSUNG SDI Co., Ltd." 989 "Flux-Geräte GmbH" 988 "Voith Turbo" 987 "Baltic Car Equipment" 986 "AAMP Global" 985 "NLR, LLC" 984 "E-T-A Elektrotechnische Apparate GmbH" 983 "Dezwaef NV" 982 "Briggs & Stratton Corporation" 981 "Kobelt Manufacturing Co. Ltd" 980 "Gussi Italia S.R.L." 979 "McHale" 978 "Canfield Connector" 977 "Emerson Electric Co." 976 "Derive Systems, Inc." 975 "Siemens AG" 974 "Pico Technology Limited" 973 "Zasso GmbH" 972 "Axion AG" 971 "B+B Smartworx" 970 "Jaboni Power Products, LLC" 969 "Blue Sea Systems" 968 "Cox Powertrain Limited" 967 "Moteck Electric Corp." 966 "VisibleFarm" 965 "Ro-Sys Software" 964 "AgroVIR Kft" 963 "Thomason Jones Company, LLC" 962 "Timbolier Industries, Inc." 961 "POK SAS" 960 "Vemcon GmbH" 959 "Cascade Corporation" 958 "NHK MEC Corporation" 957 "Sierra Wireless Inc" 956 "Piher Sensors & Controls S.A." 955 "Hottinger Baldwin (Suzhou) Electronic Measurement Technology Co., Ltd." 954 "Setec Pty Ltd" 953 "Curtiss-Wright" 952 "Tan Delta Systems Ltd" 951 "Exor International S.p.A." 950 "RE:Lab s.r.l." 949 "Škoda Electric a.s." 948 "Donix" 947 "Gerd Bär GmbH" 946 "Hydac Tecnologia Ltda" 945 "Equalizer AG" 944 "ZONTISA Marine SL" 943 "FISCHER AG Präzisionspindeln" 942 "Vogelsang GmbH & Co. KG" 941 "Navya" 940 "Dometal Oy" 939 "Warn Industries, Inc." 938 "LEVEL Systems" 937 "Precision Circuits Inc" 936 "Hi-tech Millennium" 935 "Meels GmbH & Co. KG" 934 "Farmobile, Inc." 933 "Delta Mobile Systems, Inc." 932 "Discover Battery" 931 "Enertec Marine Ltd" 930 "Ecotronix Corp." 929 "Jl Marine Systems, Inc." 928 "EAO Automotive GmbH & Co. KG" 927 "Saicon" 926 "Buhler Industries Inc." 925 "GW Lisk Company" 924 "PAS Peschak Autonome Systeme GmbH" 923 "ELTEK S.p.A." 922 "Terberg Benschop B.V." 921 "ROPA Fahrzeug- und Maschinenbau GmbH" 920 "MTD Consumer Group Inc." 919 "Furrion LLC" 918 "AMW Machine Control, Inc" 917 "Sentinel d.o.o." 916 "Turck Inc." 915 "Dosificacion y sistemas electronicos S.L. (DSE)" 914 "ZETOR TRACTORS a.s." 913 "Toyota Motor Corporation" 912 "Steyr Motors GmbH" 911 "Nautic-On" 910 "Hermann Paus Maschinenfabrik GmbH" 909 "Marines Co., Ltd." 908 "Chonbuk National University Department of Electronics" 854 "GEMAC Chemnitz GmbH" 853 "Teledyne RESON B.V." 852 "Velvac Inc" 851 "Novotechnik Messwertaufnehmer OHG" 850 "Geoprospectors GmbH" 849 "MTS Maschinentechnik Schrode AG" 848 "ningupex" 847 "Oceanvolt" 846 "L3 Magnet-Motor" 845 "GMB Güstrower Maschinenbau GmbH" 844 "FELL AS" 843 "Hendrickson Truck Commercial Vehicle Systems" 842 "DigiDevice Srl" 841 "Agra-GPS" 840 "E.S.T.E. Srl" 839 "Indexator Rotator Systems AB" 838 "Teamsurv Ltd" 837 "Famic Technologies Inc." 836 "Signature4" 835 "PetTrack Ltd." 834 "Pioneer Microsystems, Inc." 833 "Electrum Automation AB" 832 "Heizomat Gerätebau-Energiesysteme GmbH" 831 "DOK-ING Ltd." 830 "Ultra Motion LLC" 829 "Drov Technologies, Inc." 828 "AgriBrink Inc." 827 "INmatix Technology Group Ltd" 826 "Lewmar Marine Inc" 825 "BPW Hungária" 824 "Undheim Systems AS" 823 "ACEINNA, Inc (formerly MEMSIC, Inc)" 822 "Bren-Tronics, Inc." 821 "Thorsen Teknik A/S" 820 "DIaLOGIKa Gesellschaft fuer angewandte Informatik mbH" 819 "Preco Electronics" 818 "HGNSS" 817 "TE Connectivity Sensor Solutions" 816 "UniStrong" 815 "FLIR Systems, Inc." 814 "Kronotech Srl (formerly Soltec Soluzioni Tecnologiche Srl)" 813 "Thales Suisse SA" 812 "Torch Technologies" 811 "Blue Water Desalination" 810 "Dutch Power Company" 809 "HMS Industrial Networks AB" 808 "RIMEX Supply Ltd." 807 "Schneider-Electric" 806 "Charge Automotive Ltd" 805 "Gundersen & Løken AS" 804 "ASA Electronics" 803 "Gill Sensors & Controls Limited" 802 "SPBI (Bj Technologie)" 801 "LOR Manufacturing Company Inc." 800 "Delta-Q Technologies" 799 "Stillwater Designs and Audio, Inc. - KICKER" 798 "Lumishore Ltd" 797 "Tides Marine" 796 "Canadian Automotive Industries Ltd" 795 "Broyda Enterprises Pty Ltd" 794 "Shihlin Electric & Engineering Corporation" 793 "James Fisher Prolec" 792 "Kostal Mexicana" 791 "AUTEC" 790 "VACALL" 789 "GRADALL" 788 "MoTeC Pty Ltd" 787 "Abertax Technologies Limited" 786 "Johnson Matthey Battery Systems" 785 "Fischer Panda GmbH" 784 "CM Automotive Systems, Inc." 783 "Loup Electronics Inc." 782 "AVR bv (formerly AVR bvba)" 781 "Poly-Planar LLC" 780 "AVID Technology Ltd" 779 "RLC Electronic Systems" 778 "Seakeeper Inc." 777 "Ocean Signal Ltd" 776 "HMI Systems LLC" 775 "ZIEHL-ABEGG Automotive GmbH" 774 "Taisho Corporation" 773 "Clarion Corporation of America" 772 "Blink Marine" 771 "Shaw Development, LLC" 770 "MONOSEM" 769 "Trombetta" 768 "Flores Automation, LLC" 767 "Alliance Wireless Technologies Inc." 766 "Epec Oy" 765 "GIGAVAC" 764 "Bednar FMT s.r.o." 763 "AT-Systems BVBA" 762 "ROJ s.r.l." 761 "MITA OLEODINAMICA S.p.A." 760 "Bernecker + Rainer Industrie Elektronik GmbH" 759 "Hydro-Gear" 758 "Banner Engineering Corp." 757 "IMPCO Technologies" 756 "Maschio Gaspardo S.P.A." 755 "Firefly Integrations" 754 "Parker Hannifin Corp., Automation Group" 753 "AIROD Technologies" 752 "Deep Sea Electronics Plc" 751 "Pacific Track" 750 "Joskin SA" 749 "Chart Inc." 748 "IFRA SRL - ISOTTA" 747 "Agratronix" 746 "SureFire Ag Systems, Inc." 745 "Cidra Corporate Services Inc." 744 "Woosung Engineering Co., Ltd." 743 "Daemyung Elevator Co., Ltd." 742 "EROAD" 741 "Carling Technologies" 740 "e-Traction" 739 "LXNAV d.o.o." 738 "Blue Ink Technologies" 737 "Balluff GmbH" 736 "Terex Aerial Work Platforms - Genie" 735 "AEM Performance Electronics" 734 "REAPsystems" 733 "Geotab Inc. (formerly Intendia S.L.)" 732 "Gefran S.p.A." 731 "Modine Manufacturing Company" 730 "BERTHOUD AGRICOLE" 729 "Liebherr" 728 "Streumaster (formerly Streumaster / Panien)" 727 "Dhoot Transmission Pvt Ltd." 726 "MIDORI PRECISIONS" 725 "Hitachi Construction Machinery Co., Ltd." 724 "Electronic Applications, Inc." 723 "Jabil Inc." 722 "Contelec AG" 721 "Hypro" 720 "WITZ Corporation" 719 "Cojali S. L." 718 "Micronet Inc" 717 "Yacht Devices Ltd" 716 "Eaton Control & Power Conversion Division (CPCD)" 715 "Autonnic Research Ltd" 714 "Kobashi Kogyo Co., Ltd." 713 "US Hybrid Corporation" 712 "LOR Manufacturing Company Inc." 711 "DAS Co., LTD" 710 "Greentronics Ltd." 709 "Marquardt GmbH" 708 "Lars Thrane A/S" 707 "Rochester Gauges Inc" 706 "Shanghai Diesel Engine Corporation Limited" 705 "SVAB Hydraulik AB" 704 "JL Audio, Inc." 703 "Hydro Tab Marine Engineering" 702 "Weichai Power Co., Ltd." 701 "BigRoad Inc." 653 "AEV, spol. s r. o." 652 "MicroControl GmbH & Co. KG" 651 "Takakita Co, Ltd." 650 "Seiko Epson Corp." 649 "Control-Q B.V." 648 "OJSC Ekran" 647 "Siloking" 646 "Veenhuis Machines B.V." 645 "esd electronic system design gmbh" 644 "KUS USA" 643 "Bogballe A/S" 642 "Moog / Aspen Motion Technologies" 641 "Diverse Yacht Services" 640 "Power Solutions International" 639 "Startec s.r.l." 638 "KVH Industries, Inc." 637 "Bavaria Yachtbau GmbH" 636 "Divelbiss Corporation" 635 "Argo Tractors S.p.A." 634 "Rocky Research" 633 "TORC Robotics" 632 "Pepperl+Fuchs GmbH" 631 "Reltima" 630 "SmartDrive Systems Inc." 629 "Agri Info Design, Ltd." 628 "Falck Schmidt Defence Systems" 627 "Radio Ocean" 626 "AVL DiTEST GmbH" 625 "Global MRV Inc." 624 "Blackbox Machine Control Pty Ltd" 623 "Xirgo Technologies" 622 "Floyd Bell Inc" 621 "Hagie Manufacturing Company" 620 "Sevcon Ltd." 619 "Right Weigh Load Scales" 618 "Evrard SA" 617 "Zero Emission Vehicles" 616 "SMART-TEC s.r.o." 615 "Networkfleet, Verizon Telematics" 614 "ARLT Technologies GmbH" 613 "HKS Co., Ltd." 612 "Samwon IT" 611 "Esterline" 610 "Trail Tech" 609 "Walvoil S.p.A." 608 "Gale Banks Engineering" 607 "Knappco/Civacon" 606 "Intellian Technologies" 605 "Aventics GmbH" 604 "Rototilt Group AB (formerly Indexator Rototilt Systems AB)" 603 "Kereval" 602 "Nomad Digital Ltd." 601 "Navitas Systems" 600 "Aquatic AV" 142 "TRW Automotive (Commercial Steering Systems)" 141 "Thales Navigation Ltd." 140 "Lowrance Electronics, Inc." 139 "Caterpillar Trimble Control Technologies (CTCT), LLC" 138 "Georg Fritzmeier GmbH & Co. KG" 137 "Maretron" 136 "Komatsu Ltd" 135 "Airmar Technology Corporation" 134 "Iris Technology Ltd" 133 "Bucher Schoerling GmbH" 132 "Mulag-Fahrzeugwerk" 131 "ITT Industries" 130 "Nido - Universal Machines B.V." 129 "OMNEX Control Systems Inc." 128 "Gerhard Duecker GmbH & Co. KG" 127 "Holland USA" 126 "Driver Tech" 125 "Nevada Automotive Test Center" 447 "Great Plains Mfg." 446 "CertTech, L.L.C." 445 "KAT MECHATRONIC, Electronic Product Division" 444 "ITT Power Solutions" 443 "SignalQuest, Inc." 442 "Horsch Maschinen GmbH" 441 "PTG Reifendruckregelsysteme GmbH" 440 "Cummins Power Generation" 439 "Hyundai Heavy Industries" 438 "Comar Systems Ltd" 437 "Digital Yacht Limited" 436 "Kinze Manufacturing" 435 "Zunhammer GmbH" 434 "Stored Energy Systems" 433 "Rowe Electronics" 432 "S&A Systems, Inc." 431 "Tohatsu Corporation" 430 "Auteq Telematica S.A." 429 "Rota Engineering Ltd." 425 "Methode Electronics Inc, MDI" 424 "Odyne LLC" 423 "BSM Wireless, Inc." 422 "True Heading AB" 421 "Vertex Standard Co, Ltd" 420 "Vermeer Corporation, ACS Group" 419 "Fusion Electronics Ltd" 418 "Intellistick Inc" 417 "KZValve" 416 "Kubota Corporation" 415 "Valid Manufacturing Ltd." 414 "Cattron Group International" 413 "Datapross Nijbroek bv" 412 "WebTech Wireless Inc." 411 "Hy-Drive Technologies Ltd." 410 "COBO S.p.A. Divisione 3B6" 409 "Transfluid S.r.L." 408 "Corvus Energy Ltd." 407 "Comtech Mobile Datacom" 406 "Vecima Networks Inc." 405 "Wema System AS" 404 "Com Nav Marine Ltd" 403 "Trackwell ADS, Inc." 402 "Simma Software, Inc." 401 "Torqeedo GmbH" 400 "Livorsi Marine" 399 "ISEKI & Co., Ltd." 398 "Hilite International" 397 "Sanyo-kiki Co Ltd." 396 "Beyond Measure" 395 "GENTEC S.R.L." 394 "Capi 2 Nederland B.V." 393 "Harvest Tec, Inc" 124 "Hydac Electronic" 123 "Basler Electric" 122 "FG Wilson (Engineering) Limited" 121 "HED (Hydro Electronic Devices, Inc.)" 120 "RDS Technology Ltd" 119 "IntegriNautics  " 118 "Intron GmbH" 117 "HUSCO International" 116 "BEELINE Technologies" 115 "NACCO Materials Handling Group, Inc." 114 "EControls, Inc." 113 "Stress-Tek, Inc." 112 "MECALAC" 111 "Bernard Krone Holding SE & Co. KG (formerly Maschinenfabrik Bernard Krone GmbH)" 110 "EPIQ Sensor-Nite" 109 "TeeJet Technologies Denmark (formerly LH Technologies ApS)" 108 "WTK-Elecktronik GmbH" 107 "Grimme Landmaschinen GmbH & Co. KG" 106 "BAE Systems Controls, Inc." 105 "Kiepe Elektrik GmbH & Co. KG" 104 "CLAAS KGaA mbH (formerly CLAAS Selbstfahrende Erntemaschinen GmbH)" 700 "K-Tec Earthmovers Inc." 699 "Harman International Industries" 698 "Scorpion Technologies Ltd." 697 "Ålö AB" 696 "DRS Network & Imaging Systems, LLC (DRS Technologies)" 695 "Weldon Technologies" 694 "GasTOPS Ltd." 693 "Agility Fuel Solutions (formerly Agility Fuel Systems)" 692 "Tanhay Corporation" 691 "Digitroll Agricultural Electronics" 690 "LINAK A/S" 689 "Aarcomm Systems Inc" 688 "Rockford Corp" 687 "Flight Systems, Inc." 686 "Taigene Electric Machinery Corp." 685 "ANEDO (formerly ANEDO Ltd.)" 684 "KEB" 683 "Fosen Elektro" 682 "Eckelmann AG" 681 "BEDIA Motorentechnik GmbH & Co. KG" 680 "AMVAC Chemical Corporation" 679 "OXE Marine AB (formerly Cimco Marine AB)" 678 "KeepTruckin, Inc." 677 "DSA Daten- und Systemtechnik GmbH" 676 "Danfoss IXA A/S" 675 "Kawasaki Motors Corp., USA" 674 "Yara International ASA" 673 "Caruelle Nicolas" 672 "OPTIMA Concept" 671 "Innovative Controls Inc." 670 "STEMCO LP" 669 "Quantum Fuel Systems Technologies Worldwide, Inc" 668 "MacDon Industries Ltd." 667 "Bartec" 666 "Schaeffler Technologies AG & Co., KG" 665 "Gebr. Bode GmbH & Co. KG" 664 "Level Developments Ltd" 663 "Delta Systems, Inc" 662 "Kissling Elektrotechnik GmbH" 661 "SPAL Automotive S.r.l." 660 "Auto-Gaz Centrum" 659 "Data Panel Corp." 658 "Shenzhen Jiuzhou Himunication Technology Co., Ltd" 657 "Terzo Power Systems" 656 "PRO SOLUS do Brasil" 655 "Genge & Thoma AG" 654 "Kohler Power Systems, Detroit Engine Development Center (DEDC)" 599 "Spudnik Equipment Co, LLC" 598 "ABB Turbo Systems Ltd" 597 "Hydac Filter Systems GmbH" 596 "Brunelco Electronic Innovators B.V." 595 "CustomWare" 594 "Kongsberg Automotive" 593 "Sensata Technologies" 592 "tecsis GmbH" 591 "United States Coast Guard" 590 "ARGO-HYTOS GMBH" 589 "MICO, Inc." 588 "Vignal Systems" 587 "JCA Electronics" 586 "Suzuki Motor Corp" 585 "Industrial Electronic Controls" 584 "CarMedialab GmbH" 583 "Yachtcontrol" 582 "Innovative Software Engineering" 581 "Väderstad - Verken AB" 580 "San Jose Technology, Inc." 579 "KVH Industries, Inc." 578 "advanSea" 577 "Denchi Power Ltd  (formerly ABSL Power Solutions Limited)" 576 "Vectia" 575 "Lytx" 574 "Vishay Precision Group" 573 "Orolia Ltd" 572 "Fasse Valves" 571 "Marinecraft Co., Ltd." 570 "frenzel + berg electronic GmbH & Co. KG" 569 "LORD MicroStrain Sensing Systems" 568 "Makersan Ltd. Co." 567 "Lithiumstart LLC" 566 "Geode Technology, Inc." 565 "Micro-Trak Systems, Inc." 564 "Auto Power Electronic" 563 "LOHR Sistemas Eletronicos LTDA" 562 "Bombardier Transportation GmbH" 561 "b-plus GmbH" 560 "Iowa State University, Agricultural and Biosystems Engineering" 559 "Four Peaks Navigation" 558 "Davis Instruments Corp." 557 "Rockson Automation GmbH" 556 "Doosan Infracore Norway" 555 "Sasaki Corporation" 554 "iris-GmbH infrared & intelligent sensors" 553 "KIB Electronics" 552 "Matsuyama Plow Mfg Co, Ltd" 551 "Wexler CSD Ltd." 550 "SUN-A Corporation" 549 "ROAD Deutschland GmbH" 548 "TM4 Inc." 547 "Thomson Linear LLC" 546 "Maruyama Mfg Co, Inc." 545 "GS Hydraulics" 544 "Au Group Electronics" 543 "BAUER Maschinen GmbH" 542 "Dinamica Generale s.p.a." 541 "Total Fire Systems, Inc." 540 "Dinex A/S" 539 "Mobileview" 538 "Crop Ventures, Inc." 537 "Schrader Electronics Ltd." 536 "SSI Technologies" 535 "MOTORPAL, a.s." 534 "Webasto Thermo & Comfort SE" 533 "Doran Manufacturing, LLC" 532 "Onwa Marine Electronics Co Ltd." 531 "Genge & Thoma AG" 530 "NMEA" 529 "National Instruments Korea" 528 "Hoganas AB, Electric Drive Systems" 527 "GKN Walterscheid GmbH" 526 "LOFA Industries, Inc" 525 "Rust Sales INC" 524 "Vomax Instrumentation Pty. Ltd." 523 "Reggio Emilia Innovazione" 522 "Nebraska Tractor Test Laboratory" 521 "Clever Devices Ltd." 520 "Trapeze" 519 "Peeters Landbouwmachines b.v." 518 "Transas USA Inc." 517 "Noland Engineering" 516 "AVAT Automation GmbH" 515 "GINAF Trucks Nederland B.V." 514 "DISTek Integration, Inc." 513 "Precision Technology (formerly FarmscanAg)" 512 "Inpower LLC" 511 "Burel Production (formerly Sulky)" 510 "Marinesoft Co. Ltd" 509 "MOTORTECH GmbH" 508 "Transtech Innovations" 507 "ISOBUS Test Center" 506 "IHI STAR Machinery Corporation" 505 "Yetter Farm Equipment" 504 "Vesper Marine" 503 "Naviop S.R.L." 502 "Attwood Corporation" 501 "Agrotronix S.A." 500 "Oxbo International Corporation" 499 "LCJ Capteurs" 498 "Innovative Design Solutions, Inc." 497 "SENTRON Sistemas Embarcados" 496 "W. Gessmann GmbH" 495 "HOLMER Maschinenbau GmbH" 494 "Synerject" 493 "Watcheye" 492 "Inergy Automotive Systems" 491 "Penny and Giles Ltd" 490 "QuikQ" 489 "Appareo Systems, LLC" 488 "The Charles Machine Works, Inc." 487 "DSE Test Solutions A/S" 486 "Westport Innovations Inc." 485 "MATT automotive" 484 "Headsight Inc." 483 "Valeo" 482 "Tricon Electronics" 481 "Chetco Digital Instruments" 480 "EnerDel, Inc." 479 "Vapor Bus International" 478 "OceanSat B.V." 477 "OilQuick AB" 476 "Hummingbird Marine Electronics" 475 "GME" 474 "Persen Technologies Inc." 473 "Boss Industries, Inc." 472 "Tenneco Inc." 471 "Sea Cross Marine AB" 470 "SI-TEX Marine Electronics" 469 "RA Consulting GmbH" 468 "Tyco Fire Protection Products" 467 "Lely Industries N.V." 466 "Veethree Electronics and Marine LLC" 465 "Ashcroft Inc" 464 "Leach International Corporation" 463 "PROBOTIQ" 462 "IHI Shibaura Machinery Corporation" 461 "HAWE Hydraulik SE" 460 "San Giorgio S.E.I.N." 459 "Alltek Marine Electronics Corp" 458 "Control Solutions, Inc." 457 "RUSELPROM-ElectricDrive Ltd" 456 "General Kinetics" 455 "ADZ NAGANO GmbH" 454 "NGK Spark Plug Co. Ltd" 453 "Cooper Bussmann" 452 "WIKA Alexander Wiegand SE & Co. KG" 451 "Parker Hannifin Corp" 450 "Dycor Technologies Ltd." 449 "Polaris Industries Inc" 448 "Stanadyne Corporation, Electronics Systems" 392 "Tianyuan Technology Co Ltd." 391 "Electronic Design for Industry, Inc" 390 "Partech Inc." 389 "Benchmark Electronics, Minnesota Division" 388 "Innomatix, LLC" 387 "Orscheln Products, LLC" 386 "JLG Automation BVBA" 385 "Johnson Outdoor Marine Electronics" 384 "Camano Light" 383 "MCL Industries" 382 "National Agriculture and Food Research Organization" 381 "B & G" 380 "Suntech International Ltd." 379 "Yamabiko Corporation" 378 "Glendinning Marine Products" 377 "ifm electronic gmbh" 376 "Quake Global" 375 "Williams Controls Inc." 374 "Northern Lights, Inc." 373 "Electronic Design Inc." 372 "Delphi" 371 "Heinzmann GmbH & Co. KG" 370 "Rolls-Royce Marine AS" 369 "Power Torque Engineering Ltd" 368 "HANSENHOF_electronic" 367 "Fliegl Agrartechnik" 366 "Viewnyx Corp." 365 "Digi-Star, LLC" 364 "OEM Controls Inc." 363 "BEI Duncan" 362 "Poettinger Landtechnik GmbH (formerly Alois Poettinger Maschinenfabrik GmbH)" 361 "InMach" 360 "HJS Emission Technology GmbH & Co KG   (formerly HJS Fahrzeugtechnik GmbH & Co KG)" 359 "Ludwig Bergmann GmbH" 358 "Victron Energy B.V." 357 "Hardi International A/S" 356 "Fischer Panda Generators, Inc" 355 "Mastervolt International B.V." 354 "Junkkari OY" 353 "Hegemon Electronics, Inc." 352 "SAME DEUTZ-FAHR GROUP S.p.A." 351 "Thrane & Thrane" 350 "Noris Marine Systems GmbH & Co KG" 349 "Suonentieto" 348 "Amazonen Werke H. Dreyer" 347 "Honeywell" 346 "Control Solutions" 345 "Korean Maritime University" 344 "Parvus Corporation" 343 "Baumer Group" 342 "THOMAS MAGNETE GmbH" 341 "Boning GmbH & Co" 340 "Continental AG" 339 "Competence Center ISOBUS e.V." 338 "GRAF-SYTECO" 337 "Carraro S.p.A." 336 "APE s.r.o." 335 "Evo Electric Ltd" 334 "Takata-Petri AG" 333 "Hadley Products Corporation" 332 "HWH Corporation" 331 "Horton, Inc." 330 "Kidde Aerospace and Defense" 329 "Deif A/S" 328 "Qwerty Electronik AB" 327 "Sonceboz SA" 326 "Akron Brass Company" 325 "ASM Automation Sensorik Messtechnik GmbH" 324 "Snap-on Diagnostics" 323 "Mobileye Vision Technologies Ltd." 322 "MICHENKA s.r.o." 321 "Ultra Electronics, Electrics" 320 "Miedema Landbouwwerktuigenfabriek B.V." 319 "Cadec Global" 318 "SAT Plan" 317 "Navtronics Bvba" 316 "ITT Flow Control" 315 "Icom Incorporated" 314 "CSM GmbH" 313 "Ilmor Engineering, Inc." 312 "Lectronix, Inc." 311 "Patrick Power Products" 310 "TECNORD srl" 309 "Krauss-Maffei Wegmann GmbH & Co. KG" 308 "Cyntrx" 307 "MAS Technologies" 306 "Sleipner Motor AB" 305 "NovAtel Inc" 304 "EmpirBus AB" 303 "CTS Corporation" 302 "Nissin Kogyo Co., LTD" 301 "Parker Hannifin (UK) Ltd FDE group" 300 "Systron Donner Automotive" 299 "Rauch" 298 "Holley Performance" 297 "Zonar Systems Inc" 296 "micro dynamics GmbH" 295 "BEP Marine" 294 "Grayhill Inc." 293 "Spyder Controls Corp." 292 "IKUSI - Angel Iglesias S.A." 291 "Groeneveld Transport Efficiency BV" 290 "Kuebler GmbH" 289 "Watlow" 288 "Mitsubishi FUSO Truck & Bus Corp." 287 "NTech Industries, Inc" 286 "Coelmo srl" 285 "Sea Recovery Corp" 284 "Mobile Tech Chile" 283 "CWF Hamilton & Co Ltd" 282 "Medallion Instrumentation Systems" 281 "Precision Governors LLC" 280 "Leica Geosystems Pty Ltd" 279 "Geometris LP" 278 "Takata Electronics" 277 "LHP Telematics" 276 "Aqua-Hot Heating Systems" 275 "Navico Egersund AS" 274 "LTW Technology Co., LTD" 273 "Active Research Limited" 272 "Gross Mechanical Laboratories, Inc" 271 "Cole Hersee" 270 "Tennant" 269 "Saft America Inc.,  Space & Defense Division" 268 "Accurate Technologies" 267 "Red Lion Controls, Inc" 266 "International Thermal Research Ltd" 265 "MTS Sensor Technologie GmbH" 264 "Autolync" 263 "IMMI" 262 "HydraForce, Inc" 261 "Red Dot Corporation" 260 "Reichhardt GmbH Steuerungstechnik" 259 "Jetter AG" 258 "ARAG" 257 "Honda Motor Co., Ltd" 256 "Tyco Electronics AMP" 255 "MEAS France" 254 "GE Sensing" 253 "Mobile Control Systems" 252 "Sensor-Technik Wiedemann GmbH" 251 "German Agricultural Society, Test Center (DLG)" 250 "Kuhn Group" 249 "Schaltbau GmbH" 248 "Cooper Standard Automotive Active Systems Group" 247 "ePULSE" 246 "Class 1, Inc" 245 "Capstan Ag Systems, Inc." 244 "Techno-Matic" 243 "eRide, Inc." 242 "Kokusandenki Co. Ltd" 241 "Schneider Automation SAS" 240 "Vanair Mfg" 239 "May & Scofield Ltd" 238 "ZF Friedrichshafen AG" 237 "Agtron Enterprises Inc" 236 "NORAC Systems International Inc" 235 "SailorMade Marine Telemetry - Tetra Technology Ltd." 234 "Mondial electronic GmbH" 233 "Yacht Monitoring Solutions Inc." 232 "TSD Integrated Controls" 231 "Topcon Positioning Systems, Inc." 230 "Saucon Technologies" 229 "Garmin International Inc." 228 "Unused (formerly ZF Marine Electronics)" 227 "Lykketronic A/S" 226 "Monaco Coach Corporation" 225 "SKF" 224 "EMMI Network, S.L." 223 "Vaueo Retarder Co., Ltd." 222 "Generac Power Systems, Inc." 221 "SiE" 220 "Beede Electrical Instrument Company, Inc" 219 "Cat OEM Solutions" 218 "Gits Manufacturing Company" 217 "RM Michaelides Software & Elektronik GmbH" 216 "Paneltronics Inc." 215 "Aetna Engineering/Fireboy-Xintex" 214 "MC elettronica Srl" 213 "CNH Belgium N.V." 212 "Sure Power Industries, Inc" 211 "DNA Group" 210 "Iteris, Inc." 209 "Bell Equip. Co. SA (PTY) LTD" 208 "Drew Technologies, Inc" 207 "Otto Engineering" 206 "port GmbH" 205 "SmarTire Systems Inc" 204 "The Morey Corporation" 203 "MILtronik GmbH" 202 "Curtis Instruments, Inc" 201 "Disenos y Tecnologia S.A." 200 "MGM Brakes" 199 "ACTIA Group (formerly Actia Corp)" 198 "Mystic Valley Communications" 197 "Mechron Power Systems" 196 "LEMKEN GmbH & Co KG" 195 "General Engine Products" 194 "TriMark Corporation" 193 "Jeppesen Marine" 192 "Floscan" 191 "XRS Corporation (formerly XATA Corporation)" 190 "Hella KGaA Hueck & Co" 189 "QUALCOMM" 103 "CLAAS E-Systems GmbH (formerly CLAAS E-Systems KGaA mbH & Co. KG)" 102 "AGCO (formerly AGCO GmbH & Co.)" 101 "Sensoria" 100 "VDO Technik AG" 99 "International Transmissions Ltd (ITL)" 98 "Mueller-Elektronik GmbH & Co" 97 "Ag Leader Technology, Inc." 96 "Mech@tronic IT GmbH" 95 "Pacific Insight Electronics Corp." 94 "CNH Industrial N.V. (formerly CNH Global N.V.)" 93 "Perkins Engines Company Ltd." 92 "Ag-Chem Equipment Co., Inc." 91 "BSG Bodensee Steuergeraete GmbH" 90 "Knorr-Bremse SfN GmbH" 89 "Kverneland Group, Electronics Division" 88 "Hemisphere GPS Inc (formerly Satloc Precision GPS)" 188 "EMP Corp" 187 "Air-Weigh" 186 "Altronic, Inc" 185 "Beede Electrical Instrument Company" 184 "EIA Electronics" 183 "KDS Controls, Inc" 182 "Vehicle Systems Engineering B.V." 181 "Coretronics, Inc." 180 "Smart Power Systems" 179 "TeeJet Technologies Springfield (formerly Midwest Technologies Illinois, LLC)" 178 "Continental Automotive GmbH (formerly Siemens VDO Automotive AG)" 177 "Diagnostic Systems Associates" 176 "Moritz Aerospace" 175 "Veris Technologies, Inc." 174 "AB Volvo Penta" 173 "Ryeso, Inc." 172 "Yanmar Co., Ltd. (formerly Yanmar Marine USA)" 171 "Topcon Electronics GmbH & Co. KG (formerly Wachendorff Elektronik GmbH & Co. KG)" 170 "Computronics Corporation Ltd." 169 "Marlin Technologies Inc." 168 "Xantrex" 167 "JLG Industries Inc" 166 "John Deere Electronic Solutions (formerly Phoenix International)" 165 "CPAC Systems AB" 164 "MTU Friedrichshafen GmbH (formerly DaimlerChrysler Off-Highway)" 163 "BRP Inc." 162 "Axiomatic Technologies" 161 "Offshore Systems (UK) Ltd" 160 "Nido" 159 "NTech Industries Inc" 158 "Firestone Industrial Products Company" 157 "ISSPRO Inc." 156 "ITT Industries - Cannon" 155 "Vetronix Corporation" 154 "Westerbeke Corporation" 153 "Woodward, Industrial Controls Division" 152 "elobau GmbH & Co. KG" 151 "Raven Industries, Inc." 150 "Fleetguard" 149 "Holset" 148 "Blue Water Data, Inc." 147 "Nautibus electronic GmbH" 146 "Maxima Technologies" 145 "MurCal Controls" 144 "Mercury Marine" 143 "W. Gmeiner GmbH & Co." 87 "J.C. Bamford Excavators Ltd (JCB)" 86 "C. E. Niehoff & Company" 85 "Kohler Co" 84 "New Holland UK Limited" 83 "Bendix VORAD Technologies (formerly Eaton VORAD Technologies)" 82 "Bobcat/Ingersoll-Rand (formerly Melroe/Ingersoll-Rand)" 81 "Fire Research Corp." 80 "Twin Disc, Inc." 79 "Daimler Benz AG - Engine Division (PBM)" 78 "Frank W. Murphy Manufacturing, Inc" 77 "Deere Power Systems Group" 76 "unused (formerly Deere & Co, Construction Division)" 75 "Deere & Co, Agricultural Division" 74 "Eaton Axle-Brake Division" 73 "LeTourneau, Inc." 72 "Sisu Corporation" 71 "Vansco Electronics Ltd." 70 "Flex-coil Limited" 69 "Trimble Navigation" 68 "Scania" 67 "John Deere Coffeyville Works (formerly Funk Manufacturing Company)" 66 "John Deere Construction Equipment Division" 65 "MAN Nutzfahrzeuge AG" 64 "Unused (formerly SpectraPrecision Laserplane, then SpectraPhysics)" 63 "ZF Industries Inc." 62 "Wabco" 61 "Volvo Truck Corp." 60 "Volvo Trucks North America Inc." 59 "VES Inc." 58 "SPX Corporation, OTC Div" 57 "Danfoss  (formerly Sauer Sundstrand Co, then Sauer-Danfoss Co)" 56 "SAIC" 55 "Ryder System Inc." 54 "Meritor Wabco" 53 "Continental Automotive Systems US, Inc. (formerly Rockwell Land Transportation)" 52 "Meritor Automotive, Inc. (formerly Rockwell Automotive)" 51 "Robert Bosch GmbH" 50 "Robert Bosch Corp" 49 "RE America Inc." 48 "Pollak Alphabet" 47 "Phillips Semiconductor" 46 "Noregon Systems, Inc  (formerly Parasoft Computing Solutions)" 45 "PACCAR" 44 "Nippondenso Co. Ltd." 43 "International Truck and Engine Corporation - Vehicle Electronics (formerly Navistar Intl Trans Corp.)" 42 "International Truck and Engine Corporation - Engine Electronics  (formerly Navistar Intl Trans Co., Engine Electronics)" 41 "Motorola Inc." 40 "Motorola AIEG Inc." 39 "Microfirm Inc." 38 "Micro Processor Systems Inc." 37 "Mack Trucks Inc." 36 "Lucas Ind." 35 "Kenworth Truck Co." 34 "Kelsey Hayes Co." 33 "John Deere" 32 "Jacobs Vehicle Systems" 31 "J Pollak Corp" 30 "Isuzu Motors Ltd" 29 "Hino Motors Ltd." 28 "Grote Ind. Inc." 27 "GMC" 26 "General Motors Corp, Service Technology Grp" 25 "Daimler Trucks North America LLC (formerly Freightliner LLC)" 24 "Ford Motor Co., Vehicle Controls" 23 "Ford Motor Co., Heavy Truck" 22 "Ford Motor Co., Electronic Concepts & Systems" 21 "Echlin Inc., Midland Brake Inc." 20 "Eaton Ltd" 19 "Eaton Corp. Trucking Info Services" 18 "Eaton Corp, Transmission Div." 17 "Eaton Corp, Corp Res & Dev" 16 "Eaton Corp" 15 "DICKEY-john Corporation" 14 "Detroit Diesel Corporation" 13 "Delco Electronics" 12 "Deere & Company, Precision Farming" 11 "Dearborn Group Inc." 10 "Cummins Inc (formerly Cummins Engine Co)" 9 "Chrysler Corp." 8 "Caterpillar Inc." 7 "Case Corp." 6 "Berifors Electronics AB" 5 "AMP Inc." 4 "Ametek-Dixson" 3 "Ametek, US Gauge Division" 2 "Allison Transmission, Inc." 1 "Bendix Commercial Vehicle Systems LLC (formerly Allied Signal Inc.)" 0 "Reserved" ;
VAL_ 2558721790 SnsrEnableSetting 3 "Don't Care / Take No Action" 2 "Reserved / Not Defined" 1 "On / Enable" 0 "Off / Isolate / Disable" ;
VAL_ 2566702846 EngOBDWarmUpSequence 3 "Not supported or not available" 2 "SAE reserved" 1 "A warm-up cycle has occurred on this engine start" 0 "A warm-up cycle has not occurred on this engine start" ;
VAL_ 2566705918 AmberWarningLampStatus 3 "Not available" 2 "Reserved" 1 "Lamp On" 0 "Lamp Off" ;
VAL_ 2566705918 FlashAmberWarningLamp 3 "Unavailable / Do Not Flash" 2 "Reserved" 1 "Fast Flash" 0 "Slow Flash" ;
VAL_ 2566705918 FlashMalfuncIndicatorLamp 3 "Unavailable / Do Not Flash" 2 "Class C DTC  " 1 "Fast Flash" 0 "Slow Flash" ;
VAL_ 2566705918 FlashProtectLamp 3 "Unavailable / Do Not Flash" 2 "Reserved" 1 "Fast Flash" 0 "Slow Flash" ;
VAL_ 2566705918 FlashRedStopLamp 3 "Unavailable / Do Not Flash" 2 "Reserved" 1 "Fast Flash" 0 "Slow Flash" ;
VAL_ 2566705918 MalfunctionIndicatorLampStatus 3 "Not available" 2 "Short MIL for WWH OBD" 1 "Lamp On" 0 "Lamp Off" ;
VAL_ 2566705918 ProtectLampStatus 3 "Not available" 2 "Reserved" 1 "Lamp On" 0 "Lamp Off" ;
VAL_ 2566705918 RedStopLampState 3 "Not available" 2 "Reserved" 1 "Lamp On" 0 "Lamp Off" ;
VAL_ 2566705662 AmberWarningLampStatus 3 "Not available" 2 "Reserved" 1 "Lamp On" 0 "Lamp Off" ;
VAL_ 2566705662 FlashAmberWarningLamp 3 "Unavailable / Do Not Flash" 2 "Reserved" 1 "Fast Flash" 0 "Slow Flash" ;
VAL_ 2566705662 FlashMalfuncIndicatorLamp 3 "Unavailable / Do Not Flash" 2 "Class C DTC  " 1 "Fast Flash" 0 "Slow Flash" ;
VAL_ 2566705662 FlashProtectLamp 3 "Unavailable / Do Not Flash" 2 "Reserved" 1 "Fast Flash" 0 "Slow Flash" ;
VAL_ 2566705662 FlashRedStopLamp 3 "Unavailable / Do Not Flash" 2 "Reserved" 1 "Fast Flash" 0 "Slow Flash" ;
VAL_ 2566705662 MalfunctionIndicatorLampStatus 3 "Not available" 2 "Short MIL for WWH OBD" 1 "Lamp On" 0 "Lamp Off" ;
VAL_ 2566705662 ProtectLampStatus 3 "Not available" 2 "Reserved" 1 "Lamp On" 0 "Lamp Off" ;
VAL_ 2566705662 RedStopLampState 3 "Not available" 2 "Reserved" 1 "Lamp On" 0 "Lamp Off" ;
VAL_ 2560818942 FailureModeIdentifier1 31 "Not available" 19 "Received network data in error" 18 "Below normal (moderately severe)" 17 "Below normal (least severe)" 16 "Above normal (moderately severe)" 15 "Above normal (least severe)" 14 "Special intstructions" 13 "Out of calibration" 12 "Bad intelligent device" 11 "Root cause not known" 10 "Abnormal rate of change" 9 "Abnormal update rate" 8 "Abnormal frequency" 7 "Mechanical system not responding" 6 "Current above normal" 5 "Current below normal" 4 "Voltage below normal" 3 "Voltage above normal" 2 "Data erratic" 1 "Below normal (most severe)" 0 "Above normal (most severe)" ;
VAL_ 2566764798 ACSystemRefrigerantMonComplete 1 "NotCompleteCycle" 0 "CompleteCycleOrNotSupported" ;
VAL_ 2566764798 ACSystemRefrigerantMonEnabled 1 "NotCompleteCycle" 0 "CompleteCycleOrNotSupported" ;
VAL_ 2566764798 CatalystMonComplete 1 "NotCompleteCycle" 0 "CompleteCycleOrNotSupported" ;
VAL_ 2566764798 CatalystMonEnabled 1 "NotCompleteCycle" 0 "CompleteCycleOrNotSupported" ;
VAL_ 2566764798 ColdStartAidSystemMonComplete 1 "EnabledForCycle" 0 "DisabledForRestOfCycle" ;
VAL_ 2566764798 ColdStartAidSystemMonEnabled 1 "EnabledForCycle" 0 "DisabledForRestOfCycle" ;
VAL_ 2566764798 ComprehensiveCompMonEnabled 1 "NotCompleteCycle" 0 "CompleteCycleOrNotSupported" ;
VAL_ 2566764798 ComprehensiveComptMonComplete 1 "NotCompleteCycle" 0 "CompleteCycleOrNotSupported" ;
VAL_ 2566764798 EGRSystemMonitoringComplete 1 "NotCompleteCycle" 0 "CompleteCycleOrNotSupported" ;
VAL_ 2566764798 EGRSystemMonitoringEnabled 1 "EnabledForCycle" 0 "DisabledForRestOfCycle" ;
VAL_ 2566764798 EvaporativeSystemMonComplete 1 "NotCompleteCycle" 0 "CompleteCycleOrNotSupported" ;
VAL_ 2566764798 EvaporativeSystemMonEnabled 1 "NotCompleteCycle" 0 "CompleteCycleOrNotSupported" ;
VAL_ 2566764798 FuelSystemMonitoringComplete 1 "NotCompleteCycle" 0 "CompleteCycleOrNotSupported" ;
VAL_ 2566764798 FuelSystemMonitoringEnabled 1 "NotCompleteCycle" 0 "CompleteCycleOrNotSupported" ;
VAL_ 2566764798 HeatedCatalystMonComplete 1 "EnabledForCycle" 0 "DisabledForRestOfCycle" ;
VAL_ 2566764798 HeatedCatalystMonEnabled 1 "EnabledForCycle" 0 "DisabledForRestOfCycle" ;
VAL_ 2566764798 MisfireMonitoringComplete 1 "EnabledForCycle" 0 "DisabledForRestOfCycle" ;
VAL_ 2566764798 MisfireMonitoringEnabled 1 "EnabledForCycle" 0 "DisabledForRestOfCycle" ;
VAL_ 2566764798 OxygenSensorHeaterMonComplete 1 "EnabledForCycle" 0 "DisabledForRestOfCycle" ;
VAL_ 2566764798 OxygenSensorHeaterMonEnabled 1 "NotCompleteCycle" 0 "CompleteCycleOrNotSupported" ;
VAL_ 2566764798 OxygenSensorMonComplete 1 "EnabledForCycle" 0 "DisabledForRestOfCycle" ;
VAL_ 2566764798 OxygenSensorMonEnabled 1 "NotCompleteCycle" 0 "CompleteCycleOrNotSupported" ;
VAL_ 2566764798 SecondAirSystemMonComplete 1 "EnabledForCycle" 0 "DisabledForRestOfCycle" ;
VAL_ 2566764798 SecondAirSystemMonEnabled 1 "EnabledForCycle" 0 "DisabledForRestOfCycle" ;
VAL_ 2564095742 SecurityEntityType 3 "Data is Certificate" 2 "Data is Session Key" 1 "Data is Long Key" 0 "Data is Long Seed" ;
VAL_ 2561605374 TireLocation 51 "Axle3_Position3" 50 "Axle3_Position2" 49 "Axle3_Position1" 35 "Axle2_Position3" 34 "Axle2_Position2" 33 "Axle2_Position1" 19 "Axle1_Position3" 18 "Axle1_Position2" 17 "Axle1_Position1" 1 "Axle0_Position1" 48 "Axle3_Position0" 32 "Axle2_Position0" 16 "Axle1_Position0" 0 "Axle0_Position0" ;
VAL_ 2566765054 TireLocation 51 "Axle3_Position3" 50 "Axle3_Position2" 49 "Axle3_Position1" 35 "Axle2_Position3" 34 "Axle2_Position2" 33 "Axle2_Position1" 19 "Axle1_Position3" 18 "Axle1_Position2" 17 "Axle1_Position1" 1 "Axle0_Position1" 48 "Axle3_Position0" 32 "Axle2_Position0" 16 "Axle1_Position0" 0 "Axle0_Position0" ;
VAL_ 2633922814 DriveChannelMode 15 "Not available" 14 "Error Condition" 13 "Reserved" 12 "Reserved" 11 "Reserved" 10 "Reserved" 9 "Reserved" 8 "Reserved" 7 "Reserved" 6 "Pressure Check" 5 "Deflate Wait" 4 "Inflate Wait" 3 "Confirm" 2 "Deflate" 1 "Inflate" 0 "Maintain" ;
VAL_ 2633922814 PCUCtrlSolenoidStatus 3 "Not available" 2 "Error" 1 "On" 0 "Off" ;
VAL_ 2633922814 PCUDeflateSolenoidStatus 3 "Not available" 2 "Error" 1 "On" 0 "Off" ;
VAL_ 2633922814 PCUDriveSolenoidStatus 3 "Not available" 2 "Error" 1 "On" 0 "Off" ;
VAL_ 2633922814 PCUSteerSolenoidStatus 3 "Not available" 2 "Error" 1 "On" 0 "Off" ;
VAL_ 2633922814 PCUSupplySolenoidStatus 3 "Not available" 2 "Error" 1 "On" 0 "Off" ;
VAL_ 2633922814 PCUTrilerTagOrPushSolenoidStatus 3 "Not available" 2 "Error" 1 "On" 0 "Off" ;
VAL_ 2633922814 SteerChannelMode 15 "Not available" 14 "Error Condition" 13 "Reserved" 12 "Reserved" 11 "Reserved" 10 "Reserved" 9 "Reserved" 8 "Reserved" 7 "Reserved" 6 "Pressure Check" 5 "Deflate Wait" 4 "Inflate Wait" 3 "Confirm" 2 "Deflate" 1 "Inflate" 0 "Maintain" ;
VAL_ 2633922814 TirePressSupplySwitchStatus 3 "Not available" 2 "Error" 1 "On" 0 "Off" ;
VAL_ 2633922814 Trailer_tagChannelMode 15 "Not available" 14 "Error Condition" 13 "Reserved" 12 "Reserved" 11 "Reserved" 10 "Reserved" 9 "Reserved" 8 "Reserved" 7 "Reserved" 6 "Pressure Check" 5 "Deflate Wait" 4 "Inflate Wait" 3 "Confirm" 2 "Deflate" 1 "Inflate" 0 "Maintain" ;
VAL_ 2566845694 CTITireStatus_00 3 "NotSupported" 2 "Error" 1 "TireLeakDetected" 0 "Ok" ;
VAL_ 2566845694 CTITireStatus_01 3 "NotSupported" 2 "Error" 1 "TireLeakDetected" 0 "Ok" ;
VAL_ 2566845694 CTITireStatus_10 3 "NotSupported" 2 "Error" 1 "TireLeakDetected" 0 "Ok" ;
VAL_ 2566845694 CTITireStatus_11 3 "NotSupported" 2 "Error" 1 "TireLeakDetected" 0 "Ok" ;
VAL_ 2566845694 CTITireStatus_12 3 "NotSupported" 2 "Error" 1 "TireLeakDetected" 0 "Ok" ;
VAL_ 2566845694 CTITireStatus_13 3 "NotSupported" 2 "Error" 1 "TireLeakDetected" 0 "Ok" ;
VAL_ 2566845694 CTITireStatus_20 3 "NotSupported" 2 "Error" 1 "TireLeakDetected" 0 "Ok" ;
VAL_ 2566845694 CTITireStatus_21 3 "NotSupported" 2 "Error" 1 "TireLeakDetected" 0 "Ok" ;
VAL_ 2566845694 CTITireStatus_22 3 "NotSupported" 2 "Error" 1 "TireLeakDetected" 0 "Ok" ;
VAL_ 2566845694 CTITireStatus_23 3 "NotSupported" 2 "Error" 1 "TireLeakDetected" 0 "Ok" ;
VAL_ 2566845694 CTITireStatus_30 3 "NotSupported" 2 "Error" 1 "TireLeakDetected" 0 "Ok" ;
VAL_ 2566845694 CTITireStatus_31 3 "NotSupported" 2 "Error" 1 "TireLeakDetected" 0 "Ok" ;
VAL_ 2566845694 CTITireStatus_32 3 "NotSupported" 2 "Error" 1 "TireLeakDetected" 0 "Ok" ;
VAL_ 2566845694 CTITireStatus_33 3 "NotSupported" 2 "Error" 1 "TireLeakDetected" 0 "Ok" ;
VAL_ 2566845694 CTIWheelEndElectricalFault_00 3 "NotSupported" 2 "Error" 1 "NotDefined" 0 "Ok" ;
VAL_ 2566845694 CTIWheelEndElectricalFault_01 3 "NotSupported" 2 "Error" 1 "NotDefined" 0 "Ok" ;
VAL_ 2566845694 CTIWheelEndElectricalFault_10 3 "NotSupported" 2 "Error" 1 "NotDefined" 0 "Ok" ;
VAL_ 2566845694 CTIWheelEndElectricalFault_11 3 "NotSupported" 2 "Error" 1 "NotDefined" 0 "Ok" ;
VAL_ 2566845694 CTIWheelEndElectricalFault_12 3 "NotSupported" 2 "Error" 1 "NotDefined" 0 "Ok" ;
VAL_ 2566845694 CTIWheelEndElectricalFault_13 3 "NotSupported" 2 "Error" 1 "NotDefined" 0 "Ok" ;
VAL_ 2566845694 CTIWheelEndElectricalFault_20 3 "NotSupported" 2 "Error" 1 "NotDefined" 0 "Ok" ;
VAL_ 2566845694 CTIWheelEndElectricalFault_21 3 "NotSupported" 2 "Error" 1 "NotDefined" 0 "Ok" ;
VAL_ 2566845694 CTIWheelEndElectricalFault_22 3 "NotSupported" 2 "Error" 1 "NotDefined" 0 "Ok" ;
VAL_ 2566845694 CTIWheelEndElectricalFault_23 3 "NotSupported" 2 "Error" 1 "NotDefined" 0 "Ok" ;
VAL_ 2566845694 CTIWheelEndElectricalFault_30 3 "NotSupported" 2 "Error" 1 "NotDefined" 0 "Ok" ;
VAL_ 2566845694 CTIWheelEndElectricalFault_31 3 "NotSupported" 2 "Error" 1 "NotDefined" 0 "Ok" ;
VAL_ 2566845694 CTIWheelEndElectricalFault_32 3 "NotSupported" 2 "Error" 1 "NotDefined" 0 "Ok" ;
VAL_ 2566845694 CTIWheelEndElectricalFault_33 3 "NotSupported" 2 "Error" 1 "NotDefined" 0 "Ok" ;
VAL_ 2566845694 CTIWheelSensorStatus_00 3 "NotSupported" 2 "NotDefined" 1 "On" 0 "Off_IsolatedFromCTIPressCtrl" ;
VAL_ 2566845694 CTIWheelSensorStatus_01 3 "NotSupported" 2 "NotDefined" 1 "On" 0 "Off_IsolatedFromCTIPressCtrl" ;
VAL_ 2566845694 CTIWheelSensorStatus_10 3 "NotSupported" 2 "NotDefined" 1 "On" 0 "Off_IsolatedFromCTIPressCtrl" ;
VAL_ 2566845694 CTIWheelSensorStatus_11 3 "NotSupported" 2 "NotDefined" 1 "On" 0 "Off_IsolatedFromCTIPressCtrl" ;
VAL_ 2566845694 CTIWheelSensorStatus_12 3 "NotSupported" 2 "NotDefined" 1 "On" 0 "Off_IsolatedFromCTIPressCtrl" ;
VAL_ 2566845694 CTIWheelSensorStatus_13 3 "NotSupported" 2 "NotDefined" 1 "On" 0 "Off_IsolatedFromCTIPressCtrl" ;
VAL_ 2566845694 CTIWheelSensorStatus_20 3 "NotSupported" 2 "NotDefined" 1 "On" 0 "Off_IsolatedFromCTIPressCtrl" ;
VAL_ 2566845694 CTIWheelSensorStatus_21 3 "NotSupported" 2 "NotDefined" 1 "On" 0 "Off_IsolatedFromCTIPressCtrl" ;
VAL_ 2566845694 CTIWheelSensorStatus_22 3 "NotSupported" 2 "NotDefined" 1 "On" 0 "Off_IsolatedFromCTIPressCtrl" ;
VAL_ 2566845694 CTIWheelSensorStatus_23 3 "NotSupported" 2 "NotDefined" 1 "On" 0 "Off_IsolatedFromCTIPressCtrl" ;
VAL_ 2566845694 CTIWheelSensorStatus_30 3 "NotSupported" 2 "NotDefined" 1 "On" 0 "Off_IsolatedFromCTIPressCtrl" ;
VAL_ 2566845694 CTIWheelSensorStatus_31 3 "NotSupported" 2 "NotDefined" 1 "On" 0 "Off_IsolatedFromCTIPressCtrl" ;
VAL_ 2566845694 CTIWheelSensorStatus_32 3 "NotSupported" 2 "NotDefined" 1 "On" 0 "Off_IsolatedFromCTIPressCtrl" ;
VAL_ 2566845694 CTIWheelSensorStatus_33 3 "NotSupported" 2 "NotDefined" 1 "On" 0 "Off_IsolatedFromCTIPressCtrl" ;
VAL_ 2566845694 ExTirePressSupport 3 "Not Available/Not Supported" 2 "Error" 1 "Using Extended Tire Pressure" 0 "Not Using Extended Tire Pressure" ;
VAL_ 2566845694 TirePressThresholdDetection_00 7 "NotAvailable" 6 "ErrorIndicator" 5 "NotDefined" 4 "ExtrmUndrPrssTrPrssrIsAtALvlWhr" 3 "UndrPrssTrPrssrIsLwrThnThPrssrD" 2 "NWrnngPrssTrPrssrIsWthnThThrshl" 1 "OvrPrssTrPrssrIsHghrThnThPrssrD" 0 "ExtrmOvrPrssTrPrssrIsAtALvlWhrT" ;
VAL_ 2566845694 TirePressThresholdDetection_01 7 "NotAvailable" 6 "ErrorIndicator" 5 "NotDefined" 4 "ExtrmUndrPrssTrPrssrIsAtALvlWhr" 3 "UndrPrssTrPrssrIsLwrThnThPrssrD" 2 "NWrnngPrssTrPrssrIsWthnThThrshl" 1 "OvrPrssTrPrssrIsHghrThnThPrssrD" 0 "ExtrmOvrPrssTrPrssrIsAtALvlWhrT" ;
VAL_ 2566845694 TirePressThresholdDetection_10 7 "NotAvailable" 6 "ErrorIndicator" 5 "NotDefined" 4 "ExtrmUndrPrssTrPrssrIsAtALvlWhr" 3 "UndrPrssTrPrssrIsLwrThnThPrssrD" 2 "NWrnngPrssTrPrssrIsWthnThThrshl" 1 "OvrPrssTrPrssrIsHghrThnThPrssrD" 0 "ExtrmOvrPrssTrPrssrIsAtALvlWhrT" ;
VAL_ 2566845694 TirePressThresholdDetection_11 7 "NotAvailable" 6 "ErrorIndicator" 5 "NotDefined" 4 "ExtrmUndrPrssTrPrssrIsAtALvlWhr" 3 "UndrPrssTrPrssrIsLwrThnThPrssrD" 2 "NWrnngPrssTrPrssrIsWthnThThrshl" 1 "OvrPrssTrPrssrIsHghrThnThPrssrD" 0 "ExtrmOvrPrssTrPrssrIsAtALvlWhrT" ;
VAL_ 2566845694 TirePressThresholdDetection_12 7 "NotAvailable" 6 "ErrorIndicator" 5 "NotDefined" 4 "ExtrmUndrPrssTrPrssrIsAtALvlWhr" 3 "UndrPrssTrPrssrIsLwrThnThPrssrD" 2 "NWrnngPrssTrPrssrIsWthnThThrshl" 1 "OvrPrssTrPrssrIsHghrThnThPrssrD" 0 "ExtrmOvrPrssTrPrssrIsAtALvlWhrT" ;
VAL_ 2566845694 TirePressThresholdDetection_13 7 "NotAvailable" 6 "ErrorIndicator" 5 "NotDefined" 4 "ExtrmUndrPrssTrPrssrIsAtALvlWhr" 3 "UndrPrssTrPrssrIsLwrThnThPrssrD" 2 "NWrnngPrssTrPrssrIsWthnThThrshl" 1 "OvrPrssTrPrssrIsHghrThnThPrssrD" 0 "ExtrmOvrPrssTrPrssrIsAtALvlWhrT" ;
VAL_ 2566845694 TirePressThresholdDetection_20 7 "NotAvailable" 6 "ErrorIndicator" 5 "NotDefined" 4 "ExtrmUndrPrssTrPrssrIsAtALvlWhr" 3 "UndrPrssTrPrssrIsLwrThnThPrssrD" 2 "NWrnngPrssTrPrssrIsWthnThThrshl" 1 "OvrPrssTrPrssrIsHghrThnThPrssrD" 0 "ExtrmOvrPrssTrPrssrIsAtALvlWhrT" ;
VAL_ 2566845694 TirePressThresholdDetection_21 7 "NotAvailable" 6 "ErrorIndicator" 5 "NotDefined" 4 "ExtrmUndrPrssTrPrssrIsAtALvlWhr" 3 "UndrPrssTrPrssrIsLwrThnThPrssrD" 2 "NWrnngPrssTrPrssrIsWthnThThrshl" 1 "OvrPrssTrPrssrIsHghrThnThPrssrD" 0 "ExtrmOvrPrssTrPrssrIsAtALvlWhrT" ;
VAL_ 2566845694 TirePressThresholdDetection_22 7 "NotAvailable" 6 "ErrorIndicator" 5 "NotDefined" 4 "ExtrmUndrPrssTrPrssrIsAtALvlWhr" 3 "UndrPrssTrPrssrIsLwrThnThPrssrD" 2 "NWrnngPrssTrPrssrIsWthnThThrshl" 1 "OvrPrssTrPrssrIsHghrThnThPrssrD" 0 "ExtrmOvrPrssTrPrssrIsAtALvlWhrT" ;
VAL_ 2566845694 TirePressThresholdDetection_23 7 "NotAvailable" 6 "ErrorIndicator" 5 "NotDefined" 4 "ExtrmUndrPrssTrPrssrIsAtALvlWhr" 3 "UndrPrssTrPrssrIsLwrThnThPrssrD" 2 "NWrnngPrssTrPrssrIsWthnThThrshl" 1 "OvrPrssTrPrssrIsHghrThnThPrssrD" 0 "ExtrmOvrPrssTrPrssrIsAtALvlWhrT" ;
VAL_ 2566845694 TirePressThresholdDetection_30 7 "NotAvailable" 6 "ErrorIndicator" 5 "NotDefined" 4 "ExtrmUndrPrssTrPrssrIsAtALvlWhr" 3 "UndrPrssTrPrssrIsLwrThnThPrssrD" 2 "NWrnngPrssTrPrssrIsWthnThThrshl" 1 "OvrPrssTrPrssrIsHghrThnThPrssrD" 0 "ExtrmOvrPrssTrPrssrIsAtALvlWhrT" ;
VAL_ 2566845694 TirePressThresholdDetection_31 7 "NotAvailable" 6 "ErrorIndicator" 5 "NotDefined" 4 "ExtrmUndrPrssTrPrssrIsAtALvlWhr" 3 "UndrPrssTrPrssrIsLwrThnThPrssrD" 2 "NWrnngPrssTrPrssrIsWthnThThrshl" 1 "OvrPrssTrPrssrIsHghrThnThPrssrD" 0 "ExtrmOvrPrssTrPrssrIsAtALvlWhrT" ;
VAL_ 2566845694 TirePressThresholdDetection_32 7 "NotAvailable" 6 "ErrorIndicator" 5 "NotDefined" 4 "ExtrmUndrPrssTrPrssrIsAtALvlWhr" 3 "UndrPrssTrPrssrIsLwrThnThPrssrD" 2 "NWrnngPrssTrPrssrIsWthnThThrshl" 1 "OvrPrssTrPrssrIsHghrThnThPrssrD" 0 "ExtrmOvrPrssTrPrssrIsAtALvlWhrT" ;
VAL_ 2566845694 TirePressThresholdDetection_33 7 "NotAvailable" 6 "ErrorIndicator" 5 "NotDefined" 4 "ExtrmUndrPrssTrPrssrIsAtALvlWhr" 3 "UndrPrssTrPrssrIsLwrThnThPrssrD" 2 "NWrnngPrssTrPrssrIsWthnThThrshl" 1 "OvrPrssTrPrssrIsHghrThnThPrssrD" 0 "ExtrmOvrPrssTrPrssrIsAtALvlWhrT" ;
VAL_ 2566742270 FailureModeIdentifier1 31 "Not available" 19 "Received network data in error" 18 "Below normal (moderately severe)" 17 "Below normal (least severe)" 16 "Above normal (moderately severe)" 15 "Above normal (least severe)" 14 "Special intstructions" 13 "Out of calibration" 12 "Bad intelligent device" 11 "Root cause not known" 10 "Abnormal rate of change" 9 "Abnormal update rate" 8 "Abnormal frequency" 7 "Mechanical system not responding" 6 "Current above normal" 5 "Current below normal" 4 "Voltage below normal" 3 "Voltage above normal" 2 "Data erratic" 1 "Below normal (most severe)" 0 "Above normal (most severe)" ;
VAL_ 2560687870 MnfcNOxNTECarveOutAreaStatus 3 "NotAvailable" 2 "Reserved" 1 "InsideControlArea" 0 "OutsideControlArea" ;
VAL_ 2560687870 MnfcPMNTECarveOutAreaStatus 3 "NotAvailable" 2 "Reserved" 1 "InsideControlArea" 0 "OutsideControlArea" ;
VAL_ 2560687870 NOxNTEControlAreaStatus 3 "NotAvailable" 2 "Reserved" 1 "InsideControlArea" 0 "OutsideControlArea" ;
VAL_ 2560687870 NOxNTEDeficiencyAreaStatus 3 "NotAvailable" 2 "Reserved" 1 "InsideControlArea" 0 "OutsideControlArea" ;
VAL_ 2560687870 PMNTEControlAreaStatus 3 "NotAvailable" 2 "Reserved" 1 "InsideControlArea" 0 "OutsideControlArea" ;
VAL_ 2560687870 PMNTEDeficiencyAreaStatus 3 "NotAvailable" 2 "Reserved" 1 "InsideControlArea" 0 "OutsideControlArea" ;
VAL_ 2560884478 DTCMilSupportFlash 3 "Unavailable" 2 "Class_C_DTC" 1 "FastFlash" 0 "SlowFlash" ;
VAL_ 2560884478 DTCMilSupportStatus 3 "Unavailable" 2 "ShortMI" 1 "LampOn" 0 "LampOff" ;
VAL_ 2560884478 DTCProtectLampSupportFlash 3 "Unavailable" 2 "Reserved" 1 "FastFlash" 0 "SlowFlash" ;
VAL_ 2560884478 DTCProtectLampSupportStatus 3 "Unavailable" 2 "Reserved" 1 "LampOn" 0 "LampOff" ;
VAL_ 2560884478 DTCStopLampSupportFlash 3 "Unavailable" 2 "Reserved" 1 "FastFlash" 0 "SlowFlash" ;
VAL_ 2560884478 DTCStopLampSupportStatus 3 "Unavailable" 2 "Reserved" 1 "LampOn" 0 "LampOff" ;
VAL_ 2560884478 DTCWarnLampSupportFlash 3 "Unavailable" 2 "Reserved" 1 "FastFlash" 0 "SlowFlash" ;
VAL_ 2560884478 DTCWarnLampSupportStatus 3 "Unavailable" 2 "Reserved" 1 "LampOn" 0 "LampOff" ;
VAL_ 2560950014 FailureModeIdentifier1 31 "Not available" 19 "Received network data in error" 18 "Below normal (moderately severe)" 17 "Below normal (least severe)" 16 "Above normal (moderately severe)" 15 "Above normal (least severe)" 14 "Special intstructions" 13 "Out of calibration" 12 "Bad intelligent device" 11 "Root cause not known" 10 "Abnormal rate of change" 9 "Abnormal update rate" 8 "Abnormal frequency" 7 "Mechanical system not responding" 6 "Current above normal" 5 "Current below normal" 4 "Voltage below normal" 3 "Voltage above normal" 2 "Data erratic" 1 "Below normal (most severe)" 0 "Above normal (most severe)" ;
VAL_ 2566836478 TestIdentifier 250 "Last Measured Scaled Results" 249 "Command Standard Test" 247 "All scaled test results" ;
VAL_ 2565078782 FailureModeIdentifier1 31 "Not available" 19 "Received network data in error" 18 "Below normal (moderately severe)" 17 "Below normal (least severe)" 16 "Above normal (moderately severe)" 15 "Above normal (least severe)" 14 "Special intstructions" 13 "Out of calibration" 12 "Bad intelligent device" 11 "Root cause not known" 10 "Abnormal rate of change" 9 "Abnormal update rate" 8 "Abnormal frequency" 7 "Mechanical system not responding" 6 "Current above normal" 5 "Current below normal" 4 "Voltage below normal" 3 "Voltage above normal" 2 "Data erratic" 1 "Below normal (most severe)" 0 "Above normal (most severe)" ;
VAL_ 2565078782 TestIdentifier 250 "Last Measured Scaled Results" 249 "Command Standard Test" 247 "All scaled test results" ;
VAL_ 2566836222 AmberWarningLampStatus 3 "Not available" 2 "Reserved" 1 "Lamp On" 0 "Lamp Off" ;
VAL_ 2566836222 FlashAmberWarningLamp 3 "Unavailable / Do Not Flash" 2 "Reserved" 1 "Fast Flash" 0 "Slow Flash" ;
VAL_ 2566836222 FlashMalfuncIndicatorLamp 3 "Unavailable / Do Not Flash" 2 "Class C DTC  " 1 "Fast Flash" 0 "Slow Flash" ;
VAL_ 2566836222 FlashProtectLamp 3 "Unavailable / Do Not Flash" 2 "Reserved" 1 "Fast Flash" 0 "Slow Flash" ;
VAL_ 2566836222 FlashRedStopLamp 3 "Unavailable / Do Not Flash" 2 "Reserved" 1 "Fast Flash" 0 "Slow Flash" ;
VAL_ 2566836222 MalfunctionIndicatorLampStatus 3 "Not available" 2 "Short MIL for WWH OBD" 1 "Lamp On" 0 "Lamp Off" ;
VAL_ 2566836222 ProtectLampStatus 3 "Not available" 2 "Reserved" 1 "Lamp On" 0 "Lamp Off" ;
VAL_ 2566836222 RedStopLampState 3 "Not available" 2 "Reserved" 1 "Lamp On" 0 "Lamp Off" ;
VAL_ 2566835966 ACSystemRefrigerantMonStatus 1 "TestNotComplete" 0 "TestComplete" ;
VAL_ 2566835966 ACSystemRefrigerantMonSupp 1 "TestSupported" 0 "TestNotSupported" ;
VAL_ 2566835966 CatalystMonStatus 0 "TestComplete" 1 "TestNotComplete" ;
VAL_ 2566835966 CatalystMonSupp 1 "TestSupported" 0 "TestNotSupported" ;
VAL_ 2566835966 ColdStartAidSystemMonStatus 1 "TestNotComplete" 0 "TestComplete" ;
VAL_ 2566835966 ColdStartAidSystemMonSupp 1 "TestSupported" 0 "TestNotSupported" ;
VAL_ 2566835966 ComprehensiveCompMonStatus 1 "test not complete" 0 "test complete" ;
VAL_ 2566835966 ComprehensiveComponentMonSupp 3 "Not available" 2 "Reserved" 1 "test supported" 0 "test not supported" ;
VAL_ 2566835966 EGRSystemMonitoringStatus 1 "TestNotComplete" 0 "TestComplete" ;
VAL_ 2566835966 EGRSystemMonitoringSupp 1 "TestSupported" 0 "TestNotSupported" ;
VAL_ 2566835966 EvaporativeSystemMonStatus 1 "TestNotComplete" 0 "TestComplete" ;
VAL_ 2566835966 EvaporativeSystemMonSupp 1 "TestSupported" 0 "TestNotSupported" ;
VAL_ 2566835966 FuelSystemMonitoringStatus 1 "test not complete" 0 "test complete" ;
VAL_ 2566835966 FuelSystemMonitoringSupport 1 "test supported" 0 "test not supported" ;
VAL_ 2566835966 HeatedCatalystMonStatus 1 "TestNotComplete" 0 "TestComplete" ;
VAL_ 2566835966 HeatedCatalystMonSupp 1 "TestSupported" 0 "TestNotSupported" ;
VAL_ 2566835966 MisfireMonitoringStatus 1 "test not complete" 0 "test complete" ;
VAL_ 2566835966 MisfireMonitoringSupport 3 "Not available" 2 "Reserved" 1 "test supported" 0 "test not supported" ;
VAL_ 2566835966 OBDCompliance 10 "JOBD" 11 "JOBD and OBD II" 12 "JOBD and EOBD" 13 "JOBD, EOBD and OBD II" 14 "Heavy Duty Vehicles (EURO IV) B1" 15 "Heavy Duty Vehicles (EURO V) B2" 16 "Heavy Duty Vehicles (EURO EEC) C" 17 "EMD" 18 "EMD+" 19 "HD OBD P" 20 "HD OBD" 21 "WWH OBD" 22 "OBD II (California, ARB 07/08)" 23 "HD EOBD" 25 "OBD-M (SI-SD/I)" 6 "EOBD" 7 "EOBD and OBD II" 8 "EOBD and OBD" 9 "EOBD, OBD and OBD II" 5 "Not intended to meet OBD II req." 4 "OBD I" 3 "OBD and OBD II" 2 "OBD (Federal, EPA)" 1 "OBD II (California, ARB)" 0 "Reserver for assignment by SAE" ;
VAL_ 2566835966 OxygenSensorHeaterMonStatus 1 "TestNotComplete" 0 "TestComplete" ;
VAL_ 2566835966 OxygenSensorHeaterMonSupp 1 "TestSupported" 0 "TestNotSupported" ;
VAL_ 2566835966 OxygenSensorMonStatus 1 "test not complete" 0 "test complete" ;
VAL_ 2566835966 OxygenSensorMonSupp 1 "TestSupported" 0 "TestNotSupported" ;
VAL_ 2566835966 SecondAirSystemMonStatus 1 "TestNotComplete" 0 "TestComplete" ;
VAL_ 2566835966 SecondAirSystemMonSupp 1 "TestSupported" 0 "TestNotSupported" ;
VAL_ 2566764286 SPNSupportTypeDS1 1 "Not Supported In Data Stream" 0 "Supported In Data Stream" ;
VAL_ 2566764286 SPNSupportTypeDS2 1 "Not Supported In Data Stream" 0 "Supported In Data Stream" ;
VAL_ 2566764286 SPNSupportTypeDS3 1 "Not Supported In Data Stream" 0 "Supported In Data Stream" ;
VAL_ 2566764286 SPNSupportTypeEFF1 1 "Not Supported In Ex Freeze Frame" 0 "Supported In Ex Freeze Frame" ;
VAL_ 2566764286 SPNSupportTypeEFF2 1 "Not Supported In Ex Freeze Frame" 0 "Supported In Ex Freeze Frame" ;
VAL_ 2566764286 SPNSupportTypeEFF3 1 "Not Supported In Ex Freeze Frame" 0 "Supported In Ex Freeze Frame" ;
VAL_ 2566764286 SPNSupportTypeSTR1 1 "Not Supported In Scaled Test Results" 0 "Supported In Scaled Test Results" ;
VAL_ 2566764286 SPNSupportTypeSTR2 1 "Not Supported In Scaled Test Results" 0 "Supported In Scaled Test Results" ;
VAL_ 2566764286 SPNSupportTypeSTR3 1 "Not Supported In Scaled Test Results" 0 "Supported In Scaled Test Results" ;
VAL_ 2566764030 AmberWarningLampStatus 3 "Not available" 2 "Reserved" 1 "Lamp On" 0 "Lamp Off" ;
VAL_ 2566764030 FlashAmberWarningLamp 3 "Unavailable / Do Not Flash" 2 "Reserved" 1 "Fast Flash" 0 "Slow Flash" ;
VAL_ 2566764030 FlashMalfuncIndicatorLamp 3 "Unavailable / Do Not Flash" 2 "Class C DTC  " 1 "Fast Flash" 0 "Slow Flash" ;
VAL_ 2566764030 FlashProtectLamp 3 "Unavailable / Do Not Flash" 2 "Reserved" 1 "Fast Flash" 0 "Slow Flash" ;
VAL_ 2566764030 FlashRedStopLamp 3 "Unavailable / Do Not Flash" 2 "Reserved" 1 "Fast Flash" 0 "Slow Flash" ;
VAL_ 2566764030 MalfunctionIndicatorLampStatus 3 "Not available" 2 "Short MIL for WWH OBD" 1 "Lamp On" 0 "Lamp Off" ;
VAL_ 2566764030 ProtectLampStatus 3 "Not available" 2 "Reserved" 1 "Lamp On" 0 "Lamp Off" ;
VAL_ 2566764030 RedStopLampState 3 "Not available" 2 "Reserved" 1 "Lamp On" 0 "Lamp Off" ;
